VERSION ""

NS_ :

BS_:

BU_: VT OPC

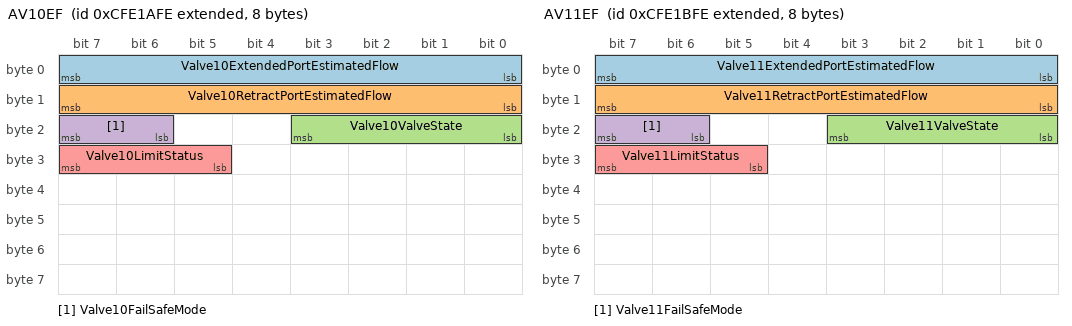
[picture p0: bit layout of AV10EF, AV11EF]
BO_ 2365463294 AV10EF: 8 Vector__XXX
 SG_ Valve10ExtendedPortEstimatedFlow : 0|8@1+ (1,-125) [-125|125] "%" Vector__XXX
 SG_ Valve10RetractPortEstimatedFlow : 8|8@1+ (1,-125) [-125|125] "%" Vector__XXX
 SG_ Valve10ValveState : 16|4@1+ (1,0) [0|15] "" Vector__XXX
 SG_ Valve10FailSafeMode : 22|2@1+ (1,0) [0|3] "" Vector__XXX
 SG_ Valve10LimitStatus : 29|3@1+ (1,0) [0|7] "" Vector__XXX

BO_ 2365463550 AV11EF: 8 Vector__XXX
 SG_ Valve11ExtendedPortEstimatedFlow : 0|8@1+ (1,-125) [-125|125] "%" Vector__XXX
 SG_ Valve11RetractPortEstimatedFlow : 8|8@1+ (1,-125) [-125|125] "%" Vector__XXX
 SG_ Valve11ValveState : 16|4@1+ (1,0) [0|15] "" Vector__XXX
 SG_ Valve11FailSafeMode : 22|2@1+ (1,0) [0|3] "" Vector__XXX
 SG_ Valve11LimitStatus : 29|3@1+ (1,0) [0|7] "" Vector__XXX

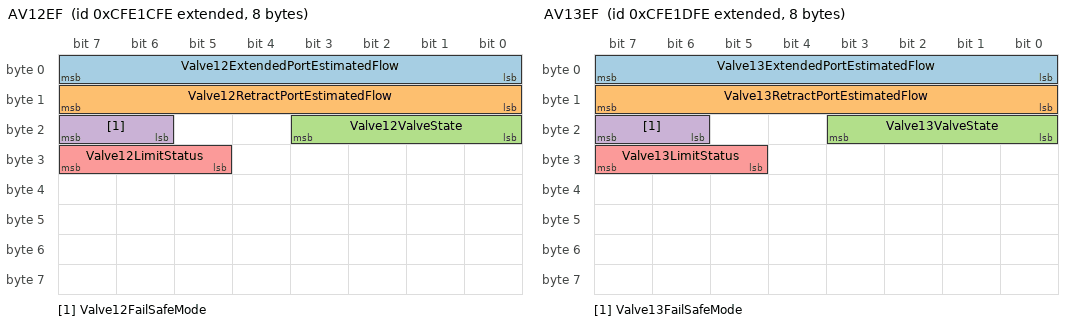
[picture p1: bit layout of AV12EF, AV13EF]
BO_ 2365463806 AV12EF: 8 Vector__XXX
 SG_ Valve12ExtendedPortEstimatedFlow : 0|8@1+ (1,-125) [-125|125] "%" Vector__XXX
 SG_ Valve12RetractPortEstimatedFlow : 8|8@1+ (1,-125) [-125|125] "%" Vector__XXX
 SG_ Valve12ValveState : 16|4@1+ (1,0) [0|15] "" Vector__XXX
 SG_ Valve12FailSafeMode : 22|2@1+ (1,0) [0|3] "" Vector__XXX
 SG_ Valve12LimitStatus : 29|3@1+ (1,0) [0|7] "" Vector__XXX

BO_ 2365464062 AV13EF: 8 Vector__XXX
 SG_ Valve13ExtendedPortEstimatedFlow : 0|8@1+ (1,-125) [-125|125] "%" Vector__XXX
 SG_ Valve13RetractPortEstimatedFlow : 8|8@1+ (1,-125) [-125|125] "%" Vector__XXX
 SG_ Valve13ValveState : 16|4@1+ (1,0) [0|15] "" Vector__XXX
 SG_ Valve13FailSafeMode : 22|2@1+ (1,0) [0|3] "" Vector__XXX
 SG_ Valve13LimitStatus : 29|3@1+ (1,0) [0|7] "" Vector__XXX

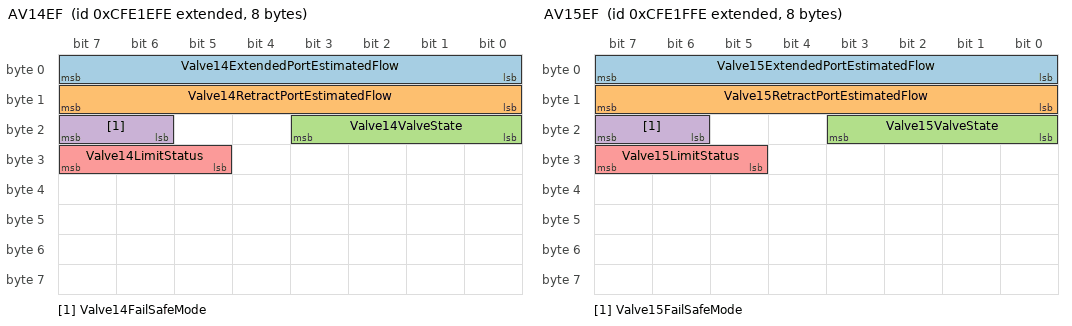
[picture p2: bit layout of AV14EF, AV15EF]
BO_ 2365464318 AV14EF: 8 Vector__XXX
 SG_ Valve14ExtendedPortEstimatedFlow : 0|8@1+ (1,-125) [-125|125] "%" Vector__XXX
 SG_ Valve14RetractPortEstimatedFlow : 8|8@1+ (1,-125) [-125|125] "%" Vector__XXX
 SG_ Valve14ValveState : 16|4@1+ (1,0) [0|15] "" Vector__XXX
 SG_ Valve14FailSafeMode : 22|2@1+ (1,0) [0|3] "" Vector__XXX
 SG_ Valve14LimitStatus : 29|3@1+ (1,0) [0|7] "" Vector__XXX

BO_ 2365464574 AV15EF: 8 Vector__XXX
 SG_ Valve15ExtendedPortEstimatedFlow : 0|8@1+ (1,-125) [-125|125] "%" Vector__XXX
 SG_ Valve15RetractPortEstimatedFlow : 8|8@1+ (1,-125) [-125|125] "%" Vector__XXX
 SG_ Valve15ValveState : 16|4@1+ (1,0) [0|15] "" Vector__XXX
 SG_ Valve15FailSafeMode : 22|2@1+ (1,0) [0|3] "" Vector__XXX
 SG_ Valve15LimitStatus : 29|3@1+ (1,0) [0|7] "" Vector__XXX

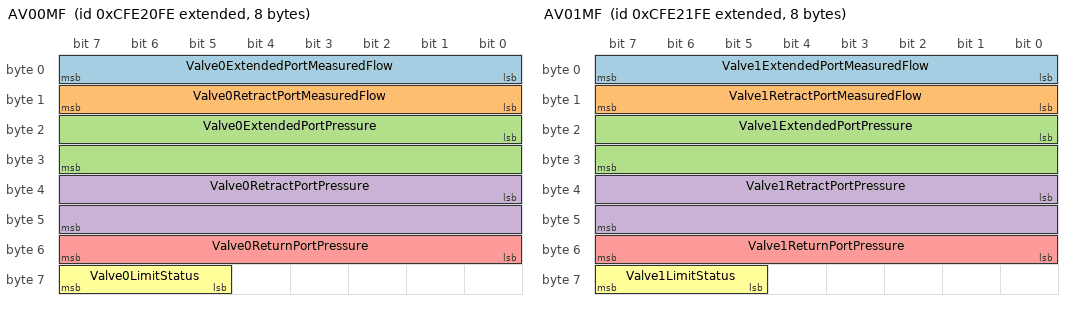
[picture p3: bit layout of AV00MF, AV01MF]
BO_ 2365464830 AV00MF: 8 Vector__XXX
 SG_ Valve0ExtendedPortMeasuredFlow : 0|8@1+ (1,-125) [-125|125] "%" Vector__XXX
 SG_ Valve0RetractPortMeasuredFlow : 8|8@1+ (1,-125) [-125|125] "%" Vector__XXX
 SG_ Valve0ExtendedPortPressure : 16|16@1+ (5,0) [0|321275] "kPa" Vector__XXX
 SG_ Valve0RetractPortPressure : 32|16@1+ (5,0) [0|321275] "kPa" Vector__XXX
 SG_ Valve0ReturnPortPressure : 48|8@1+ (16,0) [0|4000] "kPa" Vector__XXX
 SG_ Valve0LimitStatus : 61|3@1+ (1,0) [0|7] "" Vector__XXX

BO_ 2365465086 AV01MF: 8 Vector__XXX
 SG_ Valve1ExtendedPortMeasuredFlow : 0|8@1+ (1,-125) [-125|125] "%" Vector__XXX
 SG_ Valve1RetractPortMeasuredFlow : 8|8@1+ (1,-125) [-125|125] "%" Vector__XXX
 SG_ Valve1ExtendedPortPressure : 16|16@1+ (5,0) [0|321275] "kPa" Vector__XXX
 SG_ Valve1RetractPortPressure : 32|16@1+ (5,0) [0|321275] "kPa" Vector__XXX
 SG_ Valve1ReturnPortPressure : 48|8@1+ (16,0) [0|4000] "kPa" Vector__XXX
 SG_ Valve1LimitStatus : 61|3@1+ (1,0) [0|7] "" Vector__XXX

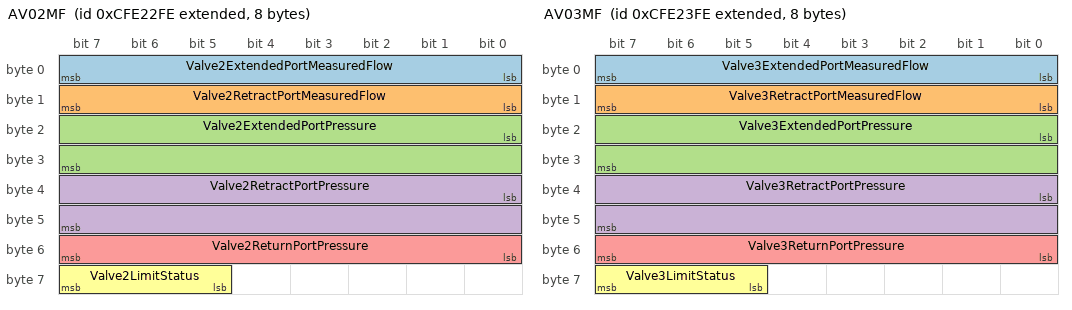
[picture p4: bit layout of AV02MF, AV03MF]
BO_ 2365465342 AV02MF: 8 Vector__XXX
 SG_ Valve2ExtendedPortMeasuredFlow : 0|8@1+ (1,-125) [-125|125] "%" Vector__XXX
 SG_ Valve2RetractPortMeasuredFlow : 8|8@1+ (1,-125) [-125|125] "%" Vector__XXX
 SG_ Valve2ExtendedPortPressure : 16|16@1+ (5,0) [0|321275] "kPa" Vector__XXX
 SG_ Valve2RetractPortPressure : 32|16@1+ (5,0) [0|321275] "kPa" Vector__XXX
 SG_ Valve2ReturnPortPressure : 48|8@1+ (16,0) [0|4000] "kPa" Vector__XXX
 SG_ Valve2LimitStatus : 61|3@1+ (1,0) [0|7] "" Vector__XXX

BO_ 2365465598 AV03MF: 8 Vector__XXX
 SG_ Valve3ExtendedPortMeasuredFlow : 0|8@1+ (1,-125) [-125|125] "%" Vector__XXX
 SG_ Valve3RetractPortMeasuredFlow : 8|8@1+ (1,-125) [-125|125] "%" Vector__XXX
 SG_ Valve3ExtendedPortPressure : 16|16@1+ (5,0) [0|321275] "kPa" Vector__XXX
 SG_ Valve3RetractPortPressure : 32|16@1+ (5,0) [0|321275] "kPa" Vector__XXX
 SG_ Valve3ReturnPortPressure : 48|8@1+ (16,0) [0|4000] "kPa" Vector__XXX
 SG_ Valve3LimitStatus : 61|3@1+ (1,0) [0|7] "" Vector__XXX

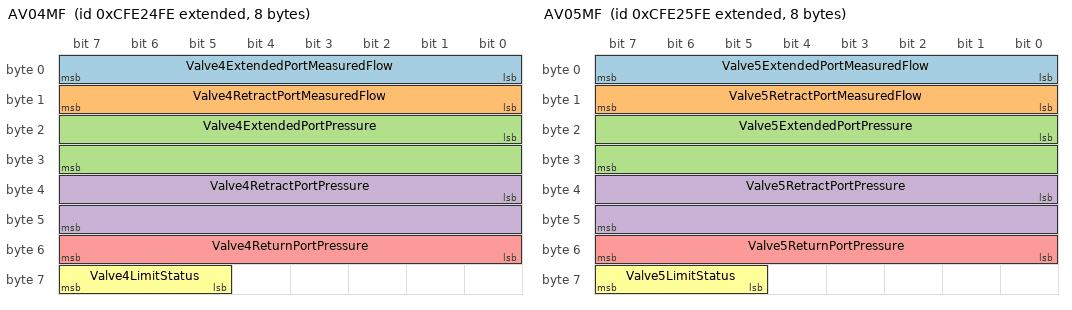
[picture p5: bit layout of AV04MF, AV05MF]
BO_ 2365465854 AV04MF: 8 Vector__XXX
 SG_ Valve4ExtendedPortMeasuredFlow : 0|8@1+ (1,-125) [-125|125] "%" Vector__XXX
 SG_ Valve4RetractPortMeasuredFlow : 8|8@1+ (1,-125) [-125|125] "%" Vector__XXX
 SG_ Valve4ExtendedPortPressure : 16|16@1+ (5,0) [0|321275] "kPa" Vector__XXX
 SG_ Valve4RetractPortPressure : 32|16@1+ (5,0) [0|321275] "kPa" Vector__XXX
 SG_ Valve4ReturnPortPressure : 48|8@1+ (16,0) [0|4000] "kPa" Vector__XXX
 SG_ Valve4LimitStatus : 61|3@1+ (1,0) [0|7] "" Vector__XXX

BO_ 2365466110 AV05MF: 8 Vector__XXX
 SG_ Valve5ExtendedPortMeasuredFlow : 0|8@1+ (1,-125) [-125|125] "%" Vector__XXX
 SG_ Valve5RetractPortMeasuredFlow : 8|8@1+ (1,-125) [-125|125] "%" Vector__XXX
 SG_ Valve5ExtendedPortPressure : 16|16@1+ (5,0) [0|321275] "kPa" Vector__XXX
 SG_ Valve5RetractPortPressure : 32|16@1+ (5,0) [0|321275] "kPa" Vector__XXX
 SG_ Valve5ReturnPortPressure : 48|8@1+ (16,0) [0|4000] "kPa" Vector__XXX
 SG_ Valve5LimitStatus : 61|3@1+ (1,0) [0|7] "" Vector__XXX

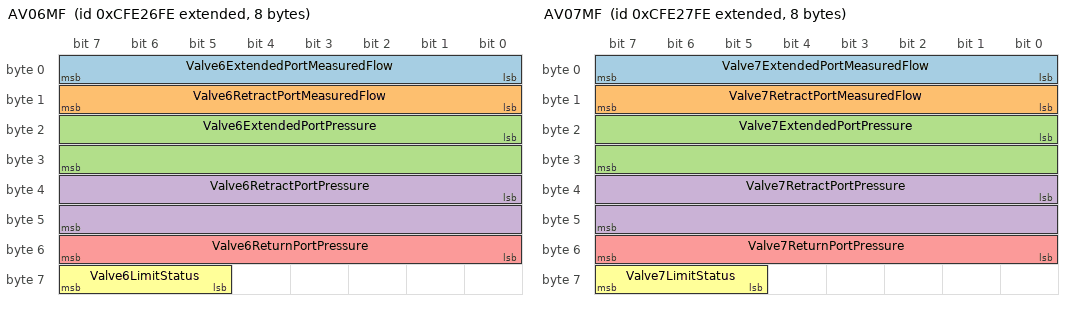
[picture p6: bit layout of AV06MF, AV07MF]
BO_ 2365466366 AV06MF: 8 Vector__XXX
 SG_ Valve6ExtendedPortMeasuredFlow : 0|8@1+ (1,-125) [-125|125] "%" Vector__XXX
 SG_ Valve6RetractPortMeasuredFlow : 8|8@1+ (1,-125) [-125|125] "%" Vector__XXX
 SG_ Valve6ExtendedPortPressure : 16|16@1+ (5,0) [0|321275] "kPa" Vector__XXX
 SG_ Valve6RetractPortPressure : 32|16@1+ (5,0) [0|321275] "kPa" Vector__XXX
 SG_ Valve6ReturnPortPressure : 48|8@1+ (16,0) [0|4000] "kPa" Vector__XXX
 SG_ Valve6LimitStatus : 61|3@1+ (1,0) [0|7] "" Vector__XXX

BO_ 2365466622 AV07MF: 8 Vector__XXX
 SG_ Valve7ExtendedPortMeasuredFlow : 0|8@1+ (1,-125) [-125|125] "%" Vector__XXX
 SG_ Valve7RetractPortMeasuredFlow : 8|8@1+ (1,-125) [-125|125] "%" Vector__XXX
 SG_ Valve7ExtendedPortPressure : 16|16@1+ (5,0) [0|321275] "kPa" Vector__XXX
 SG_ Valve7RetractPortPressure : 32|16@1+ (5,0) [0|321275] "kPa" Vector__XXX
 SG_ Valve7ReturnPortPressure : 48|8@1+ (16,0) [0|4000] "kPa" Vector__XXX
 SG_ Valve7LimitStatus : 61|3@1+ (1,0) [0|7] "" Vector__XXX

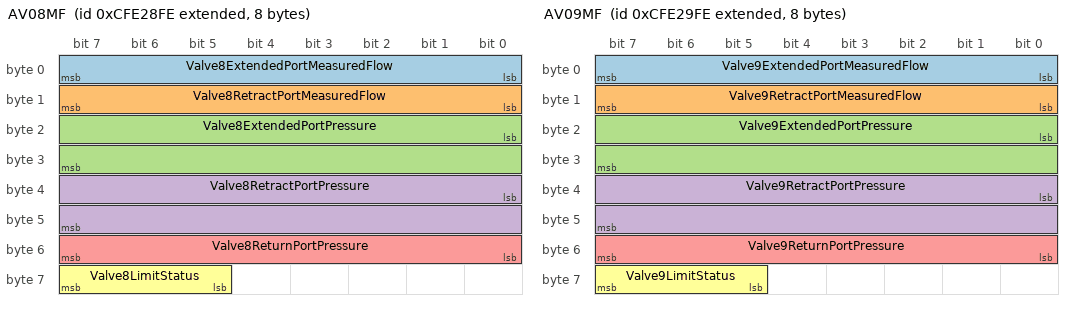
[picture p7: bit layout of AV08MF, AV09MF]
BO_ 2365466878 AV08MF: 8 Vector__XXX
 SG_ Valve8ExtendedPortMeasuredFlow : 0|8@1+ (1,-125) [-125|125] "%" Vector__XXX
 SG_ Valve8RetractPortMeasuredFlow : 8|8@1+ (1,-125) [-125|125] "%" Vector__XXX
 SG_ Valve8ExtendedPortPressure : 16|16@1+ (5,0) [0|321275] "kPa" Vector__XXX
 SG_ Valve8RetractPortPressure : 32|16@1+ (5,0) [0|321275] "kPa" Vector__XXX
 SG_ Valve8ReturnPortPressure : 48|8@1+ (16,0) [0|4000] "kPa" Vector__XXX
 SG_ Valve8LimitStatus : 61|3@1+ (1,0) [0|7] "" Vector__XXX

BO_ 2365467134 AV09MF: 8 Vector__XXX
 SG_ Valve9ExtendedPortMeasuredFlow : 0|8@1+ (1,-125) [-125|125] "%" Vector__XXX
 SG_ Valve9RetractPortMeasuredFlow : 8|8@1+ (1,-125) [-125|125] "%" Vector__XXX
 SG_ Valve9ExtendedPortPressure : 16|16@1+ (5,0) [0|321275] "kPa" Vector__XXX
 SG_ Valve9RetractPortPressure : 32|16@1+ (5,0) [0|321275] "kPa" Vector__XXX
 SG_ Valve9ReturnPortPressure : 48|8@1+ (16,0) [0|4000] "kPa" Vector__XXX
 SG_ Valve9LimitStatus : 61|3@1+ (1,0) [0|7] "" Vector__XXX

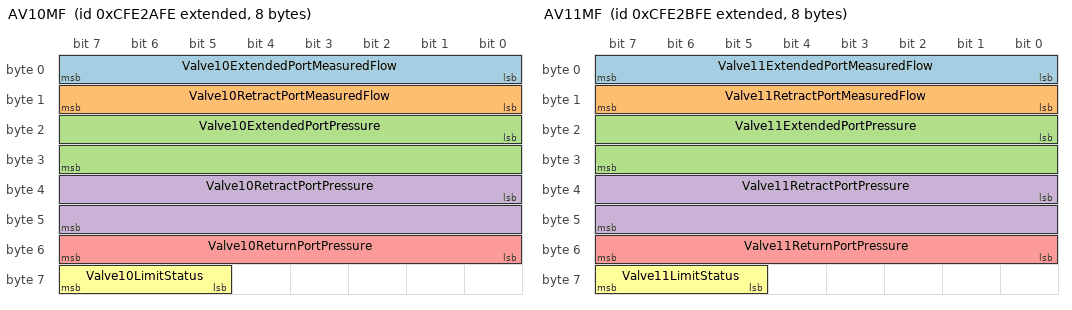
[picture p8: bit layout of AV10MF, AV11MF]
BO_ 2365467390 AV10MF: 8 Vector__XXX
 SG_ Valve10ExtendedPortMeasuredFlow : 0|8@1+ (1,-125) [-125|125] "%" Vector__XXX
 SG_ Valve10RetractPortMeasuredFlow : 8|8@1+ (1,-125) [-125|125] "%" Vector__XXX
 SG_ Valve10ExtendedPortPressure : 16|16@1+ (5,0) [0|321275] "kPa" Vector__XXX
 SG_ Valve10RetractPortPressure : 32|16@1+ (5,0) [0|321275] "kPa" Vector__XXX
 SG_ Valve10ReturnPortPressure : 48|8@1+ (16,0) [0|4000] "kPa" Vector__XXX
 SG_ Valve10LimitStatus : 61|3@1+ (1,0) [0|7] "" Vector__XXX

BO_ 2365467646 AV11MF: 8 Vector__XXX
 SG_ Valve11ExtendedPortMeasuredFlow : 0|8@1+ (1,-125) [-125|125] "%" Vector__XXX
 SG_ Valve11RetractPortMeasuredFlow : 8|8@1+ (1,-125) [-125|125] "%" Vector__XXX
 SG_ Valve11ExtendedPortPressure : 16|16@1+ (5,0) [0|321275] "kPa" Vector__XXX
 SG_ Valve11RetractPortPressure : 32|16@1+ (5,0) [0|321275] "kPa" Vector__XXX
 SG_ Valve11ReturnPortPressure : 48|8@1+ (16,0) [0|4000] "kPa" Vector__XXX
 SG_ Valve11LimitStatus : 61|3@1+ (1,0) [0|7] "" Vector__XXX

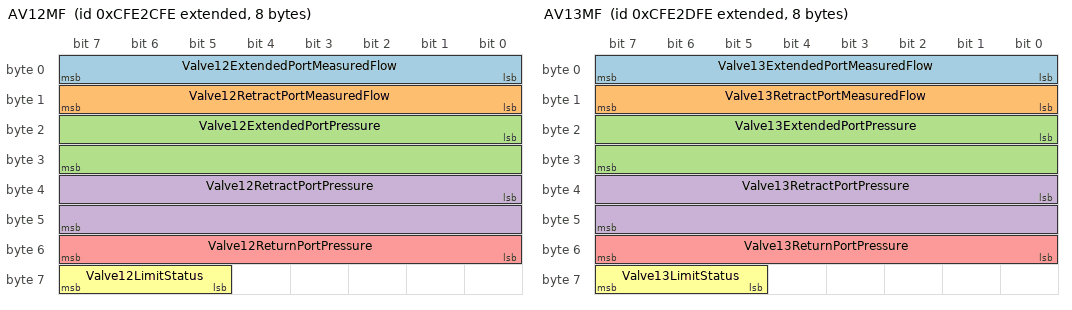
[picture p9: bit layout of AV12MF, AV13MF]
BO_ 2365467902 AV12MF: 8 Vector__XXX
 SG_ Valve12ExtendedPortMeasuredFlow : 0|8@1+ (1,-125) [-125|125] "%" Vector__XXX
 SG_ Valve12RetractPortMeasuredFlow : 8|8@1+ (1,-125) [-125|125] "%" Vector__XXX
 SG_ Valve12ExtendedPortPressure : 16|16@1+ (5,0) [0|321275] "kPa" Vector__XXX
 SG_ Valve12RetractPortPressure : 32|16@1+ (5,0) [0|321275] "kPa" Vector__XXX
 SG_ Valve12ReturnPortPressure : 48|8@1+ (16,0) [0|4000] "kPa" Vector__XXX
 SG_ Valve12LimitStatus : 61|3@1+ (1,0) [0|7] "" Vector__XXX

BO_ 2365468158 AV13MF: 8 Vector__XXX
 SG_ Valve13ExtendedPortMeasuredFlow : 0|8@1+ (1,-125) [-125|125] "%" Vector__XXX
 SG_ Valve13RetractPortMeasuredFlow : 8|8@1+ (1,-125) [-125|125] "%" Vector__XXX
 SG_ Valve13ExtendedPortPressure : 16|16@1+ (5,0) [0|321275] "kPa" Vector__XXX
 SG_ Valve13RetractPortPressure : 32|16@1+ (5,0) [0|321275] "kPa" Vector__XXX
 SG_ Valve13ReturnPortPressure : 48|8@1+ (16,0) [0|4000] "kPa" Vector__XXX
 SG_ Valve13LimitStatus : 61|3@1+ (1,0) [0|7] "" Vector__XXX

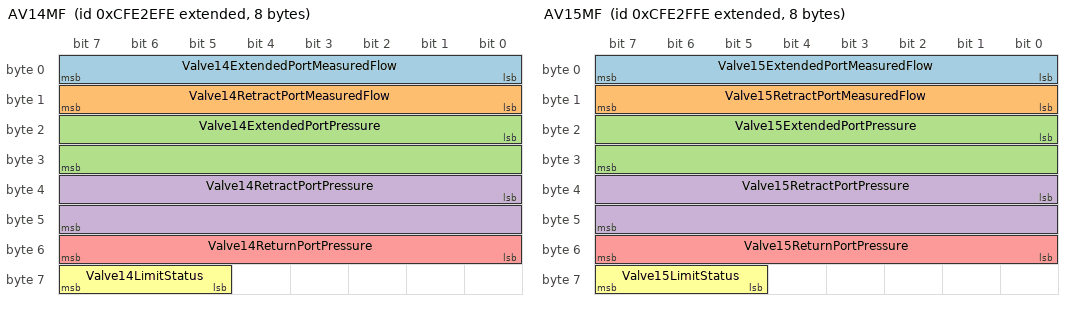
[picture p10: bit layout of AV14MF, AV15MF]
BO_ 2365468414 AV14MF: 8 Vector__XXX
 SG_ Valve14ExtendedPortMeasuredFlow : 0|8@1+ (1,-125) [-125|125] "%" Vector__XXX
 SG_ Valve14RetractPortMeasuredFlow : 8|8@1+ (1,-125) [-125|125] "%" Vector__XXX
 SG_ Valve14ExtendedPortPressure : 16|16@1+ (5,0) [0|321275] "kPa" Vector__XXX
 SG_ Valve14RetractPortPressure : 32|16@1+ (5,0) [0|321275] "kPa" Vector__XXX
 SG_ Valve14ReturnPortPressure : 48|8@1+ (16,0) [0|4000] "kPa" Vector__XXX
 SG_ Valve14LimitStatus : 61|3@1+ (1,0) [0|7] "" Vector__XXX

BO_ 2365468670 AV15MF: 8 Vector__XXX
 SG_ Valve15ExtendedPortMeasuredFlow : 0|8@1+ (1,-125) [-125|125] "%" Vector__XXX
 SG_ Valve15RetractPortMeasuredFlow : 8|8@1+ (1,-125) [-125|125] "%" Vector__XXX
 SG_ Valve15ExtendedPortPressure : 16|16@1+ (5,0) [0|321275] "kPa" Vector__XXX
 SG_ Valve15RetractPortPressure : 32|16@1+ (5,0) [0|321275] "kPa" Vector__XXX
 SG_ Valve15ReturnPortPressure : 48|8@1+ (16,0) [0|4000] "kPa" Vector__XXX
 SG_ Valve15LimitStatus : 61|3@1+ (1,0) [0|7] "" Vector__XXX

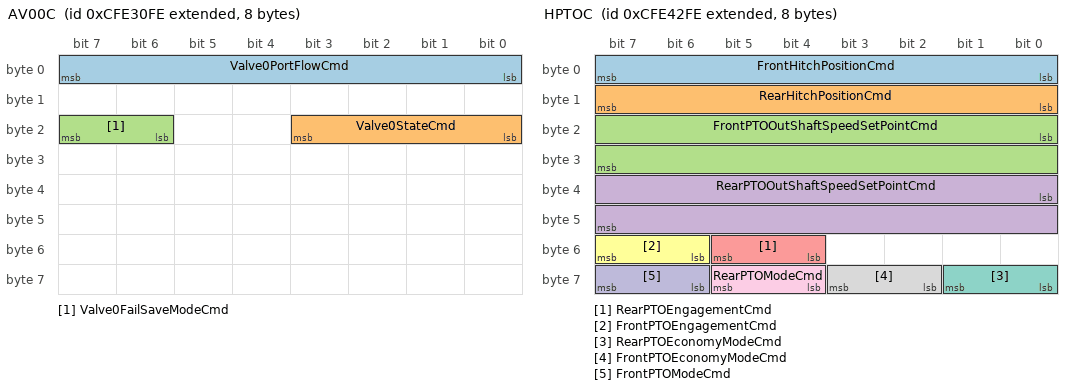
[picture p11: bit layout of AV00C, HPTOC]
BO_ 2365468926 AV00C: 8 Vector__XXX
 SG_ Valve0PortFlowCmd : 0|8@1+ (0.4,0) [0|100] "%" Vector__XXX
 SG_ Valve0StateCmd : 16|4@1+ (1,0) [0|15] "" Vector__XXX
 SG_ Valve0FailSaveModeCmd : 22|2@1+ (1,0) [0|3] "" Vector__XXX

BO_ 2365469182 AV01C: 8 Vector__XXX
 SG_ Valve1PortFlowCmd : 0|8@1+ (0.4,0) [0|100] "%" Vector__XXX
 SG_ Valve1StateCmd : 16|4@1+ (1,0) [0|15] "" Vector__XXX
 SG_ Valve1FailSaveModeCmd : 22|2@1+ (1,0) [0|3] "" Vector__XXX

BO_ 2365469438 AV02C: 8 Vector__XXX
 SG_ Valve2PortFlowCmd : 0|8@1+ (0.4,0) [0|100] "%" Vector__XXX
 SG_ Valve2StateCmd : 16|4@1+ (1,0) [0|15] "" Vector__XXX
 SG_ Valve2FailSaveModeCmd : 22|2@1+ (1,0) [0|3] "" Vector__XXX

BO_ 2365469694 AV03C: 8 Vector__XXX
 SG_ Valve3PortFlowCmd : 0|8@1+ (0.4,0) [0|100] "%" Vector__XXX
 SG_ Valve3StateCmd : 16|4@1+ (1,0) [0|15] "" Vector__XXX
 SG_ Valve3FailSaveModeCmd : 22|2@1+ (1,0) [0|3] "" Vector__XXX

BO_ 2365469950 AV04C: 8 Vector__XXX
 SG_ Valve4PortFlowCmd : 0|8@1+ (0.4,0) [0|100] "%" Vector__XXX
 SG_ Valve4StateCmd : 16|4@1+ (1,0) [0|15] "" Vector__XXX
 SG_ Valve4FailSaveModeCmd : 22|2@1+ (1,0) [0|3] "" Vector__XXX

BO_ 2365470206 AV05C: 8 Vector__XXX
 SG_ Valve5PortFlowCmd : 0|8@1+ (0.4,0) [0|100] "%" Vector__XXX
 SG_ Valve5StateCmd : 16|4@1+ (1,0) [0|15] "" Vector__XXX
 SG_ Valve5FailSaveModeCmd : 22|2@1+ (1,0) [0|3] "" Vector__XXX

BO_ 2365470462 AV06C: 8 Vector__XXX
 SG_ Valve6PortFlowCmd : 0|8@1+ (0.4,0) [0|100] "%" Vector__XXX
 SG_ Valve6StateCmd : 16|4@1+ (1,0) [0|15] "" Vector__XXX
 SG_ Valve6FailSaveModeCmd : 22|2@1+ (1,0) [0|3] "" Vector__XXX

BO_ 2365470718 AV07C: 8 Vector__XXX
 SG_ Valve7PortFlowCmd : 0|8@1+ (0.4,0) [0|100] "%" Vector__XXX
 SG_ Valve7StateCmd : 16|4@1+ (1,0) [0|15] "" Vector__XXX
 SG_ Valve7FailSaveModeCmd : 22|2@1+ (1,0) [0|3] "" Vector__XXX

BO_ 2365470974 AV08C: 8 Vector__XXX
 SG_ Valve8PortFlowCmd : 0|8@1+ (0.4,0) [0|100] "%" Vector__XXX
 SG_ Valve8StateCmd : 16|4@1+ (1,0) [0|15] "" Vector__XXX
 SG_ Valve8FailSaveModeCmd : 22|2@1+ (1,0) [0|3] "" Vector__XXX

BO_ 2365471230 AV09C: 8 Vector__XXX
 SG_ Valve9PortFlowCmd : 0|8@1+ (0.4,0) [0|100] "%" Vector__XXX
 SG_ Valve9StateCmd : 16|4@1+ (1,0) [0|15] "" Vector__XXX
 SG_ Valve9FailSaveModeCmd : 22|2@1+ (1,0) [0|3] "" Vector__XXX

BO_ 2365471486 AV10C: 8 Vector__XXX
 SG_ Valve10PortFlowCmd : 0|8@1+ (0.4,0) [0|100] "%" Vector__XXX
 SG_ Valve10StateCmd : 16|4@1+ (1,0) [0|15] "" Vector__XXX
 SG_ Valve10FailSaveModeCmd : 22|2@1+ (1,0) [0|3] "" Vector__XXX

BO_ 2365471742 AV11C: 8 Vector__XXX
 SG_ Valve11PortFlowCmd : 0|8@1+ (0.4,0) [0|100] "%" Vector__XXX
 SG_ Valve11StateCmd : 16|4@1+ (1,0) [0|15] "" Vector__XXX
 SG_ Valve11FailSaveModeCmd : 22|2@1+ (1,0) [0|3] "" Vector__XXX

BO_ 2365471998 AV12C: 8 Vector__XXX
 SG_ Valve12PortFlowCmd : 0|8@1+ (0.4,0) [0|100] "%" Vector__XXX
 SG_ Valve12StateCmd : 16|4@1+ (1,0) [0|15] "" Vector__XXX
 SG_ Valve12FailSaveModeCmd : 22|2@1+ (1,0) [0|3] "" Vector__XXX

BO_ 2365472254 AV13C: 8 Vector__XXX
 SG_ Valve13PortFlowCmd : 0|8@1+ (0.4,0) [0|100] "%" Vector__XXX
 SG_ Valve13StateCmd : 16|4@1+ (1,0) [0|15] "" Vector__XXX
 SG_ Valve13FailSaveModeCmd : 22|2@1+ (1,0) [0|3] "" Vector__XXX

BO_ 2365472510 AV14C: 8 Vector__XXX
 SG_ Valve14PortFlowCmd : 0|8@1+ (0.4,0) [0|100] "%" Vector__XXX
 SG_ Valve14StateCmd : 16|4@1+ (1,0) [0|15] "" Vector__XXX
 SG_ Valve14FailSaveModeCmd : 22|2@1+ (1,0) [0|3] "" Vector__XXX

BO_ 2365472766 AV15C: 8 Vector__XXX
 SG_ Valve15PortFlowCmd : 0|8@1+ (0.4,0) [0|100] "%" Vector__XXX
 SG_ Valve15StateCmd : 16|4@1+ (1,0) [0|15] "" Vector__XXX
 SG_ Valve15FailSaveModeCmd : 22|2@1+ (1,0) [0|3] "" Vector__XXX

BO_ 2566799614 LID: 8 Vector__XXX
 SG_ DaytimeRunningLightData : 0|2@1+ (1,0) [0|3] "" Vector__XXX
 SG_ AlternateHeadLightData : 2|2@1+ (1,0) [0|3] "" Vector__XXX
 SG_ LowBeamHeadLightData : 4|2@1+ (1,0) [0|3] "" Vector__XXX
 SG_ HighBeamHeadLightData : 6|2@1+ (1,0) [0|3] "" Vector__XXX
 SG_ TractorFrontFogLightData : 8|2@1+ (1,0) [0|3] "" Vector__XXX
 SG_ RotationBeaconLightData : 10|2@1+ (1,0) [0|3] "" Vector__XXX
 SG_ RightTurnSignalLightData : 12|2@1+ (1,0) [0|3] "" Vector__XXX
 SG_ LeftTurnSignalLightData : 14|2@1+ (1,0) [0|3] "" Vector__XXX
 SG_ BackUpLightAndAlarmHornData : 16|2@1+ (1,0) [0|3] "" Vector__XXX
 SG_ CentreStopLightData : 18|2@1+ (1,0) [0|3] "" Vector__XXX
 SG_ RightStopLightData : 20|2@1+ (1,0) [0|3] "" Vector__XXX
 SG_ LefttStopLightData : 22|2@1+ (1,0) [0|3] "" Vector__XXX
 SG_ ImplementClearanceLightData : 24|2@1+ (1,0) [0|3] "" Vector__XXX
 SG_ TractorClearanceLightData : 26|2@1+ (1,0) [0|3] "" Vector__XXX
 SG_ ImplementMarkerLightData : 28|2@1+ (1,0) [0|3] "" Vector__XXX
 SG_ TractorMarkerLightData : 30|2@1+ (1,0) [0|3] "" Vector__XXX
 SG_ RearFogLightData : 32|2@1+ (1,0) [0|3] "" Vector__XXX
 SG_ TractorUndersideWorkLightData : 34|2@1+ (1,0) [0|3] "" Vector__XXX
 SG_ TractorRearLowWorkLightData : 36|2@1+ (1,0) [0|3] "" Vector__XXX
 SG_ TractorRearHighWorkLightData : 38|2@1+ (1,0) [0|3] "" Vector__XXX
 SG_ TractorSideLowWorkLightData : 40|2@1+ (1,0) [0|3] "" Vector__XXX
 SG_ TractorSideHighWorkLightData : 42|2@1+ (1,0) [0|3] "" Vector__XXX
 SG_ TractorFrontLowWorkLightData : 44|2@1+ (1,0) [0|3] "" Vector__XXX
 SG_ TractorFrontHighWorkLightData : 46|2@1+ (1,0) [0|3] "" Vector__XXX
 SG_ ImplementOEMOption2LightData : 48|2@1+ (1,0) [0|3] "" Vector__XXX
 SG_ ImplementOEMOption1LightData : 50|2@1+ (1,0) [0|3] "" Vector__XXX
 SG_ ImplementRightForwardLightData : 52|2@1+ (1,0) [0|3] "" Vector__XXX
 SG_ ImplementLeftForwardLightData : 54|2@1+ (1,0) [0|3] "" Vector__XXX
 SG_ ImplRightFacingWorkLightData : 58|2@1+ (1,0) [0|3] "" Vector__XXX
 SG_ ImplLeftFacingWorkLightData : 60|2@1+ (1,0) [0|3] "" Vector__XXX
 SG_ ImplementRearWorkLightData : 62|2@1+ (1,0) [0|3] "" Vector__XXX

BO_ 2365473278 LCMD: 8 Vector__XXX
 SG_ DaytimeRunningLightCmd : 0|2@1+ (1,0) [0|3] "" Vector__XXX
 SG_ AlternateHeadLightCmd : 2|2@1+ (1,0) [0|3] "" Vector__XXX
 SG_ LowBeamHeadLightCmd : 4|2@1+ (1,0) [0|3] "" Vector__XXX
 SG_ HighBeamHeadLightCmd : 6|2@1+ (1,0) [0|3] "" Vector__XXX
 SG_ TractorFrontFogLightCmd : 8|2@1+ (1,0) [0|3] "" Vector__XXX
 SG_ RotatingBeaconLightCmd : 10|2@1+ (1,0) [0|3] "" Vector__XXX
 SG_ RightTurnSignalLightCmd : 12|2@1+ (1,0) [0|3] "" Vector__XXX
 SG_ LeftTurnSignalLightCmd : 14|2@1+ (1,0) [0|3] "" Vector__XXX
 SG_ BackUpLightAndAlarmHornCmd : 16|2@1+ (1,0) [0|3] "" Vector__XXX
 SG_ CentreStopLightCmd : 18|2@1+ (1,0) [0|3] "" Vector__XXX
 SG_ RightStopLightCmd : 20|2@1+ (1,0) [0|3] "" Vector__XXX
 SG_ LeftStopLightCmd : 22|2@1+ (1,0) [0|3] "" Vector__XXX
 SG_ ImplementClearanceLightCmd : 24|2@1+ (1,0) [0|3] "" Vector__XXX
 SG_ TractorClearanceLightCmd : 26|2@1+ (1,0) [0|3] "" Vector__XXX
 SG_ ImplementMarkerLightCmd : 28|2@1+ (1,0) [0|3] "" Vector__XXX
 SG_ TractorMarkerLightCmd : 30|2@1+ (1,0) [0|3] "" Vector__XXX
 SG_ RearFogLightCmd : 32|2@1+ (1,0) [0|3] "" Vector__XXX
 SG_ TractorUndersideWorkLightCmd : 34|2@1+ (1,0) [0|3] "" Vector__XXX
 SG_ TractorRearLowWorkLightCmd : 36|2@1+ (1,0) [0|3] "" Vector__XXX
 SG_ TractorRearHighWorkLightCmd : 38|2@1+ (1,0) [0|3] "" Vector__XXX
 SG_ TractorSideLowWorkLightCmd : 40|2@1+ (1,0) [0|3] "" Vector__XXX
 SG_ TractorSideHighWorkLightCmd : 42|2@1+ (1,0) [0|3] "" Vector__XXX
 SG_ TractorFrontLowWorkLightCmd : 44|2@1+ (1,0) [0|3] "" Vector__XXX
 SG_ TractorFrontHighWorkLightCmd : 46|2@1+ (1,0) [0|3] "" Vector__XXX
 SG_ ImplementOEMOption2LightCmd : 48|2@1+ (1,0) [0|3] "" Vector__XXX
 SG_ ImplementOEMOption1LightCmd : 50|2@1+ (1,0) [0|3] "" Vector__XXX
 SG_ ImplementRightForwardLightCmd : 52|2@1+ (1,0) [0|3] "" Vector__XXX
 SG_ ImplementLeftForwardLightCmd : 54|2@1+ (1,0) [0|3] "" Vector__XXX
 SG_ LightingDataRequestCmd : 56|2@1+ (1,0) [0|3] "" Vector__XXX
 SG_ ImplementRightFacingWorkLightCmd : 58|2@1+ (1,0) [0|3] "" Vector__XXX
 SG_ ImplementLeftFacingWorkLightCmd : 60|2@1+ (1,0) [0|3] "" Vector__XXX
 SG_ ImplementRearWorkLightCmd : 62|2@1+ (1,0) [0|3] "" Vector__XXX

BO_ 2365473534 HPTOC: 8 Vector__XXX
 SG_ FrontHitchPositionCmd : 0|8@1+ (0.4,0) [0|100] "%" Vector__XXX
 SG_ RearHitchPositionCmd : 8|8@1+ (0.4,0) [0|100] "%" Vector__XXX
 SG_ FrontPTOOutShaftSpeedSetPointCmd : 16|16@1+ (0.125,0) [0|8031.875] "1/min" Vector__XXX
 SG_ RearPTOOutShaftSpeedSetPointCmd : 32|16@1+ (0.125,0) [0|801.875] "1/min" Vector__XXX
 SG_ RearPTOEngagementCmd : 52|2@1+ (1,0) [0|3] "" Vector__XXX
 SG_ FrontPTOEngagementCmd : 54|2@1+ (1,0) [0|3] "" Vector__XXX
 SG_ RearPTOEconomyModeCmd : 56|2@1+ (1,0) [0|3] "" Vector__XXX
 SG_ FrontPTOEconomyModeCmd : 58|2@1+ (1,0) [0|3] "" Vector__XXX
 SG_ RearPTOModeCmd : 60|2@1+ (1,0) [0|3] "" Vector__XXX
 SG_ FrontPTOModeCmd : 62|2@1+ (1,0) [0|3] "" Vector__XXX

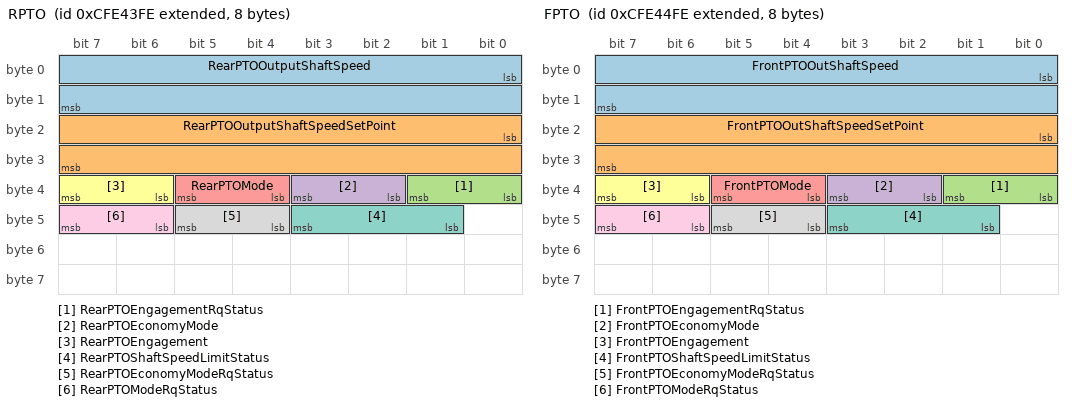
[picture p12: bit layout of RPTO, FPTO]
BO_ 2365473790 RPTO: 8 Vector__XXX
 SG_ RearPTOOutputShaftSpeed : 0|16@1+ (0.125,0) [0|8031.88] "1/min" Vector__XXX
 SG_ RearPTOOutputShaftSpeedSetPoint : 16|16@1+ (0.125,0) [0|8031.88] "1/min" Vector__XXX
 SG_ RearPTOEngagementRqStatus : 32|2@1+ (1,0) [0|3] "" Vector__XXX
 SG_ RearPTOEconomyMode : 34|2@1+ (1,0) [0|3] "" Vector__XXX
 SG_ RearPTOMode : 36|2@1+ (1,0) [0|3] "" Vector__XXX
 SG_ RearPTOEngagement : 38|2@1+ (1,0) [0|3] "" Vector__XXX
 SG_ RearPTOShaftSpeedLimitStatus : 41|3@1+ (1,0) [0|7] "" Vector__XXX
 SG_ RearPTOEconomyModeRqStatus : 44|2@1+ (1,0) [0|3] "" Vector__XXX
 SG_ RearPTOModeRqStatus : 46|2@1+ (1,0) [0|3] "" Vector__XXX

BO_ 2365474046 FPTO: 8 Vector__XXX
 SG_ FrontPTOOutShaftSpeed : 0|16@1+ (0.125,0) [0|8031.88] "1/min" Vector__XXX
 SG_ FrontPTOOutShaftSpeedSetPoint : 16|16@1+ (0.125,0) [0|8031.88] "1/min" Vector__XXX
 SG_ FrontPTOEngagementRqStatus : 32|2@1+ (1,0) [0|3] "" Vector__XXX
 SG_ FrontPTOEconomyMode : 34|2@1+ (1,0) [0|3] "" Vector__XXX
 SG_ FrontPTOMode : 36|2@1+ (1,0) [0|3] "" Vector__XXX
 SG_ FrontPTOEngagement : 38|2@1+ (1,0) [0|3] "" Vector__XXX
 SG_ FrontPTOShaftSpeedLimitStatus : 41|3@1+ (1,0) [0|7] "" Vector__XXX
 SG_ FrontPTOEconomyModeRqStatus : 44|2@1+ (1,0) [0|3] "" Vector__XXX
 SG_ FrontPTOModeRqStatus : 46|2@1+ (1,0) [0|3] "" Vector__XXX

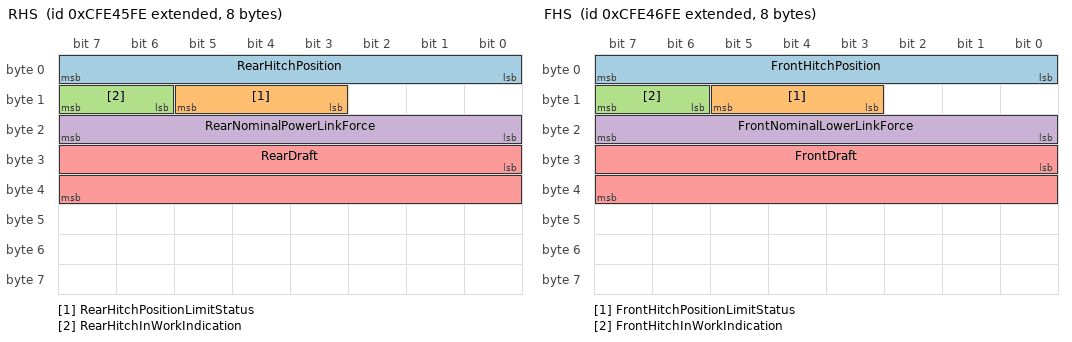
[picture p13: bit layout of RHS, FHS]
BO_ 2365474302 RHS: 8 Vector__XXX
 SG_ RearHitchPosition : 0|8@1+ (0.4,0) [0|100] "%" Vector__XXX
 SG_ RearHitchPositionLimitStatus : 11|3@1+ (1,0) [0|7] "" Vector__XXX
 SG_ RearHitchInWorkIndication : 14|2@1+ (1,0) [0|3] "" Vector__XXX
 SG_ RearNominalPowerLinkForce : 16|8@1+ (0.8,-100) [-100|100] "%" Vector__XXX
 SG_ RearDraft : 24|16@1+ (10,-320000) [-320000|322550] "N" Vector__XXX

BO_ 2365474558 FHS: 8 Vector__XXX
 SG_ FrontHitchPosition : 0|8@1+ (0.4,0) [0|100] "%" Vector__XXX
 SG_ FrontHitchPositionLimitStatus : 11|3@1+ (1,0) [0|7] "" Vector__XXX
 SG_ FrontHitchInWorkIndication : 14|2@1+ (1,0) [0|3] "" Vector__XXX
 SG_ FrontNominalLowerLinkForce : 16|8@1+ (0.8,-100) [-100|100] "%" Vector__XXX
 SG_ FrontDraft : 24|16@1+ (10,-320000) [-320000|322550] "N" Vector__XXX

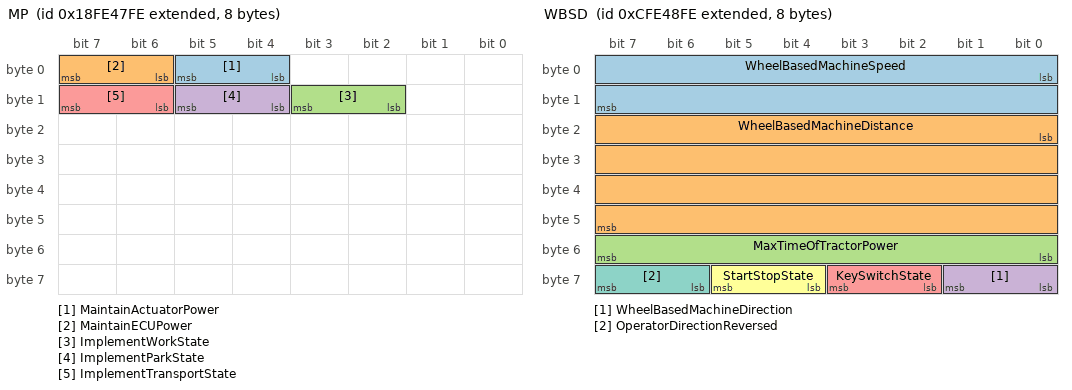
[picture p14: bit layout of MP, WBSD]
BO_ 2566801406 MP: 8 Vector__XXX
 SG_ MaintainActuatorPower : 4|2@1+ (1,0) [0|3] "" Vector__XXX
 SG_ MaintainECUPower : 6|2@1+ (1,0) [0|0] "" Vector__XXX
 SG_ ImplementWorkState : 10|2@1+ (1,0) [0|3] "" Vector__XXX
 SG_ ImplementParkState : 12|2@1+ (1,0) [0|3] "" Vector__XXX
 SG_ ImplementTransportState : 14|2@1+ (1,0) [0|3] "" Vector__XXX

BO_ 2365475070 WBSD: 8 Vector__XXX
 SG_ WheelBasedMachineSpeed : 0|16@1+ (0.001,0) [0|64.255] "m/s" Vector__XXX
 SG_ WheelBasedMachineDistance : 16|32@1+ (0.001,0) [0|4211081.215] "m" Vector__XXX
 SG_ MaxTimeOfTractorPower : 48|8@1+ (1,0) [0|250] "min" Vector__XXX
 SG_ WheelBasedMachineDirection : 56|2@1+ (1,0) [0|3] "" Vector__XXX
 SG_ KeySwitchState : 58|2@1+ (1,0) [0|3] "" Vector__XXX
 SG_ StartStopState : 60|2@1+ (1,0) [0|4] "" Vector__XXX
 SG_ OperatorDirectionReversed : 62|2@1+ (1,0) [0|3] "" Vector__XXX

BO_ 2365475326 GBSD: 8 Vector__XXX
 SG_ GroundBasedMachineSpeed : 0|16@1+ (0.001,0) [0|64.255] "m/s" Vector__XXX
 SG_ GroundBasedMachineDistance : 16|32@1+ (0.001,0) [0|4211080] "m" Vector__XXX
 SG_ GroundBasedMachineDirection : 56|2@1+ (1,0) [0|3] "" Vector__XXX

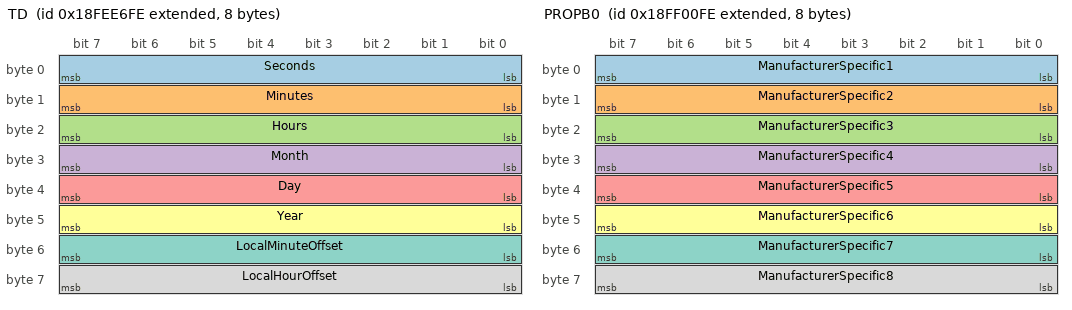
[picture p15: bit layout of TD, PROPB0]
BO_ 2566842110 TD: 8 Vector__XXX
 SG_ Seconds : 0|8@1+ (0.25,0) [0|62.5] "s" Vector__XXX
 SG_ Minutes : 8|8@1+ (1,0) [0|250] "mins" Vector__XXX
 SG_ Hours : 16|8@1+ (1,0) [0|250] "hr" Vector__XXX
 SG_ Month : 24|8@1+ (1,0) [0|250] "months" Vector__XXX
 SG_ Day : 32|8@1+ (0.25,0) [0|62.5] "days" Vector__XXX
 SG_ Year : 40|8@1+ (1,1985) [1985|2235] "years" Vector__XXX
 SG_ LocalMinuteOffset : 48|8@1+ (1,-125) [-125|125] "mins" Vector__XXX
 SG_ LocalHourOffset : 56|8@1+ (1,-125) [-125|125] "hr" Vector__XXX

BO_ 2566848766 PROPB0: 8 Vector__XXX
 SG_ ManufacturerSpecific1 : 0|8@1+ (1,0) [0|255] "" Vector__XXX
 SG_ ManufacturerSpecific2 : 8|8@1+ (1,0) [0|255] "" Vector__XXX
 SG_ ManufacturerSpecific3 : 16|8@1+ (1,0) [0|255] "" Vector__XXX
 SG_ ManufacturerSpecific4 : 24|8@1+ (1,0) [0|255] "" Vector__XXX
 SG_ ManufacturerSpecific5 : 32|8@1+ (1,0) [0|255] "" Vector__XXX
 SG_ ManufacturerSpecific6 : 40|8@1+ (1,0) [0|255] "" Vector__XXX
 SG_ ManufacturerSpecific7 : 48|8@1+ (1,0) [0|255] "" Vector__XXX
 SG_ ManufacturerSpecific8 : 56|8@1+ (1,0) [0|255] "" Vector__XXX

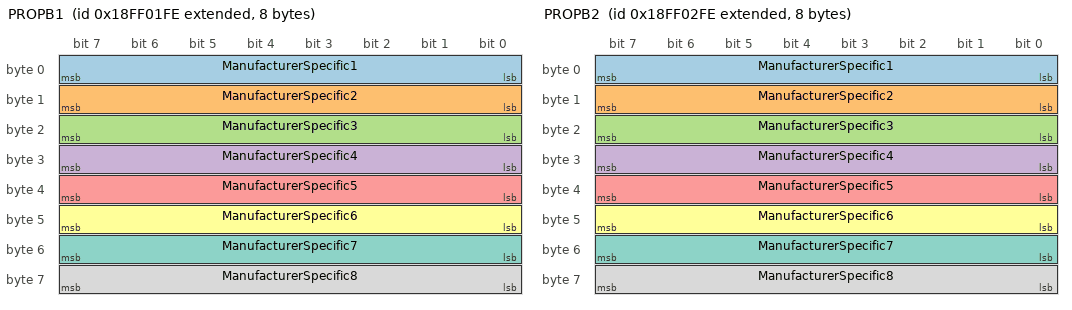
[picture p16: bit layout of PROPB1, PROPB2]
BO_ 2566849022 PROPB1: 8 Vector__XXX
 SG_ ManufacturerSpecific1 : 0|8@1+ (1,0) [0|255] "" Vector__XXX
 SG_ ManufacturerSpecific2 : 8|8@1+ (1,0) [0|255] "" Vector__XXX
 SG_ ManufacturerSpecific3 : 16|8@1+ (1,0) [0|255] "" Vector__XXX
 SG_ ManufacturerSpecific4 : 24|8@1+ (1,0) [0|255] "" Vector__XXX
 SG_ ManufacturerSpecific5 : 32|8@1+ (1,0) [0|255] "" Vector__XXX
 SG_ ManufacturerSpecific6 : 40|8@1+ (1,0) [0|255] "" Vector__XXX
 SG_ ManufacturerSpecific7 : 48|8@1+ (1,0) [0|255] "" Vector__XXX
 SG_ ManufacturerSpecific8 : 56|8@1+ (1,0) [0|255] "" Vector__XXX

BO_ 2566849278 PROPB2: 8 Vector__XXX
 SG_ ManufacturerSpecific1 : 0|8@1+ (1,0) [0|255] "" Vector__XXX
 SG_ ManufacturerSpecific2 : 8|8@1+ (1,0) [0|255] "" Vector__XXX
 SG_ ManufacturerSpecific3 : 16|8@1+ (1,0) [0|255] "" Vector__XXX
 SG_ ManufacturerSpecific4 : 24|8@1+ (1,0) [0|255] "" Vector__XXX
 SG_ ManufacturerSpecific5 : 32|8@1+ (1,0) [0|255] "" Vector__XXX
 SG_ ManufacturerSpecific6 : 40|8@1+ (1,0) [0|255] "" Vector__XXX
 SG_ ManufacturerSpecific7 : 48|8@1+ (1,0) [0|255] "" Vector__XXX
 SG_ ManufacturerSpecific8 : 56|8@1+ (1,0) [0|255] "" Vector__XXX

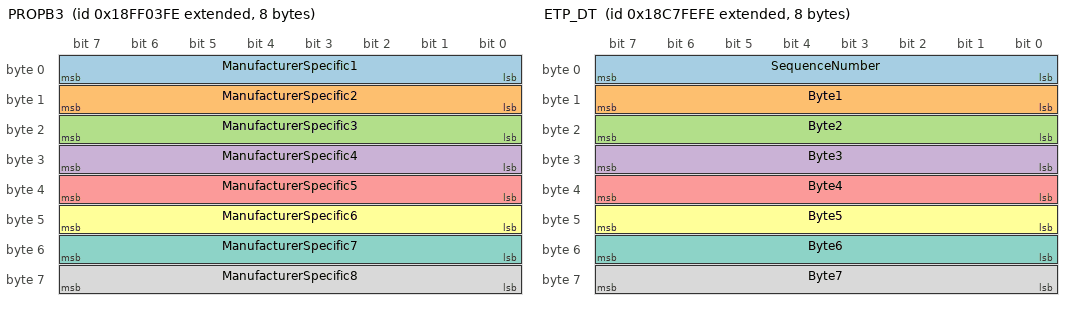
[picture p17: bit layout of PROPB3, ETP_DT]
BO_ 2566849534 PROPB3: 8 Vector__XXX
 SG_ ManufacturerSpecific1 : 0|8@1+ (1,0) [0|255] "" Vector__XXX
 SG_ ManufacturerSpecific2 : 8|8@1+ (1,0) [0|255] "" Vector__XXX
 SG_ ManufacturerSpecific3 : 16|8@1+ (1,0) [0|255] "" Vector__XXX
 SG_ ManufacturerSpecific4 : 24|8@1+ (1,0) [0|255] "" Vector__XXX
 SG_ ManufacturerSpecific5 : 32|8@1+ (1,0) [0|255] "" Vector__XXX
 SG_ ManufacturerSpecific6 : 40|8@1+ (1,0) [0|255] "" Vector__XXX
 SG_ ManufacturerSpecific7 : 48|8@1+ (1,0) [0|255] "" Vector__XXX
 SG_ ManufacturerSpecific8 : 56|8@1+ (1,0) [0|255] "" Vector__XXX

BO_ 2583299838 GNSSPseudoRangeNoiseStatistic: 15 Vector__XXX
 SG_ SequenceID : 0|8@1+ (1,0) [0|255] "" Vector__XXX
 SG_ RMSofPositionUncertainty : 8|16@1+ (0.01,0) [0|655.32] "m" Vector__XXX
 SG_ STDofMajorAxis : 24|16@1+ (0.01,0) [0|655.32] "m" Vector__XXX
 SG_ STDofMinorAxis : 40|16@1+ (0.01,0) [0|655.32] "m" Vector__XXX
 SG_ OrientationOfMinorAxis : 56|16@1+ (0.0001,0) [0|6.2832] "rad" Vector__XXX
 SG_ STDofLatError : 72|16@1+ (0.01,0) [0|655.32] "m" Vector__XXX
 SG_ STDofLonError : 88|16@1+ (0.01,0) [0|655.32] "m" Vector__XXX
 SG_ STDofAltError : 104|16@1+ (0.01,0) [0|655.32] "m" Vector__XXX

BO_ 2583168510 GNSSPositionData: 47 Vector__XXX
 SG_ SequenceID : 0|8@1+ (1,0) [0|255] "" Vector__XXX
 SG_ PositionDate : 8|16@1+ (1,0) [0|65532] "day" Vector__XXX
 SG_ PositionTime : 24|32@1+ (0.0001,0) [0|86401] "hour" Vector__XXX
 SG_ LatitudeLow : 56|32@1+ (1E-016,0) [0|4.294E-007] "deg" Vector__XXX
 SG_ LatitudeHigh : 88|32@1- (4.29497E-007,0) [-90|90] "deg" Vector__XXX
 SG_ LongitudeLow : 120|32@1+ (1E-016,0) [0|4.294E-007] "deg" Vector__XXX
 SG_ LongitudeHigh : 152|32@1- (4.29497E-007,0) [-180|180] "deg" Vector__XXX
 SG_ AltitudeLow : 184|32@1+ (1E-006,0) [0|4294] "m" Vector__XXX
 SG_ AltitudeHigh : 216|32@1- (4294.967295,0) [-1705215488|1705215488] "m" Vector__XXX
 SG_ TypeOfSystem : 248|4@1+ (1,0) [0|4] "" Vector__XXX
 SG_ GNSSMethod : 252|4@1+ (1,0) [0|15] "" Vector__XXX
 SG_ GNSSIntegrity : 256|2@1+ (1,0) [0|3] "" Vector__XXX
 SG_ NumberOfSVs : 264|8@1+ (1,0) [0|252] "" Vector__XXX
 SG_ HDOP : 272|16@1- (0.01,0) [-327.64|327.64] "" Vector__XXX
 SG_ PDOP : 288|16@1- (0.01,0) [-327.64|327.64] "" Vector__XXX
 SG_ GeoidalSeparation : 304|32@1- (0.01,0) [-21470000|21470000] "m" Vector__XXX
 SG_ NumberOfReferenceStations : 336|8@1+ (1,0) [0|252] "" Vector__XXX
 SG_ RefrenceStationType1 : 344|4@1+ (1,0) [0|15] "" Vector__XXX
 SG_ ReferenceStationID1 : 348|12@1+ (1,0) [0|4095] "" Vector__XXX
 SG_ AgeOfDGNSSCorrections1 : 360|16@1+ (0.01,0) [0|655.32] "sec" Vector__XXX

BO_ 2314732030 GNSSPositionRapidUpdate: 8 Vector__XXX
 SG_ Latitude : 0|32@1- (1E-007,0) [-90|90] "deg" Vector__XXX
 SG_ Longitude : 32|32@1- (1E-007,0) [-180|180] "deg" Vector__XXX

BO_ 2563309310 ETP_CM: 8 Vector__XXX
 SG_ ConnectionAbortReason m255 : 8|8@1+ (1,0) [0|255] "" Vector__XXX
 SG_ ControlByte M : 0|8@1+ (1,0) [0|255] "" Vector__XXX
 SG_ NumberOfBytesToTransfer m20 : 8|32@1+ (1,0) [1786|117440505] "" Vector__XXX
 SG_ NumberOfPacketsToSend m21 : 8|8@1+ (1,0) [1|255] "" Vector__XXX
 SG_ NumberOfPacketsOffset m22 : 8|8@1+ (1,0) [1|255] "" Vector__XXX
 SG_ NumberOfBytesTransfered m23 : 8|32@1+ (1,0) [1786|117440505] "" Vector__XXX
 SG_ NextPacketNumberToSend m21 : 16|24@1+ (1,0) [1|16777215] "" Vector__XXX
 SG_ DataPacketOffset m22 : 16|24@1+ (1,0) [0|16777215] "" Vector__XXX
 SG_ PGNumber : 40|24@1+ (1,0) [0|16777200] "" Vector__XXX

BO_ 2563243774 ETP_DT: 8 Vector__XXX
 SG_ SequenceNumber : 0|8@1+ (1,0) [1|255] "" Vector__XXX
 SG_ Byte1 : 8|8@1+ (1,0) [0|255] "" Vector__XXX
 SG_ Byte2 : 16|8@1+ (1,0) [0|255] "" Vector__XXX
 SG_ Byte3 : 24|8@1+ (1,0) [0|255] "" Vector__XXX
 SG_ Byte4 : 32|8@1+ (1,0) [0|255] "" Vector__XXX
 SG_ Byte5 : 40|8@1+ (1,0) [0|255] "" Vector__XXX
 SG_ Byte6 : 48|8@1+ (1,0) [0|255] "" Vector__XXX
 SG_ Byte7 : 56|8@1+ (1,0) [0|255] "" Vector__XXX

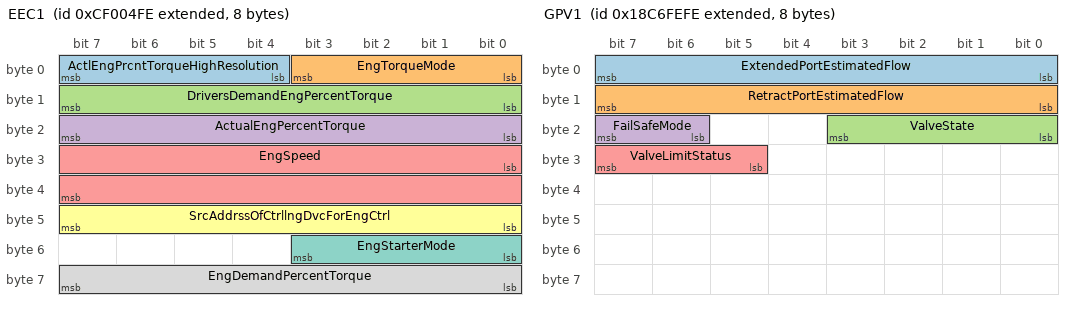
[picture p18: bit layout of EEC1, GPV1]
BO_ 2364540158 EEC1: 8 Vector__XXX
 SG_ ActlEngPrcntTorqueHighResolution : 4|4@1+ (0.125,0) [0|0.875] "%" Vector__XXX
 SG_ EngTorqueMode : 0|4@1+ (1,0) [0|15] "" Vector__XXX
 SG_ DriversDemandEngPercentTorque : 8|8@1+ (1,-125) [-125|125] "%" Vector__XXX
 SG_ ActualEngPercentTorque : 16|8@1+ (1,-125) [-125|125] "%" Vector__XXX
 SG_ EngSpeed : 24|16@1+ (0.125,0) [0|8031.875] "rpm" Vector__XXX
 SG_ SrcAddrssOfCtrllngDvcForEngCtrl : 40|8@1+ (1,0) [0|255] "" Vector__XXX
 SG_ EngStarterMode : 48|4@1+ (1,0) [0|15] "" Vector__XXX
 SG_ EngDemandPercentTorque : 56|8@1+ (1,-125) [-125|125] "%" Vector__XXX

BO_ 2628517630 FSServer: 35 Vector__XXX
 SG_ FSServerCommand M : 0|8@1+ (1,0) [0|255] "" Vector__XXX
 SG_ VS_VolumeStatus m2 : 8|8@1+ (1,0) [0|3] "" Vector__XXX
 SG_ VI_TAN m64 : 8|8@1+ (1,0) [0|255] "" Vector__XXX
 SG_ DF_TAN m49 : 8|8@1+ (1,0) [0|255] "" Vector__XXX
 SG_ GSP_VersionNumber m1 : 8|8@1+ (1,0) [0|255] "" Vector__XXX
 SG_ CCD_TAN m17 : 8|8@1+ (1,0) [0|255] "" Vector__XXX
 SG_ GCD_TAN m16 : 8|8@1+ (1,0) [0|255] "" Vector__XXX
 SG_ FDT_TAN m52 : 8|8@1+ (1,0) [0|255] "" Vector__XXX
 SG_ SA_TAN m51 : 8|8@1+ (1,0) [0|255] "" Vector__XXX
 SG_ GA_TAN m50 : 8|8@1+ (1,0) [0|255] "" Vector__XXX
 SG_ MF_TAN m48 : 8|8@1+ (1,0) [0|255] "" Vector__XXX
 SG_ CF_TAN m36 : 8|8@1+ (1,0) [0|255] "" Vector__XXX
 SG_ WF_TAN m35 : 8|8@1+ (1,0) [0|255] "" Vector__XXX
 SG_ RF_TAN m34 : 8|8@1+ (1,0) [0|255] "" Vector__XXX
 SG_ SF_TAN m33 : 8|8@1+ (1,0) [0|255] "" Vector__XXX
 SG_ OF_TAN m32 : 8|8@1+ (1,0) [0|255] "" Vector__XXX
 SG_ FSBusyReading m0 : 8|1@1+ (1,0) [0|1] "" Vector__XXX
 SG_ FSBusyWriting m0 : 9|1@1+ (1,0) [0|1] "" Vector__XXX
 SG_ VS_MaxTimeBeforeVolRemoval m2 : 16|8@1+ (1,0) [0|250] "min/bit" Vector__XXX
 SG_ VI_ErrorCode m64 : 16|8@1+ (1,0) [0|255] "" Vector__XXX
 SG_ DF_ErrorCode m49 : 16|8@1+ (1,0) [0|255] "" Vector__XXX
 SG_ GSP_MaxNrSimultaneousFilesOpen m1 : 16|8@1+ (1,0) [0|255] "" Vector__XXX
 SG_ CCD_ErrorCode m17 : 16|8@1+ (1,0) [0|255] "" Vector__XXX
 SG_ GCD_ErrorCode m16 : 16|8@1+ (1,0) [0|255] "" Vector__XXX
 SG_ SA_ErrorCode m51 : 16|8@1+ (1,0) [0|255] "" Vector__XXX
 SG_ GA_ErrorCode m50 : 16|8@1+ (1,0) [0|255] "" Vector__XXX
 SG_ MF_ErrorCode m48 : 16|8@1+ (1,0) [0|255] "" Vector__XXX
 SG_ CF_ErrorCode m36 : 16|8@1+ (1,0) [0|255] "" Vector__XXX
 SG_ WF_ErrorCode m35 : 16|8@1+ (1,0) [0|255] "" Vector__XXX
 SG_ OF_ErrorCode m32 : 16|8@1+ (1,0) [0|255] "" Vector__XXX
 SG_ FSNumberOfOpenFiles m0 : 16|8@1- (1,0) [0|255] "" Vector__XXX
 SG_ SF_ErrorCode m33 : 16|8@1+ (1,0) [0|255] "" Vector__XXX
 SG_ RF_ErrorCode m34 : 16|8@1+ (1,0) [0|255] "" Vector__XXX
 SG_ FDT_ErrorCode m52 : 16|8@1+ (1,0) [0|255] "" Vector__XXX
 SG_ VS_ErrorCode m2 : 24|8@1+ (1,0) [0|255] "" Vector__XXX
 SG_ WF_Count m35 : 24|16@1+ (1,0) [0|65535] "" Vector__XXX
 SG_ GSP_SupportMultipleVolumes m1 : 24|1@1+ (1,0) [0|255] "" Vector__XXX
 SG_ RF_Count m34 : 24|16@1+ (1,0) [0|65535] "Bytes" Vector__XXX
 SG_ GCD_TotalSpace m16 : 24|32@1+ (512,0) [0|4294966744] "Bytes" Vector__XXX
 SG_ OF_Handle m32 : 24|8@1+ (1,0) [0|255] "" Vector__XXX
 SG_ GA_ATTR_ReadOnly m50 : 24|1@1+ (1,0) [0|1] "" Vector__XXX
 SG_ FDT_DateDay m52 : 24|5@1+ (1,0) [0|31] "Day" Vector__XXX
 SG_ VI_ATTR_ReadOnly m64 : 24|1@1+ (1,0) [0|1] "" Vector__XXX
 SG_ GA_ATTR_Hidden m50 : 25|1@1+ (1,0) [0|1] "" Vector__XXX
 SG_ VI_ATTR_Hidden m64 : 25|1@1+ (1,0) [0|1] "" Vector__XXX
 SG_ GA_ATTR_VolSupportsHiddenAttr m50 : 26|1@1+ (1,0) [0|1] "" Vector__XXX
 SG_ VI_ATTR_VolSupportsHiddenAttr m64 : 26|1@1+ (1,0) [0|1] "" Vector__XXX
 SG_ GA_ATTR_IsVolume m50 : 27|1@1+ (1,0) [0|1] "" Vector__XXX
 SG_ VI_ATTR_IsVolume m64 : 27|1@1+ (1,0) [0|1] "" Vector__XXX
 SG_ VI_ATTR_Directory m64 : 28|1@1+ (1,0) [0|1] "" Vector__XXX
 SG_ GA_ATTR_Directory m50 : 28|1@1+ (1,0) [0|1] "" Vector__XXX
 SG_ GA_ATTR_SupportsLongFilenames m50 : 29|1@1+ (1,0) [0|1] "" Vector__XXX
 SG_ FDT_DateMonth m52 : 29|4@1+ (1,0) [0|12] "Month" Vector__XXX
 SG_ VI_ATTR_SupportsLongFilenames m64 : 29|1@1+ (1,0) [0|1] "" Vector__XXX
 SG_ GA_ATTR_VolumeRemovable m50 : 30|1@1+ (1,0) [0|1] "" Vector__XXX
 SG_ VI_ATTR_VolumeRemovable m64 : 30|1@1+ (1,0) [0|1] "" Vector__XXX
 SG_ GA_ATTR_VolumeIsCaseSensitive m50 : 31|1@1+ (1,0) [0|1] "" Vector__XXX
 SG_ VI_VolumeIsCaseSensitive m64 : 31|1@1+ (1,0) [0|1] "" Vector__XXX
 SG_ VS_VolumeName m2 : 32|16@1+ (1,0) [0|65535] "" Vector__XXX
 SG_ GA_Size m50 : 32|32@1+ (1,0) [0|4294967295] "" Vector__XXX
 SG_ OF_ATTR_ReadOnly m32 : 32|1@1+ (1,0) [0|1] "" Vector__XXX
 SG_ SF_Position m33 : 32|32@1+ (1,0) [0|4294967295] "" Vector__XXX
 SG_ OF_ATTR_Hidden m32 : 33|1@1+ (1,0) [0|1] "" Vector__XXX
 SG_ FDT_DateYear m52 : 33|7@1+ (1,1980) [1980|2107] "Year" Vector__XXX
 SG_ OF_ATTR_IsVolume m32 : 35|1@1+ (1,0) [0|1] "" Vector__XXX
 SG_ OF_ATTR_Directory m32 : 36|1@1+ (1,0) [0|1] "" Vector__XXX
 SG_ OF_ATTR_SupportsLongFilenames m32 : 37|1@1+ (1,0) [0|1] "" Vector__XXX
 SG_ OF_ATTR_VolumeRemovable m32 : 38|1@1+ (1,0) [0|1] "" Vector__XXX
 SG_ OF_ATTR_VolumeIsCaseSensitive m32 : 39|1@1+ (1,0) [0|1] "" Vector__XXX
 SG_ FDT_TimeSeconds m52 : 40|5@1+ (2,0) [0|58] "Seconds" Vector__XXX
 SG_ FDT_TimeMinutes m52 : 45|6@1+ (1,0) [0|59] "Minutes" Vector__XXX
 SG_ FDT_TimeHour m52 : 51|5@1+ (1,0) [0|23] "Hour" Vector__XXX
 SG_ GCD_FreeSpace m16 : 56|32@1+ (512,0) [0|4294966744] "Bytes" Vector__XXX
 SG_ GCD_PathName m16 : 88|16@1+ (1,0) [0|65535] "" Vector__XXX

BO_ 2628452094 FSClient: 9 Vector__XXX
 SG_ FSClientCommand M : 0|8@1+ (1,0) [0|255] "" Vector__XXX
 SG_ CM_VersionNumber m0 : 8|8@1+ (1,0) [0|255] "" Vector__XXX
 SG_ VS_ReportVolumeUsedByClient m2 : 8|1@1+ (1,0) [0|1] "" Vector__XXX
 SG_ VI_TAN m64 : 8|8@1+ (1,0) [0|255] "" Vector__XXX
 SG_ DF_TAN m49 : 8|8@1+ (1,0) [0|255] "" Vector__XXX
 SG_ MF_TAN m48 : 8|8@1+ (1,0) [0|255] "" Vector__XXX
 SG_ OF_TAN m32 : 8|8@1+ (1,0) [0|255] "" Vector__XXX
 SG_ SF_TAN m33 : 8|8@1+ (1,0) [0|255] "" Vector__XXX
 SG_ WF_TAN m35 : 8|8@1+ (1,0) [0|255] "" Vector__XXX
 SG_ CF_TAN m36 : 8|8@1+ (1,0) [0|255] "" Vector__XXX
 SG_ RF_TAN m34 : 8|8@1+ (1,0) [0|255] "" Vector__XXX
 SG_ GA_TAN m50 : 8|8@1+ (1,0) [0|255] "" Vector__XXX
 SG_ SA_TAN m51 : 8|8@1+ (1,0) [0|255] "" Vector__XXX
 SG_ FDT_TAN m52 : 8|8@1+ (1,0) [0|255] "" Vector__XXX
 SG_ GCD_TAN m16 : 8|8@1+ (1,0) [0|255] "" Vector__XXX
 SG_ CCD_TAN m17 : 8|8@1+ (1,0) [0|255] "" Vector__XXX
 SG_ VS_RequestVolumeToPrepareForRemo m2 : 9|1@1- (1,0) [0|1] "" Vector__XXX
 SG_ VS_VolumeName m2 : 16|16@1+ (1,0) [0|0] "" Vector__XXX
 SG_ FDT_PathName m52 : 16|16@1+ (1,0) [0|65535] "" Vector__XXX
 SG_ GA_PathName m50 : 16|16@1+ (1,0) [0|65535] "" Vector__XXX
 SG_ DF_DeleteMode m49 : 16|1@1+ (1,0) [0|1] "" Vector__XXX
 SG_ MF_MoveModeCopy m48 : 16|1@1+ (1,0) [0|1] "" Vector__XXX
 SG_ CCD_PathName m17 : 16|16@1+ (1,0) [0|65535] "" Vector__XXX
 SG_ OF_FlagReadWrite m32 : 16|2@1+ (1,0) [0|3] "" Vector__XXX
 SG_ SF_Handle m33 : 16|8@1+ (1,0) [0|255] "" Vector__XXX
 SG_ RF_Handle m34 : 16|8@1+ (1,0) [0|255] "" Vector__XXX
 SG_ WF_Handle m35 : 16|8@1+ (1,0) [0|255] "" Vector__XXX
 SG_ CF_Handle m36 : 16|8@1+ (1,0) [0|255] "" Vector__XXX
 SG_ SET_ATTR_ReadOnly m51 : 16|2@1+ (1,0) [0|3] "" Vector__XXX
 SG_ VI_Flag_UsingSpaceSpecified m64 : 49|1@1+ (1,0) [0|1] "" Vector__XXX
 SG_ DF_DeleteModeForce m49 : 17|1@1+ (1,0) [0|1] "" Vector__XXX
 SG_ MF_MoveModeForce m48 : 17|1@1+ (1,0) [0|1] "" Vector__XXX
 SG_ DF_DeleteModeRecursive m49 : 18|1@1+ (1,0) [0|1] "" Vector__XXX
 SG_ MF_MoveModeRecursive m48 : 18|1@1+ (1,0) [0|1] "" Vector__XXX
 SG_ OF_FlagCreateNew m32 : 18|1@1+ (1,0) [0|1] "" Vector__XXX
 SG_ SET_ATTR_Hidden m51 : 18|2@1+ (1,0) [0|3] "" Vector__XXX
 SG_ OF_FlagAppend m32 : 19|1@1+ (1,0) [0|1] "" Vector__XXX
 SG_ OF_FlagExclusiveAccess m32 : 20|1@1+ (1,0) [0|1] "" Vector__XXX
 SG_ VI_Space m64 : 16|32@1+ (1,0) [0|4294967295] "" Vector__XXX
 SG_ SA_PathName m51 : 24|16@1+ (1,0) [0|65535] "" Vector__XXX
 SG_ DF_PathName m49 : 24|16@1+ (1,0) [0|65535] "" Vector__XXX
 SG_ WF_Count m35 : 24|16@1+ (1,0) [0|65535] "" Vector__XXX
 SG_ MF_SourcePathNameLength m48 : 24|16@1+ (1,0) [0|65535] "" Vector__XXX
 SG_ OF_PathName m32 : 24|16@1+ (1,0) [0|65535] "" Vector__XXX
 SG_ SF_PositionMode m33 : 24|8@1+ (1,0) [0|255] "" Vector__XXX
 SG_ RF_Count m34 : 24|16@1+ (1,0) [0|65535] "" Vector__XXX
 SG_ SF_Offset m33 : 32|32@1+ (1,0) [0|4294967295] "" Vector__XXX
 SG_ RF_ReportHiddenFiles m34 : 40|8@1+ (1,0) [0|255] "" Vector__XXX
 SG_ MF_DestinationPathNameLength m48 : 40|16@1+ (1,0) [0|65535] "" Vector__XXX
 SG_ VI_Flag_OverwriteExisting m64 : 48|1@1+ (1,0) [0|1] "" Vector__XXX
 SG_ VI_VolumeName m64 : 56|16@1+ (1,0) [0|65535] "" Vector__XXX

BO_ 2563178238 GPV1: 8 Vector__XXX
 SG_ ExtendedPortEstimatedFlow : 0|8@1+ (1,-125) [-125|125] "%" Vector__XXX
 SG_ RetractPortEstimatedFlow : 8|8@1+ (1,-125) [-125|125] "%" Vector__XXX
 SG_ ValveState : 16|4@1+ (1,0) [0|15] "" Vector__XXX
 SG_ FailSafeMode : 22|2@1+ (1,0) [0|3] "" Vector__XXX
 SG_ ValveLimitStatus : 29|3@1+ (1,0) [0|7] "" Vector__XXX

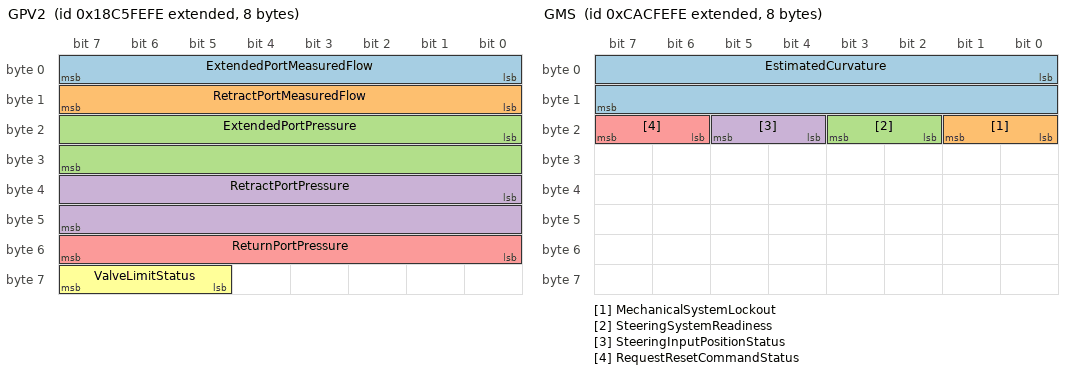
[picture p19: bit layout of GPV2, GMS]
BO_ 2563112702 GPV2: 8 Vector__XXX
 SG_ ExtendedPortMeasuredFlow : 0|8@1+ (1,-125) [-125|125] "%" Vector__XXX
 SG_ RetractPortMeasuredFlow : 8|8@1+ (1,-125) [-125|125] "%" Vector__XXX
 SG_ ExtendedPortPressure : 16|16@1+ (5,0) [0|321275] "kPa" Vector__XXX
 SG_ RetractPortPressure : 32|16@1+ (5,0) [0|321275] "kPa" Vector__XXX
 SG_ ReturnPortPressure : 48|8@1+ (16,0) [0|4000] "kPa" Vector__XXX
 SG_ ValveLimitStatus : 61|3@1+ (1,0) [0|7] "" Vector__XXX

BO_ 2563047166 GPV3: 8 Vector__XXX
 SG_ PortFlowCmd : 0|8@1+ (0.4,0) [0|100] "%" Vector__XXX
 SG_ StateCmd : 16|4@1+ (1,0) [0|15] "" Vector__XXX
 SG_ FailSaveModeCmd : 22|2@1+ (1,0) [0|3] "" Vector__XXX

BO_ 2360213246 GSC: 8 Vector__XXX
 SG_ CurvatureCommand : 0|16@1+ (0.25,-8032) [-8032|8031.75] "1/km" Vector__XXX
 SG_ CurvatureCommandStatus : 16|2@1+ (1,0) [0|3] "" Vector__XXX

BO_ 2360147710 GMS: 8 Vector__XXX
 SG_ EstimatedCurvature : 0|16@1+ (0.25,-8032) [-8032|8031.75] "1/km" Vector__XXX
 SG_ MechanicalSystemLockout : 16|2@1+ (1,0) [0|3] "" Vector__XXX
 SG_ SteeringSystemReadiness : 18|2@1+ (1,0) [0|3] "" Vector__XXX
 SG_ SteeringInputPositionStatus : 20|2@1+ (1,0) [0|3] "" Vector__XXX
 SG_ RequestResetCommandStatus : 22|2@1+ (1,0) [0|3] "" Vector__XXX

EV_ evCmdDeactivate: 0 [0|1] "" 0 1 DUMMY_NODE_VECTOR0 Vector__XXX;

EV_ evCmdActivate: 0 [0|1] "" 0 2 DUMMY_NODE_VECTOR0 Vector__XXX;

EV_ evOPCGetExtendedVersion: 0 [0|1] "" 0 3 DUMMY_NODE_VECTOR0 Vector__XXX;

EV_ evOPCVersion: 0 [0|0] "" 0 4 DUMMY_NODE_VECTOR8000 Vector__XXX;

EV_ evOPCVTVersion: 0 [2|5] "" 5 5 DUMMY_NODE_VECTOR0 Vector__XXX;

EV_ evOPCTransmit: 0 [0|1] "" 0 6 DUMMY_NODE_VECTOR0 Vector__XXX;

EV_ evOPCStore: 0 [0|1] "" 0 7 DUMMY_NODE_VECTOR0 Vector__XXX;

EV_ evOPCOnOffSwitch: 0 [0|1] "" 0 8 DUMMY_NODE_VECTOR0 Vector__XXX;

EV_ evOPCLoad: 0 [0|1] "" 0 9 DUMMY_NODE_VECTOR0 Vector__XXX;

EV_ evOPCGetVersion: 0 [0|1] "" 0 10 DUMMY_NODE_VECTOR0 Vector__XXX;

EV_ evOPCFilename: 0 [0|0] "" 0 11 DUMMY_NODE_VECTOR8000 Vector__XXX;

EV_ evOPCDelete: 0 [0|1] "" 0 12 DUMMY_NODE_VECTOR0 Vector__XXX;

EV_ evOPCCurrentTabPage: 0 [0|4] "" 0 13 DUMMY_NODE_VECTOR0 Vector__XXX;

EV_ evOPCAddress: 0 [0|255] "" 10 14 DUMMY_NODE_VECTOR0 Vector__XXX;

EV_ evCmdStoresAsIopx: 0 [0|1] "" 0 15 DUMMY_NODE_VECTOR0 Vector__XXX;

EV_ evCmdStoresAsIop: 0 [0|1] "" 0 16 DUMMY_NODE_VECTOR0 Vector__XXX;

EV_ evCmdShowHideObjectId: 0 [0|65535] "" 0 17 DUMMY_NODE_VECTOR0 Vector__XXX;

EV_ evCmdShow: 0 [0|1] "" 0 18 DUMMY_NODE_VECTOR0 Vector__XXX;

EV_ evCmdSetObjectLabelStringVarId: 0 [0|65535] "" 0 19 DUMMY_NODE_VECTOR0 Vector__XXX;

EV_ evCmdSetObjectLabelLabelObjId: 0 [0|65535] "" 65535 20 DUMMY_NODE_VECTOR0 Vector__XXX;

EV_ evCmdSetObjectLabelId: 0 [0|65535] "" 0 21 DUMMY_NODE_VECTOR0 Vector__XXX;

EV_ evCmdSetObjectLabelFontType: 0 [0|255] "" 0 22 DUMMY_NODE_VECTOR0 Vector__XXX;

EV_ evCmdSetObjectLabel: 0 [0|1] "" 0 23 DUMMY_NODE_VECTOR0 Vector__XXX;

EV_ evCmdSetAudioVolumeValue: 0 [0|255] "" 50 24 DUMMY_NODE_VECTOR0 Vector__XXX;

EV_ evCmdSetAudioVolume: 0 [0|1] "" 0 25 DUMMY_NODE_VECTOR0 Vector__XXX;

EV_ evCmdSelectSelectionType: 0 [0|2] "" 1 26 DUMMY_NODE_VECTOR0 Vector__XXX;

EV_ evCmdSelectObjectId: 0 [0|65535] "" 0 27 DUMMY_NODE_VECTOR0 Vector__XXX;

EV_ evCmdSelectColourMapId: 0 [0|65535] "" 0 28 DUMMY_NODE_VECTOR0 Vector__XXX;

EV_ evCmdSelectColourMap: 0 [0|1] "" 0 29 DUMMY_NODE_VECTOR0 Vector__XXX;

EV_ evCmdSelect: 0 [0|1] "" 0 30 DUMMY_NODE_VECTOR0 Vector__XXX;

EV_ evCmdOPCUsePropFont: 0 [0|1] "" 0 31 DUMMY_NODE_VECTOR0 Vector__XXX;

EV_ evCmdLockUnlockMaskType: 0 [0|1] "" 1 32 DUMMY_NODE_VECTOR0 Vector__XXX;

EV_ evCmdLockUnlockMaskTimeout: 0 [0|65535] "" 1000 33 DUMMY_NODE_VECTOR0 Vector__XXX;

EV_ evCmdLockUnlockMaskId: 0 [0|65535] "" 0 34 DUMMY_NODE_VECTOR0 Vector__XXX;

EV_ evCmdLockUnlockMask: 0 [0|1] "" 0 35 DUMMY_NODE_VECTOR0 Vector__XXX;

EV_ evCmdIdentifyVT: 0 [0|1] "" 0 36 DUMMY_NODE_VECTOR0 Vector__XXX;

EV_ evCmdHideShow: 0 [0|1] "" 0 37 DUMMY_NODE_VECTOR0 Vector__XXX;

EV_ evCmdGraphicsContext: 0 [0|1] "" 0 38 DUMMY_NODE_VECTOR0 Vector__XXX;

EV_ evCmdGetWindowMaskData: 0 [0|1] "" 0 39 DUMMY_NODE_VECTOR0 Vector__XXX;

EV_ evCmdGetTextFontData: 0 [0|1] "" 0 40 DUMMY_NODE_VECTOR0 Vector__XXX;

EV_ evCmdGetSupportedWideCharsLastCh: 0 [0|65535] "" 16383 41 DUMMY_NODE_VECTOR0 Vector__XXX;

EV_ evCmdGetSupportedWideCharsFirstC: 0 [0|65535] "" 0 42 DUMMY_NODE_VECTOR0 Vector__XXX;

EV_ evCmdGetSupportedWideCharsCodepl: 0 [0|21] "" 0 43 DUMMY_NODE_VECTOR0 Vector__XXX;

EV_ evCmdGetSupportedWideChars: 0 [0|1] "" 0 44 DUMMY_NODE_VECTOR0 Vector__XXX;

EV_ evCmdGetSupportedObjects: 0 [0|1] "" 0 45 DUMMY_NODE_VECTOR0 Vector__XXX;

EV_ evCmdGetMemoryNumOfBytes: 0 [0|268435455] "" 0 46 DUMMY_NODE_VECTOR0 Vector__XXX;

EV_ evCmdGetMemory: 0 [0|1] "" 0 47 DUMMY_NODE_VECTOR0 Vector__XXX;

EV_ evCmdGetAttributeId: 0 [0|65535] "" 0 48 DUMMY_NODE_VECTOR0 Vector__XXX;

EV_ evCmdGetAttributeAttrId: 0 [0|65535] "" 0 49 DUMMY_NODE_VECTOR0 Vector__XXX;

EV_ evCmdGetAttribute: 0 [0|1] "" 0 50 DUMMY_NODE_VECTOR0 Vector__XXX;

EV_ evCmdGcZoomViewportValue: 1 [-32|32] "" 1 51 DUMMY_NODE_VECTOR0 Vector__XXX;

EV_ evCmdGcZoomViewport: 0 [0|1] "" 0 52 DUMMY_NODE_VECTOR0 Vector__XXX;

EV_ evCmdGcTestObject: 0 [0|1] "" 0 53 DUMMY_NODE_VECTOR0 Vector__XXX;

EV_ evCmdGcSetLineAttributesIDValue: 0 [0|65535] "" 0 54 DUMMY_NODE_VECTOR0 Vector__XXX;

EV_ evCmdGcSetLineAttributesID: 0 [0|1] "" 0 55 DUMMY_NODE_VECTOR0 Vector__XXX;

EV_ evCmdGcSetGraphicsCursorY: 0 [0|65535] "" 0 56 DUMMY_NODE_VECTOR0 Vector__XXX;

EV_ evCmdGcSetGraphicsCursorX: 0 [0|65535] "" 0 57 DUMMY_NODE_VECTOR0 Vector__XXX;

EV_ evCmdGcSetGraphicsCursor: 0 [0|1] "" 0 58 DUMMY_NODE_VECTOR0 Vector__XXX;

EV_ evCmdGcSetForegroundColourValue: 0 [0|255] "" 0 59 DUMMY_NODE_VECTOR0 Vector__XXX;

EV_ evCmdGcSetForegroundColour: 0 [0|1] "" 0 60 DUMMY_NODE_VECTOR0 Vector__XXX;

EV_ evCmdGcSetFontAttributesIDValue: 0 [0|65535] "" 0 61 DUMMY_NODE_VECTOR0 Vector__XXX;

EV_ evCmdGcSetFontAttributesID: 0 [0|1] "" 0 62 DUMMY_NODE_VECTOR0 Vector__XXX;

EV_ evCmdGcSetFillAttributesIDValue: 0 [0|65535] "" 0 63 DUMMY_NODE_VECTOR0 Vector__XXX;

EV_ evCmdGcSetFillAttributesID: 0 [0|1] "" 0 64 DUMMY_NODE_VECTOR0 Vector__XXX;

EV_ evCmdGcSetBackgroundColourValue: 0 [0|255] "" 1 65 DUMMY_NODE_VECTOR0 Vector__XXX;

EV_ evCmdGcSetBackgroundColour: 0 [0|1] "" 0 66 DUMMY_NODE_VECTOR0 Vector__XXX;

EV_ evCmdGcPanViewportY: 0 [-32767|32767] "" 0 67 DUMMY_NODE_VECTOR0 Vector__XXX;

EV_ evCmdGcPanViewportX: 0 [-32767|32767] "" 0 68 DUMMY_NODE_VECTOR0 Vector__XXX;

EV_ evCmdGcPanViewport: 0 [0|1] "" 0 69 DUMMY_NODE_VECTOR0 Vector__XXX;

EV_ evCmdGcPanAndZoomViewport: 0 [0|1] "" 0 70 DUMMY_NODE_VECTOR0 Vector__XXX;

EV_ evCmdGcObjectID: 0 [0|65535] "" 0 71 DUMMY_NODE_VECTOR0 Vector__XXX;

EV_ evCmdGcMoveGraphicsCursorY: 0 [0|65535] "" 0 72 DUMMY_NODE_VECTOR0 Vector__XXX;

EV_ evCmdGcMoveGraphicsCursorX: 0 [0|65535] "" 0 73 DUMMY_NODE_VECTOR0 Vector__XXX;

EV_ evCmdGcMoveGraphicsCursor: 0 [0|1] "" 0 74 DUMMY_NODE_VECTOR0 Vector__XXX;

EV_ evCmdGcEraseRectangleWidth: 0 [0|65535] "" 100 75 DUMMY_NODE_VECTOR0 Vector__XXX;

EV_ evCmdGcEraseRectangleHeight: 0 [0|65535] "" 100 76 DUMMY_NODE_VECTOR0 Vector__XXX;

EV_ evCmdGcEraseRectangle: 0 [0|1] "" 0 77 DUMMY_NODE_VECTOR0 Vector__XXX;

EV_ evCmdGcDrawWideCharText: 0 [0|1] "" 0 78 DUMMY_NODE_VECTOR0 Vector__XXX;

EV_ evCmdGcDrawVTObjectValue: 0 [0|65535] "" 0 79 DUMMY_NODE_VECTOR0 Vector__XXX;

EV_ evCmdGcDrawVTObject: 0 [0|1] "" 0 80 DUMMY_NODE_VECTOR0 Vector__XXX;

EV_ evCmdGcDrawTextValue: 0 [0|1] "" 0 81 DUMMY_NODE_VECTOR8000 Vector__XXX;

EV_ evCmdGcDrawTextTransparent: 0 [0|1] "" 0 82 DUMMY_NODE_VECTOR0 Vector__XXX;

EV_ evCmdGcDrawText: 0 [0|1] "" 0 83 DUMMY_NODE_VECTOR0 Vector__XXX;

EV_ evCmdGcDrawRecangleWidth: 0 [0|65535] "" 20 84 DUMMY_NODE_VECTOR0 Vector__XXX;

EV_ evCmdGcDrawRecangleHeight: 0 [0|65535] "" 20 85 DUMMY_NODE_VECTOR0 Vector__XXX;

EV_ evCmdGcDrawRecangle: 0 [0|1] "" 0 86 DUMMY_NODE_VECTOR0 Vector__XXX;

EV_ evCmdGcDrawPolygonY4: 0 [0|65535] "" 15 87 DUMMY_NODE_VECTOR0 Vector__XXX;

EV_ evCmdGcDrawPolygonY3: 0 [0|65535] "" 20 88 DUMMY_NODE_VECTOR0 Vector__XXX;

EV_ evCmdGcDrawPolygonY2: 0 [0|65535] "" 5 89 DUMMY_NODE_VECTOR0 Vector__XXX;

EV_ evCmdGcDrawPolygonY1: 0 [0|65535] "" 2 90 DUMMY_NODE_VECTOR0 Vector__XXX;

EV_ evCmdGcDrawPolygonX4: 0 [0|65535] "" 1 91 DUMMY_NODE_VECTOR0 Vector__XXX;

EV_ evCmdGcDrawPolygonX3: 0 [0|65535] "" 20 92 DUMMY_NODE_VECTOR0 Vector__XXX;

EV_ evCmdGcDrawPolygonX2: 0 [0|65535] "" 15 93 DUMMY_NODE_VECTOR0 Vector__XXX;

EV_ evCmdGcDrawPolygonX1: 0 [0|65535] "" 2 94 DUMMY_NODE_VECTOR0 Vector__XXX;

EV_ evCmdGcDrawPolygon: 0 [0|1] "" 0 95 DUMMY_NODE_VECTOR0 Vector__XXX;

EV_ evCmdGcDrawPointY: 0 [0|65535] "" 0 96 DUMMY_NODE_VECTOR0 Vector__XXX;

EV_ evCmdGcDrawPointX: 0 [0|65535] "" 0 97 DUMMY_NODE_VECTOR0 Vector__XXX;

EV_ evCmdGcDrawPoint: 0 [0|1] "" 0 98 DUMMY_NODE_VECTOR0 Vector__XXX;

EV_ evCmdGcDrawLineY: 0 [0|65535] "" 20 99 DUMMY_NODE_VECTOR0 Vector__XXX;

EV_ evCmdGcDrawLineX: 0 [0|65535] "" 20 100 DUMMY_NODE_VECTOR0 Vector__XXX;

EV_ evCmdGcDrawLine: 0 [0|1] "" 0 101 DUMMY_NODE_VECTOR0 Vector__XXX;

EV_ evCmdGcDrawClosedEllipseWidth: 0 [0|65535] "" 20 102 DUMMY_NODE_VECTOR0 Vector__XXX;

EV_ evCmdGcDrawClosedEllipseHeight: 0 [0|65535] "" 20 103 DUMMY_NODE_VECTOR0 Vector__XXX;

EV_ evCmdGcDrawClosedEllipse: 0 [0|1] "" 0 104 DUMMY_NODE_VECTOR0 Vector__XXX;

EV_ evCmdGcCopyViewportToPictureValu: 0 [0|65535] "" 0 105 DUMMY_NODE_VECTOR0 Vector__XXX;

EV_ evCmdGcCopyViewportToPicture: 0 [0|1] "" 0 106 DUMMY_NODE_VECTOR0 Vector__XXX;

EV_ evCmdGcCopyCanvasToPictureValue: 0 [0|65535] "" 0 107 DUMMY_NODE_VECTOR0 Vector__XXX;

EV_ evCmdGcCopyCanvasToPicture: 0 [0|1] "" 0 108 DUMMY_NODE_VECTOR0 Vector__XXX;

EV_ evCmdGcChangeViewportSizeWidth: 0 [0|65535] "" 100 109 DUMMY_NODE_VECTOR0 Vector__XXX;

EV_ evCmdGcChangeViewportSizeHeight: 0 [0|65535] "" 100 110 DUMMY_NODE_VECTOR0 Vector__XXX;

EV_ evCmdGcChangeViewportSize: 0 [0|1] "" 0 111 DUMMY_NODE_VECTOR0 Vector__XXX;

EV_ evCmdExecuteMacroObjId: 0 [0|65535] "" 0 112 DUMMY_NODE_VECTOR0 Vector__XXX;

EV_ evCmdExecuteMacro: 0 [0|1] "" 0 113 DUMMY_NODE_VECTOR0 Vector__XXX;

EV_ evCmdEnableErrorHandling: 0 [0|1] "" 1 114 DUMMY_NODE_VECTOR0 Vector__XXX;

EV_ evCmdEnableDisableObjectId: 0 [0|65535] "" 0 115 DUMMY_NODE_VECTOR0 Vector__XXX;

EV_ evCmdEnableDisable: 0 [0|1] "" 0 116 DUMMY_NODE_VECTOR0 Vector__XXX;

EV_ evCmdEnable: 0 [0|1] "" 0 117 DUMMY_NODE_VECTOR0 Vector__XXX;

EV_ evCmdESC: 0 [0|1] "" 0 118 DUMMY_NODE_VECTOR0 Vector__XXX;

EV_ evCmdDeleteObjectPool: 0 [0|1] "" 0 119 DUMMY_NODE_VECTOR0 Vector__XXX;

EV_ evCmdControlAudioDeviceOnTimeDur: 0 [0|65535] "" 300 120 DUMMY_NODE_VECTOR0 Vector__XXX;

EV_ evCmdControlAudioDeviceOffTimeDu: 0 [0|65535] "" 150 121 DUMMY_NODE_VECTOR0 Vector__XXX;

EV_ evCmdControlAudioDeviceNumOfActi: 0 [0|597] "" 3 122 DUMMY_NODE_VECTOR0 Vector__XXX;

EV_ evCmdControlAudioDeviceFrequency: 0 [0|65535] "" 256 123 DUMMY_NODE_VECTOR0 Vector__XXX;

EV_ evCmdControlAudioDevice: 0 [0|1] "" 0 124 DUMMY_NODE_VECTOR0 Vector__XXX;

EV_ evCmdChangeStringValue: 0 [0|0] "" 0 125 DUMMY_NODE_VECTOR8000 Vector__XXX;

EV_ evCmdChangeStringObjectId: 0 [0|65535] "" 0 126 DUMMY_NODE_VECTOR0 Vector__XXX;

EV_ evCmdChangeString: 0 [0|1] "" 0 127 DUMMY_NODE_VECTOR0 Vector__XXX;

EV_ evCmdChangeSoftMaskType: 0 [1|2] "" 1 128 DUMMY_NODE_VECTOR0 Vector__XXX;

EV_ evCmdChangeSoftKeyMaskId: 0 [0|65535] "" 0 129 DUMMY_NODE_VECTOR0 Vector__XXX;

EV_ evCmdChangeSoftKeyMask: 0 [0|1] "" 0 130 DUMMY_NODE_VECTOR0 Vector__XXX;

EV_ evCmdChangeSoftDataMaskId: 0 [0|65535] "" 0 131 DUMMY_NODE_VECTOR0 Vector__XXX;

EV_ evCmdChangeSizeWidth: 0 [0|65535] "" 0 132 DUMMY_NODE_VECTOR0 Vector__XXX;

EV_ evCmdChangeSizeID: 0 [0|65535] "" 0 133 DUMMY_NODE_VECTOR0 Vector__XXX;

EV_ evCmdChangeSizeHeight: 0 [0|65535] "" 0 134 DUMMY_NODE_VECTOR0 Vector__XXX;

EV_ evCmdChangeSize: 0 [0|1] "" 0 135 DUMMY_NODE_VECTOR0 Vector__XXX;

EV_ evCmdChangePriorityValue: 0 [0|255] "" 0 136 DUMMY_NODE_VECTOR0 Vector__XXX;

EV_ evCmdChangePriorityID: 0 [0|65535] "" 0 137 DUMMY_NODE_VECTOR0 Vector__XXX;

EV_ evCmdChangePriority: 0 [0|1] "" 0 138 DUMMY_NODE_VECTOR0 Vector__XXX;

EV_ evCmdChangePoylgonScaleWidth: 0 [0|65535] "" 0 139 DUMMY_NODE_VECTOR0 Vector__XXX;

EV_ evCmdChangePoylgonScaleId: 0 [0|65535] "" 0 140 DUMMY_NODE_VECTOR0 Vector__XXX;

EV_ evCmdChangePoylgonScaleHeight: 0 [0|65535] "" 0 141 DUMMY_NODE_VECTOR0 Vector__XXX;

EV_ evCmdChangePoylgonScale: 0 [0|1] "" 0 142 DUMMY_NODE_VECTOR0 Vector__XXX;

EV_ evCmdChangePolygonPointY: 0 [0|1] "" 0 143 DUMMY_NODE_VECTOR0 Vector__XXX;

EV_ evCmdChangePolygonPointX: 0 [0|1] "" 0 144 DUMMY_NODE_VECTOR0 Vector__XXX;

EV_ evCmdChangePolygonPointIndex: 0 [0|255] "" 0 145 DUMMY_NODE_VECTOR0 Vector__XXX;

EV_ evCmdChangePolygonPointId: 0 [0|1] "" 0 146 DUMMY_NODE_VECTOR0 Vector__XXX;

EV_ evCmdChangePolygonPoint: 0 [0|1] "" 0 147 DUMMY_NODE_VECTOR0 Vector__XXX;

EV_ evCmdChangeNumericValue: 0 [0|10000000] "" 0 148 DUMMY_NODE_VECTOR0 Vector__XXX;

EV_ evCmdChangeNumericObjecId: 0 [0|65535] "" 0 149 DUMMY_NODE_VECTOR0 Vector__XXX;

EV_ evCmdChangeNumeric: 0 [0|1] "" 0 150 DUMMY_NODE_VECTOR0 Vector__XXX;

EV_ evCmdChangeMaskWorkingSetId: 0 [0|65535] "" 0 151 DUMMY_NODE_VECTOR0 Vector__XXX;

EV_ evCmdChangeMaskMaskId: 0 [0|65535] "" 0 152 DUMMY_NODE_VECTOR0 Vector__XXX;

EV_ evCmdChangeListObjectId: 0 [0|65535] "" 0 153 DUMMY_NODE_VECTOR0 Vector__XXX;

EV_ evCmdChangeListNewId: 0 [0|65535] "" 0 154 DUMMY_NODE_VECTOR0 Vector__XXX;

EV_ evCmdChangeListItemIndex: 0 [0|255] "" 0 155 DUMMY_NODE_VECTOR0 Vector__XXX;

EV_ evCmdChangeListItem: 0 [0|1] "" 0 156 DUMMY_NODE_VECTOR0 Vector__XXX;

EV_ evCmdChangeLineWidth: 0 [0|255] "" 1 157 DUMMY_NODE_VECTOR0 Vector__XXX;

EV_ evCmdChangeLineID: 0 [0|65535] "" 0 158 DUMMY_NODE_VECTOR0 Vector__XXX;

EV_ evCmdChangeLineColor: 0 [0|255] "" 0 159 DUMMY_NODE_VECTOR0 Vector__XXX;

EV_ evCmdChangeLineArt: 0 [0|65535] "" 65535 160 DUMMY_NODE_VECTOR0 Vector__XXX;

EV_ evCmdChangeLine: 0 [0|1] "" 0 161 DUMMY_NODE_VECTOR0 Vector__XXX;

EV_ evCmdChangeFontType: 0 [0|255] "" 0 162 DUMMY_NODE_VECTOR0 Vector__XXX;

EV_ evCmdChangeFontStyle: 0 [0|255] "" 0 163 DUMMY_NODE_VECTOR0 Vector__XXX;

EV_ evCmdChangeFontSize: 0 [0|255] "" 0 164 DUMMY_NODE_VECTOR0 Vector__XXX;

EV_ evCmdChangeFontID: 0 [0|65535] "" 0 165 DUMMY_NODE_VECTOR0 Vector__XXX;

EV_ evCmdChangeFontColor: 0 [0|255] "" 0 166 DUMMY_NODE_VECTOR0 Vector__XXX;

EV_ evCmdChangeFont: 0 [0|1] "" 0 167 DUMMY_NODE_VECTOR0 Vector__XXX;

EV_ evCmdChangeFillType: 0 [0|255] "" 0 168 DUMMY_NODE_VECTOR0 Vector__XXX;

EV_ evCmdChangeFillPatternID: 0 [0|65535] "" 65535 169 DUMMY_NODE_VECTOR0 Vector__XXX;

EV_ evCmdChangeFillID: 0 [0|65535] "" 0 170 DUMMY_NODE_VECTOR0 Vector__XXX;

EV_ evCmdChangeFillColor: 0 [0|255] "" 0 171 DUMMY_NODE_VECTOR0 Vector__XXX;

EV_ evCmdChangeFill: 0 [0|1] "" 0 172 DUMMY_NODE_VECTOR0 Vector__XXX;

EV_ evCmdChangeEndPointWidth: 0 [0|65535] "" 0 173 DUMMY_NODE_VECTOR0 Vector__XXX;

EV_ evCmdChangeEndPointID: 0 [0|65535] "" 0 174 DUMMY_NODE_VECTOR0 Vector__XXX;

EV_ evCmdChangeEndPointHeight: 0 [0|65535] "" 0 175 DUMMY_NODE_VECTOR0 Vector__XXX;

EV_ evCmdChangeEndPointDirection: 0 [0|1] "" 0 176 DUMMY_NODE_VECTOR0 Vector__XXX;

EV_ evCmdChangeEndPoint: 0 [0|1] "" 0 177 DUMMY_NODE_VECTOR0 Vector__XXX;

EV_ evCmdChangeChildY: 0 [-127|127] "" 0 178 DUMMY_NODE_VECTOR0 Vector__XXX;

EV_ evCmdChangeChildX: 0 [-127|127] "" 0 179 DUMMY_NODE_VECTOR0 Vector__XXX;

EV_ evCmdChangeChildPosition: 0 [0|1] "" 0 180 DUMMY_NODE_VECTOR0 Vector__XXX;

EV_ evCmdChangeChildParentId: 0 [0|65535] "" 0 181 DUMMY_NODE_VECTOR0 Vector__XXX;

EV_ evCmdChangeChildObjectId: 0 [0|65535] "" 0 182 DUMMY_NODE_VECTOR0 Vector__XXX;

EV_ evCmdChangeChildLocation: 0 [0|1] "" 0 183 DUMMY_NODE_VECTOR0 Vector__XXX;

EV_ evCmdChangeBkColorValue: 0 [0|255] "" 0 184 DUMMY_NODE_VECTOR0 Vector__XXX;

EV_ evCmdChangeBkColorID: 0 [0|65535] "" 0 185 DUMMY_NODE_VECTOR0 Vector__XXX;

EV_ evCmdChangeBkColor: 0 [0|1] "" 0 186 DUMMY_NODE_VECTOR0 Vector__XXX;

EV_ evCmdChangeAttributeValuePrev: 0 [0|1] "" 0 187 DUMMY_NODE_VECTOR0 Vector__XXX;

EV_ evCmdChangeAttributeValueNext: 0 [0|1] "" 0 188 DUMMY_NODE_VECTOR0 Vector__XXX;

EV_ evCmdChangeAttributeValueMin: 0 [0|0] "" 0 189 DUMMY_NODE_VECTOR0 Vector__XXX;

EV_ evCmdChangeAttributeValueMax: 0 [0|415029] "" 255 190 DUMMY_NODE_VECTOR0 Vector__XXX;

EV_ evCmdChangeAttributeValueEnblCyc: 0 [0|1] "" 0 191 DUMMY_NODE_VECTOR0 Vector__XXX;

EV_ evCmdChangeAttributeValueCycle: 0 [1|50] "" 1 192 DUMMY_NODE_VECTOR0 Vector__XXX;

EV_ evCmdChangeAttributeValue: 0 [0|10000000] "" 0 193 DUMMY_NODE_VECTOR0 Vector__XXX;

EV_ evCmdChangeAttributeUseFloat: 0 [0|1] "" 0 194 DUMMY_NODE_VECTOR0 Vector__XXX;

EV_ evCmdChangeAttributeID: 0 [0|65535] "" 0 195 DUMMY_NODE_VECTOR0 Vector__XXX;

EV_ evCmdChangeAttributeAID: 0 [0|255] "" 0 196 DUMMY_NODE_VECTOR0 Vector__XXX;

EV_ evCmdChangeAttribute: 0 [0|1] "" 0 197 DUMMY_NODE_VECTOR0 Vector__XXX;

EV_ evCmdChangeActiveMask: 0 [0|1] "" 0 198 DUMMY_NODE_VECTOR0 Vector__XXX;

EV_ EvISOBUS_PWR: 1 [0|13] "V" 12 199 DUMMY_NODE_VECTOR0 Vector__XXX;

EV_ EvISOBUS_ECU_PWR: 1 [0|13] "V" 12 200 DUMMY_NODE_VECTOR0 Vector__XXX;
CM_ BO_ 2365463294 "Esimated flow of auxiliary valve number 0 ";
CM_ SG_ 2365463294 Valve10LimitStatus "Parameter used to report the tractor ECUs present limit status associated with a parameter whose commands are persistent";
CM_ BO_ 2365463550 "Esimated flow of auxiliary valve number 0 ";
CM_ SG_ 2365463550 Valve11LimitStatus "Parameter used to report the tractor ECUs present limit status associated with a parameter whose commands are persistent";
CM_ BO_ 2365463806 "Esimated flow of auxiliary valve number 0 ";
CM_ SG_ 2365463806 Valve12LimitStatus "Parameter used to report the tractor ECUs present limit status associated with a parameter whose commands are persistent";
CM_ BO_ 2365464062 "Esimated flow of auxiliary valve number 0 ";
CM_ SG_ 2365464062 Valve13LimitStatus "Parameter used to report the tractor ECUs present limit status associated with a parameter whose commands are persistent";
CM_ BO_ 2365464318 "Esimated flow of auxiliary valve number 0 ";
CM_ SG_ 2365464318 Valve14LimitStatus "Parameter used to report the tractor ECUs present limit status associated with a parameter whose commands are persistent";
CM_ BO_ 2365464574 "Esimated flow of auxiliary valve number 0 ";
CM_ SG_ 2365464574 Valve15LimitStatus "Parameter used to report the tractor ECUs present limit status associated with a parameter whose commands are persistent";
CM_ BO_ 2365464830 "Auxiliary valve measured flow";
CM_ SG_ 2365464830 Valve0LimitStatus "Parameter used to report the tractor ECUs present limit status associated with a parameter whose commands are persistent";
CM_ BO_ 2365465086 "Auxiliary valve measured flow";
CM_ SG_ 2365465086 Valve1LimitStatus "Parameter used to report the tractor ECUs present limit status associated with a parameter whose commands are persistent";
CM_ BO_ 2365465342 "Auxiliary valve measured flow";
CM_ SG_ 2365465342 Valve2LimitStatus "Parameter used to report the tractor ECUs present limit status associated with a parameter whose commands are persistent";
CM_ BO_ 2365465598 "Auxiliary valve measured flow";
CM_ SG_ 2365465598 Valve3LimitStatus "Parameter used to report the tractor ECUs present limit status associated with a parameter whose commands are persistent";
CM_ BO_ 2365465854 "Auxiliary valve measured flow";
CM_ SG_ 2365465854 Valve4LimitStatus "Parameter used to report the tractor ECUs present limit status associated with a parameter whose commands are persistent";
CM_ BO_ 2365466110 "Auxiliary valve measured flow";
CM_ SG_ 2365466110 Valve5LimitStatus "Parameter used to report the tractor ECUs present limit status associated with a parameter whose commands are persistent";
CM_ BO_ 2365466366 "Auxiliary valve measured flow";
CM_ SG_ 2365466366 Valve6LimitStatus "Parameter used to report the tractor ECUs present limit status associated with a parameter whose commands are persistent";
CM_ BO_ 2365466622 "Auxiliary valve measured flow";
CM_ SG_ 2365466622 Valve7LimitStatus "Parameter used to report the tractor ECUs present limit status associated with a parameter whose commands are persistent";
CM_ BO_ 2365466878 "Auxiliary valve measured flow";
CM_ SG_ 2365466878 Valve8LimitStatus "Parameter used to report the tractor ECUs present limit status associated with a parameter whose commands are persistent";
CM_ BO_ 2365467134 "Auxiliary valve measured flow";
CM_ SG_ 2365467134 Valve9LimitStatus "Parameter used to report the tractor ECUs present limit status associated with a parameter whose commands are persistent";
CM_ BO_ 2365467390 "Auxiliary valve measured flow";
CM_ SG_ 2365467390 Valve10LimitStatus "Parameter used to report the tractor ECUs present limit status associated with a parameter whose commands are persistent";
CM_ BO_ 2365467646 "Auxiliary valve measured flow";
CM_ SG_ 2365467646 Valve11LimitStatus "Parameter used to report the tractor ECUs present limit status associated with a parameter whose commands are persistent";
CM_ BO_ 2365467902 "Auxiliary valve measured flow";
CM_ SG_ 2365467902 Valve12LimitStatus "Parameter used to report the tractor ECUs present limit status associated with a parameter whose commands are persistent";
CM_ BO_ 2365468158 "Auxiliary valve measured flow";
CM_ SG_ 2365468158 Valve13LimitStatus "Parameter used to report the tractor ECUs present limit status associated with a parameter whose commands are persistent";
CM_ BO_ 2365468414 "Auxiliary valve measured flow";
CM_ SG_ 2365468414 Valve14LimitStatus "Parameter used to report the tractor ECUs present limit status associated with a parameter whose commands are persistent";
CM_ BO_ 2365468670 "Auxiliary valve measured flow";
CM_ SG_ 2365468670 Valve15LimitStatus "Parameter used to report the tractor ECUs present limit status associated with a parameter whose commands are persistent";
CM_ BO_ 2365468926 "Auxiliary Valve Command";
CM_ BO_ 2365469182 "Auxiliary Valve Command";
CM_ BO_ 2365469438 "Auxiliary Valve Command";
CM_ BO_ 2365469694 "Auxiliary Valve Command";
CM_ BO_ 2365469950 "Auxiliary Valve Command";
CM_ BO_ 2365470206 "Auxiliary Valve Command";
CM_ BO_ 2365470462 "Auxiliary Valve Command";
CM_ BO_ 2365470718 "Auxiliary Valve Command";
CM_ BO_ 2365470974 "Auxiliary Valve Command";
CM_ BO_ 2365471230 "Auxiliary Valve Command";
CM_ BO_ 2365471486 "Auxiliary Valve Command";
CM_ BO_ 2365471742 "Auxiliary Valve Command";
CM_ BO_ 2365471998 "Auxiliary Valve Command";
CM_ BO_ 2365472254 "Auxiliary Valve Command";
CM_ BO_ 2365472510 "Auxiliary Valve Command";
CM_ BO_ 2365472766 "Auxiliary Valve Command";
CM_ BO_ 2566799614 "Lighting Data";
CM_ BO_ 2365473278 "Lighting Command";
CM_ BO_ 2365473534 "Hitch and PTO Commands";
CM_ BO_ 2365473790 "Primary or Rear Power Take off Output Shaft
";
CM_ SG_ 2365473790 RearPTOEngagementRqStatus "Parameter used to report the tractor ECUs status associated with a parameter whose requests are transient.";
CM_ SG_ 2365473790 RearPTOShaftSpeedLimitStatus "Parameter used to report the tractor ECUs present limit status associated with a parameter whose commands are persistent";
CM_ SG_ 2365473790 RearPTOEconomyModeRqStatus "Parameter used to report the tractor ECUs status associated with a parameter whose requests are transient.";
CM_ SG_ 2365473790 RearPTOModeRqStatus "Parameter used to report the tractor ECUs status associated with a parameter whose requests are transient.";
CM_ BO_ 2365474046 "Secondary or Front Power Take off Output-Shaft";
CM_ SG_ 2365474046 FrontPTOEngagementRqStatus "Parameter used to report the tractor ECUs status associated with a parameter whose requests are transient.";
CM_ SG_ 2365474046 FrontPTOShaftSpeedLimitStatus "Parameter used to report the tractor ECUs present limit status associated with a parameter whose commands are persistent";
CM_ SG_ 2365474046 FrontPTOEconomyModeRqStatus "Parameter used to report the tractor ECUs status associated with a parameter whose requests are transient.";
CM_ SG_ 2365474046 FrontPTOModeRqStatus "Parameter used to report the tractor ECUs status associated with a parameter whose requests are transient.";
CM_ BO_ 2365474302 "Primary or Rear Hitch Status";
CM_ SG_ 2365474302 RearHitchPositionLimitStatus "Parameter used to report the tractor ECUs present limit status associated with a parameter whose commands are persistent";
CM_ BO_ 2365474558 "Secondary or Front Hitch Status";
CM_ SG_ 2365474558 FrontHitchPositionLimitStatus "Parameter used to report the tractor ECUs present limit status associated with a parameter whose commands are persistent";
CM_ BO_ 2566801406 "Maintain Power";
CM_ BO_ 2365475070 "Wheel-based Speed and Distance";
CM_ SG_ 2365475070 OperatorDirectionReversed "This parameter indicates whether the reported direction is reversed from the perspective of the operator.";
CM_ BO_ 2365475326 "Ground-based Speed and Distance";
CM_ BO_ 2566842110 "Time/Date";
CM_ SG_ 2566842110 Minutes "The minutes component of the current time of day.  This should be reported as the minutes component of the current time ...";
CM_ SG_ 2566842110 Hours "The hour component of the current time of day.  This should be reported as the hour component of the current time at ...";
CM_ SG_ 2566842110 Day "The day component of the current calendar date.  This should be reported as the day component of the current date at ...";
CM_ SG_ 2566842110 LocalMinuteOffset "The minute component of the offset between the UTC time and date and a local time zone time and date.  This is the ...";
CM_ SG_ 2566842110 LocalHourOffset "The hour component of the offset between the UTC (Universal Time Coordinate) time and date and a local time zone time ...";
CM_ BO_ 2566848766 "Proprietary B0";
CM_ BO_ 2566849022 "Proprietary B1";
CM_ BO_ 2566849278 "Proprietary B2";
CM_ BO_ 2566849534 "Proprietary B3";
CM_ BO_ 2583299838 "GNSS pseudorange measurement noise statistics can be translated in the position domain in order to give statistical measures 
of the quality of the position solution. Intended for use with a Receiver Autonomous Integrity Monitoring (RAIM) application.
";
CM_ SG_ 2583299838 SequenceID "An upward counting number used to tie related information together between different PGNs.
";
CM_ SG_ 2583299838 RMSofPositionUncertainty "Error distances expressed in meters.";
CM_ SG_ 2583299838 STDofMajorAxis "Error distances expressed in meters.";
CM_ SG_ 2583299838 STDofMinorAxis "Error distances expressed in meters.";
CM_ SG_ 2583299838 OrientationOfMinorAxis "Degrees clockwise relative to True North.";
CM_ SG_ 2583299838 STDofLatError "Error distances expressed in meters.";
CM_ SG_ 2583299838 STDofLonError "Error distances expressed in meters";
CM_ SG_ 2583299838 STDofAltError "Error distances expressed in meters";
CM_ BO_ 2583168510 "This PGN conveys a comprehensive set of Global Navigation Satellite System (GNSS) parameters, including position 
information
";
CM_ SG_ 2583168510 SequenceID "An upward counting number used to tie related information together between different PGNs.
";
CM_ SG_ 2583168510 PositionDate "Days since January 1, 1970,  Date is relative to UTC Time";
CM_ SG_ 2583168510 PositionTime "24 hour clock, 0 =  midnight,  time is in UTC";
CM_ SG_ 2583168510 LatitudeLow "Latitude referenced to WGS-84";
CM_ SG_ 2583168510 LatitudeHigh "Latitude referenced to WGS-84";
CM_ SG_ 2583168510 LongitudeLow "Longitude referenced to WGS-84";
CM_ SG_ 2583168510 LongitudeHigh "Longitude referenced to WGS-84";
CM_ SG_ 2583168510 AltitudeLow "Altitude referenced to WGS-84";
CM_ SG_ 2583168510 AltitudeHigh "Altitude referenced to WGS-84";
CM_ SG_ 2583168510 NumberOfSVs "Numeric count, event counter, sequence counter";
CM_ SG_ 2583168510 HDOP "Dilution of Precision (DOP) indicates the contribution of satellite configuration geometry to positioning error
";
CM_ SG_ 2583168510 PDOP "Dilution of Precision (DOP) indicates the contribution of satellite configuration geometry to positioning error
";
CM_ SG_ 2583168510 GeoidalSeparation "The difference between the earth ellipsoid and mean-sea-level (geoid) defined by the reference datum used in the position solution ' -' = mean-sea-level below ellipsoid
";
CM_ SG_ 2583168510 NumberOfReferenceStations "Numeric count, event counter, sequence counter";
CM_ SG_ 2583168510 ReferenceStationID1 "Reference Station ID";
CM_ SG_ 2583168510 AgeOfDGNSSCorrections1 "Age of Differential corrections";
CM_ BO_ 2314732030 "This PGN provides latitude and longitude referenced to WGS84";
CM_ BO_ 2563309310 "Extended TP (Command)";
CM_ BO_ 2563243774 "Extended TP (Data)";
CM_ BO_ 2364540158 "Electronic Engine Controller #1";
CM_ SG_ 2364540158 ActlEngPrcntTorqueHighResolution "This parameter displays an additional torque in percent of the reference engine torque.";
CM_ SG_ 2364540158 EngTorqueMode "State signal which indicates which engine torque mode is currently generating, limiting, or controlling the torque.";
CM_ SG_ 2364540158 DriversDemandEngPercentTorque "The requested torque output of the engine by the driver.";
CM_ SG_ 2364540158 ActualEngPercentTorque "The calculated output torque of the engine.";
CM_ SG_ 2364540158 SrcAddrssOfCtrllngDvcForEngCtrl "The source address of the SAE J1939 device currently controlling the engine.";
CM_ SG_ 2364540158 EngStarterMode "There are several phases in a starting action and different reasons why a start cannot take place.";
CM_ BO_ 2628517630 "File Server to Client";
CM_ SG_ 2628517630 FSServerCommand "File Server Command";
CM_ SG_ 2628517630 VI_TAN "Transaction Number for Volume Initialization";
CM_ SG_ 2628517630 DF_TAN "Transaction Number for Delete File";
CM_ SG_ 2628517630 GSP_VersionNumber "The version of ISO11783-13 that this File Server meets.";
CM_ SG_ 2628517630 CCD_TAN "Transaction Number for Change Current Directory";
CM_ SG_ 2628517630 GCD_TAN "Transaction Number for Get Current Directory";
CM_ SG_ 2628517630 FDT_TAN "Transaction Number for Get File Data & Time";
CM_ SG_ 2628517630 SA_TAN "Transaction Number for Set File Attributes";
CM_ SG_ 2628517630 GA_TAN "Transaction Number for Get File Attributes";
CM_ SG_ 2628517630 MF_TAN "Transaction Number for Move File";
CM_ SG_ 2628517630 CF_TAN "Transaction Number for Close File";
CM_ SG_ 2628517630 WF_TAN "Transaction Number for Write File";
CM_ SG_ 2628517630 RF_TAN "Transaction Number for Rename File";
CM_ SG_ 2628517630 SF_TAN "Transaction Number for Seek File";
CM_ SG_ 2628517630 OF_TAN "Transaction Number for Open File";
CM_ SG_ 2628517630 FSBusyReading "Busy reading";
CM_ SG_ 2628517630 FSBusyWriting "Busy writing";
CM_ SG_ 2628517630 VI_ErrorCode "Error Code for Volume Initialization";
CM_ SG_ 2628517630 DF_ErrorCode "Error Code for Delete File";
CM_ SG_ 2628517630 GSP_MaxNrSimultaneousFilesOpen "The number of files that can maximally be opened simultaneous at the File Server.";
CM_ SG_ 2628517630 CCD_ErrorCode "Error Code for Change Current Directory";
CM_ SG_ 2628517630 GCD_ErrorCode "ErrorCode for Get Current Directory";
CM_ SG_ 2628517630 SA_ErrorCode "Error Code for Set File Attribute";
CM_ SG_ 2628517630 GA_ErrorCode "Error Code for Get File Attribute";
CM_ SG_ 2628517630 MF_ErrorCode "Error Code for Move File";
CM_ SG_ 2628517630 CF_ErrorCode "Error Code for Close File";
CM_ SG_ 2628517630 WF_ErrorCode "Error Code for Write File";
CM_ SG_ 2628517630 OF_ErrorCode "Error Code for Open File";
CM_ SG_ 2628517630 FSNumberOfOpenFiles "Number of open files";
CM_ SG_ 2628517630 SF_ErrorCode "ErrorCode for Seek File";
CM_ SG_ 2628517630 RF_ErrorCode "Error Code for Read File";
CM_ SG_ 2628517630 FDT_ErrorCode "Error Code for Get File Data & Time";
CM_ SG_ 2628517630 WF_Count "Number of written bytes";
CM_ SG_ 2628517630 GSP_SupportMultipleVolumes "File Server Capabilities for Get File Server Properties";
CM_ SG_ 2628517630 RF_Count "Number of read bytes or number of read directory entries";
CM_ SG_ 2628517630 GCD_TotalSpace "Total Volume Space for Get Current Directory";
CM_ SG_ 2628517630 OF_Handle "Handle for Open File";
CM_ SG_ 2628517630 GA_ATTR_ReadOnly "File Attribute Read-OnlyFile Attribute Read-Only";
CM_ SG_ 2628517630 FDT_DateDay "Day of File Date";
CM_ SG_ 2628517630 GA_ATTR_Hidden "File Attribute HiddenFile Attribute Hidden";
CM_ SG_ 2628517630 GA_ATTR_IsVolume "File Attribute SystemFile Attribute System";
CM_ SG_ 2628517630 VI_ATTR_Directory "File Attribute DirectoryFile Attribute DirectoryFile Attribute DirectoryFile Attribute Directory";
CM_ SG_ 2628517630 GA_ATTR_SupportsLongFilenames "File Attribute ArchiveFile Attribute Archive";
CM_ SG_ 2628517630 FDT_DateMonth "Month of File Date";
CM_ SG_ 2628517630 GA_ATTR_VolumeRemovable "Attribute Removable MediaAttribute Removable Media";
CM_ SG_ 2628517630 GA_Size "The number of bytes in a file.";
CM_ SG_ 2628517630 SF_Position "Position of Seek File response";
CM_ SG_ 2628517630 FDT_DateYear "Year of File Date";
CM_ SG_ 2628517630 FDT_TimeSeconds "Day of File Time";
CM_ SG_ 2628517630 FDT_TimeMinutes "Minutes of File Time";
CM_ SG_ 2628517630 FDT_TimeHour "Hour of File Time";
CM_ SG_ 2628517630 GCD_FreeSpace "Free Volume Space for Get Current Directory";
CM_ SG_ 2628517630 GCD_PathName "Length of path name string for Get Current Directory";
CM_ BO_ 2628452094 "File Client to Server";
CM_ SG_ 2628452094 FSClientCommand "File Server - Client Command";
CM_ SG_ 2628452094 VI_TAN "Transaction Number for Initailize Volume Request";
CM_ SG_ 2628452094 DF_TAN "Transaction Number for Delete File";
CM_ SG_ 2628452094 MF_TAN "Transaction Number for Move File";
CM_ SG_ 2628452094 OF_TAN "Transaction Number for Open File";
CM_ SG_ 2628452094 SF_TAN "Transaction Number for Seek File";
CM_ SG_ 2628452094 WF_TAN "Transaction Number for Write File";
CM_ SG_ 2628452094 CF_TAN "Transaction Number for Close File";
CM_ SG_ 2628452094 RF_TAN "Transaction Number for Read File";
CM_ SG_ 2628452094 GA_TAN "Transaction Number for Get File Attribute";
CM_ SG_ 2628452094 SA_TAN "Transaction Number for Set File Attribute";
CM_ SG_ 2628452094 FDT_TAN "Transaction Number for Get File Data & Time";
CM_ SG_ 2628452094 GCD_TAN "Transaction Number for Get Default Directory";
CM_ SG_ 2628452094 CCD_TAN "Transaction Number for Change Default Directory";
CM_ SG_ 2628452094 FDT_PathName "Length of path name string for Get File Date and Time";
CM_ SG_ 2628452094 GA_PathName "Length of path name string for Get File Attributes";
CM_ SG_ 2628452094 DF_DeleteMode "Copy mode for Move File";
CM_ SG_ 2628452094 MF_MoveModeCopy "Copy mode for Move File";
CM_ SG_ 2628452094 CCD_PathName "Length of path name string for Change Current Directory";
CM_ SG_ 2628452094 OF_FlagReadWrite "Read/Write/Both/Directory Flag for Open File";
CM_ SG_ 2628452094 SF_Handle "Handle for Seek File";
CM_ SG_ 2628452094 RF_Handle "Handle for Read File";
CM_ SG_ 2628452094 WF_Handle "Handle for Write File";
CM_ SG_ 2628452094 CF_Handle "Handle for Close File";
CM_ SG_ 2628452094 SET_ATTR_ReadOnly "SetFile Attribute Read-Only";
CM_ SG_ 2628452094 VI_Flag_UsingSpaceSpecified "Create volume using space specified";
CM_ SG_ 2628452094 DF_DeleteModeForce "Force mode for Move File";
CM_ SG_ 2628452094 MF_MoveModeForce "Force mode for Move File";
CM_ SG_ 2628452094 DF_DeleteModeRecursive "Recursive mode for Move File";
CM_ SG_ 2628452094 MF_MoveModeRecursive "Recursive mode for Move File";
CM_ SG_ 2628452094 OF_FlagCreateNew "Create a new file if not yet existing";
CM_ SG_ 2628452094 SET_ATTR_Hidden "SetFile Attribute Hidden";
CM_ SG_ 2628452094 OF_FlagAppend "Open file for appending data to the end of the file";
CM_ SG_ 2628452094 OF_FlagExclusiveAccess "Open file with exclusive access (fails if already open)";
CM_ SG_ 2628452094 VI_Space "The space in units of 512";
CM_ SG_ 2628452094 SA_PathName "Length of path name string for Set File Attributes";
CM_ SG_ 2628452094 DF_PathName "Length of path name string for Delete File";
CM_ SG_ 2628452094 WF_Count "Byte count of data to be written to file";
CM_ SG_ 2628452094 MF_SourcePathNameLength "Length of source path name string for Move File";
CM_ SG_ 2628452094 OF_PathName "Length of path name string for Open File";
CM_ SG_ 2628452094 SF_PositionMode "Position Mode for Seek File";
CM_ SG_ 2628452094 RF_Count "Number of bytes or number of directory entries to be read";
CM_ SG_ 2628452094 SF_Offset "Offset for Seek File";
CM_ SG_ 2628452094 RF_ReportHiddenFiles "Report Hidden Files";
CM_ SG_ 2628452094 MF_DestinationPathNameLength "Length of destination path name string for Move File";
CM_ SG_ 2628452094 VI_Flag_OverwriteExisting "Create a new volume if not yet existing (fails if existing volume)";
CM_ SG_ 2628452094 VI_VolumeName "Length of path name string for Initailize Volume Request";
CM_ BO_ 2563178238 "General purpose valve estimated flow";
CM_ SG_ 2563178238 ValveLimitStatus "Parameter used to report the tractor ECUs present limit status associated with a parameter whose commands are persistent";
CM_ BO_ 2563112702 "General Purpose valve measured flow";
CM_ SG_ 2563112702 ValveLimitStatus "Parameter used to report the tractor ECUs present limit status associated with a parameter whose commands are persistent";
CM_ BO_ 2563047166 "General Purpose valve command";
CM_ BO_ 2360213246 "Guidance System Command";
CM_ SG_ 2360213246 CurvatureCommand "Desired course curvature over ground that a machine's steering system is required to achieve.";
CM_ SG_ 2360213246 CurvatureCommandStatus "This parameter indicates whether the guidance system is attempting to control steering with this command.";
CM_ BO_ 2360147710 "Guidance Machine Status";
CM_ SG_ 2360147710 EstimatedCurvature "The machine steering system's estimate of the curvature of the current turn.";
CM_ SG_ 2360147710 MechanicalSystemLockout "The state of a lockout switch that allows operators to disable automatic steering system functions.";
CM_ SG_ 2360147710 SteeringSystemReadiness "The machine steering system indicates that it is free from faults that would preclude guidance system operation.";
CM_ SG_ 2360147710 SteeringInputPositionStatus "The machine steering system indicates if manual steering is in correct position for guidance to function.";
CM_ SG_ 2360147710 RequestResetCommandStatus "The machine steering system request to the automatic guidance system to change Curvature Command Status state.";
CM_ EV_ evCmdEnableErrorHandling "Enables/Disables Object Pool Error Handling of the VT";
BA_DEF_ SG_  "GenSigStartValue" INT -2147483648 2147483647;
BA_DEF_ SG_  "SigType" ENUM  "Default","Range","RangeSigned","ASCII","Discrete","Control","ReferencePGN","DTC","StringDelimiter","StringLength","StringLengthControl";
BA_DEF_ SG_  "GenSigSendType" ENUM  "Cyclic","OnWrite","OnWriteWithRepetition","OnChange","OnChangeWithRepetition","IfActive","IfActiveWithRepetition","NoSigSendType";
BA_DEF_ SG_  "SPN" INT 0 524287;
BA_DEF_ BO_  "GenMsgCycleTimeFast" INT 0 3600000;
BA_DEF_ BO_  "GenMsgRequestable" INT 0 1;
BA_DEF_ BO_  "GenMsgCycleTime" INT 0 3600000;
BA_DEF_ BO_  "GenMsgSendType" ENUM  "cyclic","NotUsed","IfActive","NotUsed","NotUsed","NotUsed","NotUsed","NotUsed","noMsgSendType","vector_leerstring";
BA_DEF_ BO_  "VFrameFormat" ENUM  "StandardCAN","ExtendedCAN","reserved","J1939PG","vector_leerstring";
BA_DEF_ BO_  "SingleFrame" INT 0 1;
BA_DEF_ SG_  "DDI" INT 0 65535;
BA_DEF_ SG_  "SystemSignalLongSymbol" STRING ;
BA_DEF_ EV_  "SystemEnvVarLongSymbol" STRING ;
BA_DEF_DEF_  "GenSigStartValue" 0;
BA_DEF_DEF_  "SigType" "Default";
BA_DEF_DEF_  "GenSigSendType" "NoSigSendType";
BA_DEF_DEF_  "SPN" 0;
BA_DEF_DEF_  "GenMsgCycleTimeFast" 0;
BA_DEF_DEF_  "GenMsgRequestable" 1;
BA_DEF_DEF_  "GenMsgCycleTime" 0;
BA_DEF_DEF_  "GenMsgSendType" "noMsgSendType";
BA_DEF_DEF_  "VFrameFormat" "J1939PG";
BA_DEF_DEF_  "SingleFrame" 1;
BA_DEF_DEF_  "DDI" 0;
BA_DEF_DEF_  "SystemSignalLongSymbol" "";
BA_DEF_DEF_  "SystemEnvVarLongSymbol" "";
BA_ "GenMsgCycleTime" BO_ 2365463294 100;
BA_ "GenMsgSendType" BO_ 2365463294 8.59427586193365E-317;
BA_ "GenMsgCycleTime" BO_ 2365463550 100;
BA_ "GenMsgSendType" BO_ 2365463550 8.5932837781168E-317;
BA_ "GenMsgCycleTime" BO_ 2365463806 100;
BA_ "GenMsgSendType" BO_ 2365463806 8.59229169429995E-317;
BA_ "GenMsgCycleTime" BO_ 2365464062 100;
BA_ "GenMsgSendType" BO_ 2365464062 8.5912996104831E-317;
BA_ "GenMsgCycleTime" BO_ 2365464318 100;
BA_ "GenMsgSendType" BO_ 2365464318 8.59030752666625E-317;
BA_ "GenMsgCycleTime" BO_ 2365464574 100;
BA_ "GenMsgSendType" BO_ 2365464574 8.5893154428494E-317;
BA_ "GenMsgCycleTime" BO_ 2365464830 100;
BA_ "GenMsgSendType" BO_ 2365464830 8.58832335903256E-317;
BA_ "GenMsgCycleTime" BO_ 2365465086 100;
BA_ "GenMsgSendType" BO_ 2365465086 8.58741032571904E-317;
BA_ "GenMsgCycleTime" BO_ 2365465342 100;
BA_ "GenMsgSendType" BO_ 2365465342 8.58649729240553E-317;
BA_ "GenMsgCycleTime" BO_ 2365465598 100;
BA_ "GenMsgSendType" BO_ 2365465598 8.58558425909201E-317;
BA_ "GenMsgCycleTime" BO_ 2365465854 100;
BA_ "GenMsgSendType" BO_ 2365465854 8.5846712257785E-317;
BA_ "GenMsgCycleTime" BO_ 2365466110 100;
BA_ "GenMsgSendType" BO_ 2365466110 8.58375819246498E-317;
BA_ "GenMsgCycleTime" BO_ 2365466366 100;
BA_ "GenMsgSendType" BO_ 2365466366 8.58284515915147E-317;
BA_ "GenMsgCycleTime" BO_ 2365466622 100;
BA_ "GenMsgSendType" BO_ 2365466622 8.58192817331279E-317;
BA_ "GenMsgCycleTime" BO_ 2365466878 100;
BA_ "GenMsgSendType" BO_ 2365466878 8.58101513999927E-317;
BA_ "GenMsgCycleTime" BO_ 2365467134 100;
BA_ "GenMsgSendType" BO_ 2365467134 8.58010210668576E-317;
BA_ "GenMsgCycleTime" BO_ 2365467390 100;
BA_ "GenMsgSendType" BO_ 2365467390 8.57918907337224E-317;
BA_ "GenMsgCycleTime" BO_ 2365467646 100;
BA_ "GenMsgSendType" BO_ 2365467646 8.57827604005873E-317;
BA_ "GenMsgCycleTime" BO_ 2365467902 100;
BA_ "GenMsgSendType" BO_ 2365467902 8.57736300674521E-317;
BA_ "GenMsgCycleTime" BO_ 2365468158 100;
BA_ "GenMsgSendType" BO_ 2365468158 8.5764499734317E-317;
BA_ "GenMsgCycleTime" BO_ 2365468414 100;
BA_ "GenMsgSendType" BO_ 2365468414 8.57553298759302E-317;
BA_ "GenMsgCycleTime" BO_ 2365468670 100;
BA_ "GenMsgSendType" BO_ 2365468670 8.5746199542795E-317;
BA_ "GenMsgCycleTime" BO_ 2365468926 1000;
BA_ "GenMsgSendType" BO_ 2365468926 8.57370692096599E-317;
BA_ "GenMsgCycleTime" BO_ 2365469182 1000;
BA_ "GenMsgSendType" BO_ 2365469182 8.57294013108364E-317;
BA_ "GenMsgCycleTime" BO_ 2365469438 1000;
BA_ "GenMsgSendType" BO_ 2365469438 8.5721733412013E-317;
BA_ "GenMsgCycleTime" BO_ 2365469694 1000;
BA_ "GenMsgSendType" BO_ 2365469694 8.57140655131895E-317;
BA_ "GenMsgCycleTime" BO_ 2365469950 1000;
BA_ "GenMsgSendType" BO_ 2365469950 8.57063976143661E-317;
BA_ "GenMsgCycleTime" BO_ 2365470206 1000;
BA_ "GenMsgSendType" BO_ 2365470206 8.56986901902909E-317;
BA_ "GenMsgCycleTime" BO_ 2365470462 1000;
BA_ "GenMsgSendType" BO_ 2365470462 8.56910222914675E-317;
BA_ "GenMsgCycleTime" BO_ 2365470718 1000;
BA_ "GenMsgSendType" BO_ 2365470718 8.5683354392644E-317;
BA_ "GenMsgCycleTime" BO_ 2365470974 1000;
BA_ "GenMsgSendType" BO_ 2365470974 8.56756469685689E-317;
BA_ "GenMsgCycleTime" BO_ 2365471230 1000;
BA_ "GenMsgSendType" BO_ 2365471230 8.56679790697454E-317;
BA_ "GenMsgCycleTime" BO_ 2365471486 1000;
BA_ "GenMsgSendType" BO_ 2365471486 8.5660311170922E-317;
BA_ "GenMsgCycleTime" BO_ 2365471742 1000;
BA_ "GenMsgSendType" BO_ 2365471742 8.56526432720985E-317;
BA_ "GenMsgCycleTime" BO_ 2365471998 1000;
BA_ "GenMsgSendType" BO_ 2365471998 8.56449753732751E-317;
BA_ "GenMsgCycleTime" BO_ 2365472254 1000;
BA_ "GenMsgSendType" BO_ 2365472254 8.56373074744516E-317;
BA_ "GenMsgCycleTime" BO_ 2365472510 1000;
BA_ "GenMsgSendType" BO_ 2365472510 8.56296395756282E-317;
BA_ "GenMsgCycleTime" BO_ 2365472766 1000;
BA_ "GenMsgSendType" BO_ 2365472766 8.56219716768047E-317;
BA_ "GenMsgCycleTime" BO_ 2566799614 100;
BA_ "GenMsgCycleTime" BO_ 2365473278 100;
BA_ "GenMsgCycleTime" BO_ 2365473534 1000;
BA_ "GenMsgSendType" BO_ 2365473534 8.54526850239137E-317;
BA_ "GenMsgCycleTime" BO_ 2365473790 100;
BA_ "GenMsgSendType" BO_ 2365473790 2;
BA_ "GenMsgCycleTime" BO_ 2365474046 100;
BA_ "GenMsgSendType" BO_ 2365474046 2;
BA_ "GenMsgCycleTime" BO_ 2365474302 100;
BA_ "GenMsgSendType" BO_ 2365474302 8.54054523481712E-317;
BA_ "GenMsgCycleTime" BO_ 2365474558 100;
BA_ "GenMsgSendType" BO_ 2365474558 8.53967963180561E-317;
BA_ "GenMsgCycleTime" BO_ 2566801406 100;
BA_ "GenMsgCycleTime" BO_ 2365475070 100;
BA_ "GenMsgSendType" BO_ 2365475070 8.53733973690691E-317;
BA_ "GenMsgCycleTime" BO_ 2365475326 100;
BA_ "GenMsgSendType" BO_ 2365475326 8.53594844804822E-317;
BA_ "GenMsgCycleTime" BO_ 2566848766 100;
BA_ "GenMsgSendType" BO_ 2566848766 8.53185758450065E-317;
BA_ "GenMsgCycleTime" BO_ 2566849022 100;
BA_ "GenMsgSendType" BO_ 2566849022 8.53028843200946E-317;
BA_ "GenMsgCycleTime" BO_ 2566849278 100;
BA_ "GenMsgSendType" BO_ 2566849278 8.52871927951827E-317;
BA_ "GenMsgCycleTime" BO_ 2566849534 100;
BA_ "GenMsgSendType" BO_ 2566849534 8.52715012702708E-317;
BA_ "SingleFrame" BO_ 2583299838 0;
BA_ "GenMsgCycleTime" BO_ 2583299838 1000;
BA_ "GenMsgSendType" BO_ 2583299838 8.52558097453588E-317;
BA_ "SingleFrame" BO_ 2583168510 0;
BA_ "GenMsgCycleTime" BO_ 2583168510 100;
BA_ "GenMsgSendType" BO_ 2583168510 8.52390115134002E-317;
BA_ "GenMsgCycleTime" BO_ 2314732030 100;
BA_ "GenMsgSendType" BO_ 2314732030 8.51951780093012E-317;
BA_ "GenMsgCycleTime" BO_ 2563178238 100;
BA_ "GenMsgSendType" BO_ 2563178238 8.48652212083826E-317;
BA_ "GenMsgCycleTime" BO_ 2563112702 100;
BA_ "GenMsgSendType" BO_ 2563112702 8.48555770469758E-317;
BA_ "GenMsgCycleTime" BO_ 2563047166 1000;
BA_ "GenMsgSendType" BO_ 2563047166 8.48466048148473E-317;
BA_ "GenMsgCycleTime" BO_ 2360213246 100;
BA_ "GenMsgSendType" BO_ 2360213246 8.48390950170305E-317;
BA_ "GenMsgCycleTime" BO_ 2360147710 100;
BA_ "GenMsgSendType" BO_ 2360147710 8.48332452797837E-317;
BA_ "SigType" SG_ 2365463294 Valve10ExtendedPortEstimatedFlow 1;
BA_ "SPN" SG_ 2365463294 Valve10ExtendedPortEstimatedFlow 2277;
BA_ "SigType" SG_ 2365463294 Valve10RetractPortEstimatedFlow 1;
BA_ "SPN" SG_ 2365463294 Valve10RetractPortEstimatedFlow 2278;
BA_ "SPN" SG_ 2365463294 Valve10ValveState 2279;
BA_ "SigType" SG_ 2365463294 Valve10FailSafeMode 4;
BA_ "SPN" SG_ 2365463294 Valve10FailSafeMode 2286;
BA_ "SPN" SG_ 2365463294 Valve10LimitStatus 5181;
BA_ "SigType" SG_ 2365463550 Valve11ExtendedPortEstimatedFlow 1;
BA_ "SPN" SG_ 2365463550 Valve11ExtendedPortEstimatedFlow 2289;
BA_ "SigType" SG_ 2365463550 Valve11RetractPortEstimatedFlow 1;
BA_ "SPN" SG_ 2365463550 Valve11RetractPortEstimatedFlow 2290;
BA_ "SPN" SG_ 2365463550 Valve11ValveState 2291;
BA_ "SigType" SG_ 2365463550 Valve11FailSafeMode 4;
BA_ "SPN" SG_ 2365463550 Valve11FailSafeMode 2298;
BA_ "SPN" SG_ 2365463550 Valve11LimitStatus 5183;
BA_ "SigType" SG_ 2365463806 Valve12ExtendedPortEstimatedFlow 1;
BA_ "SPN" SG_ 2365463806 Valve12ExtendedPortEstimatedFlow 2301;
BA_ "SigType" SG_ 2365463806 Valve12RetractPortEstimatedFlow 1;
BA_ "SPN" SG_ 2365463806 Valve12RetractPortEstimatedFlow 2302;
BA_ "SPN" SG_ 2365463806 Valve12ValveState 2303;
BA_ "SigType" SG_ 2365463806 Valve12FailSafeMode 4;
BA_ "SPN" SG_ 2365463806 Valve12FailSafeMode 2310;
BA_ "SPN" SG_ 2365463806 Valve12LimitStatus 5185;
BA_ "SigType" SG_ 2365464062 Valve13ExtendedPortEstimatedFlow 1;
BA_ "SPN" SG_ 2365464062 Valve13ExtendedPortEstimatedFlow 2313;
BA_ "SigType" SG_ 2365464062 Valve13RetractPortEstimatedFlow 1;
BA_ "SPN" SG_ 2365464062 Valve13RetractPortEstimatedFlow 2314;
BA_ "SPN" SG_ 2365464062 Valve13ValveState 2315;
BA_ "SigType" SG_ 2365464062 Valve13FailSafeMode 4;
BA_ "SPN" SG_ 2365464062 Valve13FailSafeMode 2322;
BA_ "SPN" SG_ 2365464062 Valve13LimitStatus 5187;
BA_ "SigType" SG_ 2365464318 Valve14ExtendedPortEstimatedFlow 1;
BA_ "SPN" SG_ 2365464318 Valve14ExtendedPortEstimatedFlow 2325;
BA_ "SigType" SG_ 2365464318 Valve14RetractPortEstimatedFlow 1;
BA_ "SPN" SG_ 2365464318 Valve14RetractPortEstimatedFlow 2326;
BA_ "SPN" SG_ 2365464318 Valve14ValveState 2327;
BA_ "SigType" SG_ 2365464318 Valve14FailSafeMode 4;
BA_ "SPN" SG_ 2365464318 Valve14FailSafeMode 2334;
BA_ "SPN" SG_ 2365464318 Valve14LimitStatus 5189;
BA_ "SigType" SG_ 2365464574 Valve15ExtendedPortEstimatedFlow 1;
BA_ "SPN" SG_ 2365464574 Valve15ExtendedPortEstimatedFlow 2337;
BA_ "SigType" SG_ 2365464574 Valve15RetractPortEstimatedFlow 1;
BA_ "SPN" SG_ 2365464574 Valve15RetractPortEstimatedFlow 2338;
BA_ "SPN" SG_ 2365464574 Valve15ValveState 2339;
BA_ "SigType" SG_ 2365464574 Valve15FailSafeMode 4;
BA_ "SPN" SG_ 2365464574 Valve15FailSafeMode 2346;
BA_ "SPN" SG_ 2365464574 Valve15LimitStatus 5191;
BA_ "SPN" SG_ 2365464830 Valve0ExtendedPortMeasuredFlow 1899;
BA_ "SigType" SG_ 2365464830 Valve0ExtendedPortMeasuredFlow 1;
BA_ "SPN" SG_ 2365464830 Valve0RetractPortMeasuredFlow 1900;
BA_ "SigType" SG_ 2365464830 Valve0RetractPortMeasuredFlow 1;
BA_ "SigType" SG_ 2365464830 Valve0ExtendedPortPressure 1;
BA_ "SPN" SG_ 2365464830 Valve0ExtendedPortPressure 1904;
BA_ "SigType" SG_ 2365464830 Valve0RetractPortPressure 1;
BA_ "SPN" SG_ 2365464830 Valve0RetractPortPressure 1905;
BA_ "SigType" SG_ 2365464830 Valve0ReturnPortPressure 1;
BA_ "SPN" SG_ 2365464830 Valve0ReturnPortPressure 1906;
BA_ "SPN" SG_ 2365464830 Valve0LimitStatus 5160;
BA_ "SigType" SG_ 2365465086 Valve1ExtendedPortMeasuredFlow 1;
BA_ "SPN" SG_ 2365465086 Valve1ExtendedPortMeasuredFlow 1911;
BA_ "SigType" SG_ 2365465086 Valve1RetractPortMeasuredFlow 1;
BA_ "SPN" SG_ 2365465086 Valve1RetractPortMeasuredFlow 1912;
BA_ "SigType" SG_ 2365465086 Valve1ExtendedPortPressure 1;
BA_ "SPN" SG_ 2365465086 Valve1ExtendedPortPressure 1916;
BA_ "SigType" SG_ 2365465086 Valve1RetractPortPressure 1;
BA_ "SPN" SG_ 2365465086 Valve1RetractPortPressure 1917;
BA_ "SigType" SG_ 2365465086 Valve1ReturnPortPressure 1;
BA_ "SPN" SG_ 2365465086 Valve1ReturnPortPressure 1918;
BA_ "SPN" SG_ 2365465086 Valve1LimitStatus 5162;
BA_ "SigType" SG_ 2365465342 Valve2ExtendedPortMeasuredFlow 1;
BA_ "SPN" SG_ 2365465342 Valve2ExtendedPortMeasuredFlow 1923;
BA_ "SigType" SG_ 2365465342 Valve2RetractPortMeasuredFlow 1;
BA_ "SPN" SG_ 2365465342 Valve2RetractPortMeasuredFlow 1924;
BA_ "SigType" SG_ 2365465342 Valve2ExtendedPortPressure 1;
BA_ "SPN" SG_ 2365465342 Valve2ExtendedPortPressure 1928;
BA_ "SigType" SG_ 2365465342 Valve2RetractPortPressure 1;
BA_ "SPN" SG_ 2365465342 Valve2RetractPortPressure 1929;
BA_ "SigType" SG_ 2365465342 Valve2ReturnPortPressure 1;
BA_ "SPN" SG_ 2365465342 Valve2ReturnPortPressure 1930;
BA_ "SPN" SG_ 2365465342 Valve2LimitStatus 5164;
BA_ "SigType" SG_ 2365465598 Valve3ExtendedPortMeasuredFlow 1;
BA_ "SPN" SG_ 2365465598 Valve3ExtendedPortMeasuredFlow 1935;
BA_ "SigType" SG_ 2365465598 Valve3RetractPortMeasuredFlow 1;
BA_ "SPN" SG_ 2365465598 Valve3RetractPortMeasuredFlow 1936;
BA_ "SigType" SG_ 2365465598 Valve3ExtendedPortPressure 1;
BA_ "SPN" SG_ 2365465598 Valve3ExtendedPortPressure 1940;
BA_ "SigType" SG_ 2365465598 Valve3RetractPortPressure 1;
BA_ "SPN" SG_ 2365465598 Valve3RetractPortPressure 1941;
BA_ "SigType" SG_ 2365465598 Valve3ReturnPortPressure 1;
BA_ "SPN" SG_ 2365465598 Valve3ReturnPortPressure 1942;
BA_ "SPN" SG_ 2365465598 Valve3LimitStatus 5166;
BA_ "SigType" SG_ 2365465854 Valve4ExtendedPortMeasuredFlow 1;
BA_ "SPN" SG_ 2365465854 Valve4ExtendedPortMeasuredFlow 1947;
BA_ "SigType" SG_ 2365465854 Valve4RetractPortMeasuredFlow 1;
BA_ "SPN" SG_ 2365465854 Valve4RetractPortMeasuredFlow 1948;
BA_ "SigType" SG_ 2365465854 Valve4ExtendedPortPressure 1;
BA_ "SPN" SG_ 2365465854 Valve4ExtendedPortPressure 1952;
BA_ "SigType" SG_ 2365465854 Valve4RetractPortPressure 1;
BA_ "SPN" SG_ 2365465854 Valve4RetractPortPressure 1953;
BA_ "SigType" SG_ 2365465854 Valve4ReturnPortPressure 1;
BA_ "SPN" SG_ 2365465854 Valve4ReturnPortPressure 1954;
BA_ "SPN" SG_ 2365465854 Valve4LimitStatus 5168;
BA_ "SigType" SG_ 2365466110 Valve5ExtendedPortMeasuredFlow 1;
BA_ "SPN" SG_ 2365466110 Valve5ExtendedPortMeasuredFlow 1959;
BA_ "SigType" SG_ 2365466110 Valve5RetractPortMeasuredFlow 1;
BA_ "SPN" SG_ 2365466110 Valve5RetractPortMeasuredFlow 1960;
BA_ "SigType" SG_ 2365466110 Valve5ExtendedPortPressure 1;
BA_ "SPN" SG_ 2365466110 Valve5ExtendedPortPressure 1964;
BA_ "SigType" SG_ 2365466110 Valve5RetractPortPressure 1;
BA_ "SPN" SG_ 2365466110 Valve5RetractPortPressure 1965;
BA_ "SigType" SG_ 2365466110 Valve5ReturnPortPressure 1;
BA_ "SPN" SG_ 2365466110 Valve5ReturnPortPressure 1966;
BA_ "SPN" SG_ 2365466110 Valve5LimitStatus 5170;
BA_ "SigType" SG_ 2365466366 Valve6ExtendedPortMeasuredFlow 1;
BA_ "SPN" SG_ 2365466366 Valve6ExtendedPortMeasuredFlow 1971;
BA_ "SigType" SG_ 2365466366 Valve6RetractPortMeasuredFlow 1;
BA_ "SPN" SG_ 2365466366 Valve6RetractPortMeasuredFlow 1972;
BA_ "SigType" SG_ 2365466366 Valve6ExtendedPortPressure 1;
BA_ "SPN" SG_ 2365466366 Valve6ExtendedPortPressure 1976;
BA_ "SigType" SG_ 2365466366 Valve6RetractPortPressure 1;
BA_ "SPN" SG_ 2365466366 Valve6RetractPortPressure 1977;
BA_ "SigType" SG_ 2365466366 Valve6ReturnPortPressure 1;
BA_ "SPN" SG_ 2365466366 Valve6ReturnPortPressure 1978;
BA_ "SPN" SG_ 2365466366 Valve6LimitStatus 5172;
BA_ "SigType" SG_ 2365466622 Valve7ExtendedPortMeasuredFlow 1;
BA_ "SPN" SG_ 2365466622 Valve7ExtendedPortMeasuredFlow 1983;
BA_ "SigType" SG_ 2365466622 Valve7RetractPortMeasuredFlow 1;
BA_ "SPN" SG_ 2365466622 Valve7RetractPortMeasuredFlow 1984;
BA_ "SigType" SG_ 2365466622 Valve7ExtendedPortPressure 1;
BA_ "SPN" SG_ 2365466622 Valve7ExtendedPortPressure 1988;
BA_ "SigType" SG_ 2365466622 Valve7RetractPortPressure 1;
BA_ "SPN" SG_ 2365466622 Valve7RetractPortPressure 1989;
BA_ "SigType" SG_ 2365466622 Valve7ReturnPortPressure 1;
BA_ "SPN" SG_ 2365466622 Valve7ReturnPortPressure 1990;
BA_ "SPN" SG_ 2365466622 Valve7LimitStatus 5174;
BA_ "SigType" SG_ 2365466878 Valve8ExtendedPortMeasuredFlow 1;
BA_ "SPN" SG_ 2365466878 Valve8ExtendedPortMeasuredFlow 1995;
BA_ "SigType" SG_ 2365466878 Valve8RetractPortMeasuredFlow 1;
BA_ "SPN" SG_ 2365466878 Valve8RetractPortMeasuredFlow 1996;
BA_ "SigType" SG_ 2365466878 Valve8ExtendedPortPressure 1;
BA_ "SPN" SG_ 2365466878 Valve8ExtendedPortPressure 2256;
BA_ "SigType" SG_ 2365466878 Valve8RetractPortPressure 1;
BA_ "SPN" SG_ 2365466878 Valve8RetractPortPressure 2257;
BA_ "SigType" SG_ 2365466878 Valve8ReturnPortPressure 1;
BA_ "SPN" SG_ 2365466878 Valve8ReturnPortPressure 2258;
BA_ "SPN" SG_ 2365466878 Valve8LimitStatus 5176;
BA_ "SigType" SG_ 2365467134 Valve9ExtendedPortMeasuredFlow 1;
BA_ "SPN" SG_ 2365467134 Valve9ExtendedPortMeasuredFlow 2263;
BA_ "SigType" SG_ 2365467134 Valve9RetractPortMeasuredFlow 1;
BA_ "SPN" SG_ 2365467134 Valve9RetractPortMeasuredFlow 2264;
BA_ "SigType" SG_ 2365467134 Valve9ExtendedPortPressure 1;
BA_ "SPN" SG_ 2365467134 Valve9ExtendedPortPressure 2268;
BA_ "SigType" SG_ 2365467134 Valve9RetractPortPressure 1;
BA_ "SPN" SG_ 2365467134 Valve9RetractPortPressure 2269;
BA_ "SigType" SG_ 2365467134 Valve9ReturnPortPressure 1;
BA_ "SPN" SG_ 2365467134 Valve9ReturnPortPressure 2270;
BA_ "SPN" SG_ 2365467134 Valve9LimitStatus 5178;
BA_ "SigType" SG_ 2365467390 Valve10ExtendedPortMeasuredFlow 1;
BA_ "SPN" SG_ 2365467390 Valve10ExtendedPortMeasuredFlow 2275;
BA_ "SigType" SG_ 2365467390 Valve10RetractPortMeasuredFlow 1;
BA_ "SPN" SG_ 2365467390 Valve10RetractPortMeasuredFlow 2276;
BA_ "SigType" SG_ 2365467390 Valve10ExtendedPortPressure 1;
BA_ "SPN" SG_ 2365467390 Valve10ExtendedPortPressure 2280;
BA_ "SigType" SG_ 2365467390 Valve10RetractPortPressure 1;
BA_ "SPN" SG_ 2365467390 Valve10RetractPortPressure 2281;
BA_ "SigType" SG_ 2365467390 Valve10ReturnPortPressure 1;
BA_ "SPN" SG_ 2365467390 Valve10ReturnPortPressure 2282;
BA_ "SPN" SG_ 2365467390 Valve10LimitStatus 5180;
BA_ "SigType" SG_ 2365467646 Valve11ExtendedPortMeasuredFlow 1;
BA_ "SPN" SG_ 2365467646 Valve11ExtendedPortMeasuredFlow 2287;
BA_ "SigType" SG_ 2365467646 Valve11RetractPortMeasuredFlow 1;
BA_ "SPN" SG_ 2365467646 Valve11RetractPortMeasuredFlow 2288;
BA_ "SigType" SG_ 2365467646 Valve11ExtendedPortPressure 1;
BA_ "SPN" SG_ 2365467646 Valve11ExtendedPortPressure 2292;
BA_ "SigType" SG_ 2365467646 Valve11RetractPortPressure 1;
BA_ "SPN" SG_ 2365467646 Valve11RetractPortPressure 2293;
BA_ "SigType" SG_ 2365467646 Valve11ReturnPortPressure 1;
BA_ "SPN" SG_ 2365467646 Valve11ReturnPortPressure 2294;
BA_ "SPN" SG_ 2365467646 Valve11LimitStatus 5182;
BA_ "SigType" SG_ 2365467902 Valve12ExtendedPortMeasuredFlow 1;
BA_ "SPN" SG_ 2365467902 Valve12ExtendedPortMeasuredFlow 2299;
BA_ "SigType" SG_ 2365467902 Valve12RetractPortMeasuredFlow 1;
BA_ "SPN" SG_ 2365467902 Valve12RetractPortMeasuredFlow 2300;
BA_ "SigType" SG_ 2365467902 Valve12ExtendedPortPressure 1;
BA_ "SPN" SG_ 2365467902 Valve12ExtendedPortPressure 2304;
BA_ "SigType" SG_ 2365467902 Valve12RetractPortPressure 1;
BA_ "SPN" SG_ 2365467902 Valve12RetractPortPressure 2305;
BA_ "SigType" SG_ 2365467902 Valve12ReturnPortPressure 1;
BA_ "SPN" SG_ 2365467902 Valve12ReturnPortPressure 2306;
BA_ "SPN" SG_ 2365467902 Valve12LimitStatus 5184;
BA_ "SigType" SG_ 2365468158 Valve13ExtendedPortMeasuredFlow 1;
BA_ "SPN" SG_ 2365468158 Valve13ExtendedPortMeasuredFlow 2311;
BA_ "SigType" SG_ 2365468158 Valve13RetractPortMeasuredFlow 1;
BA_ "SPN" SG_ 2365468158 Valve13RetractPortMeasuredFlow 2312;
BA_ "SigType" SG_ 2365468158 Valve13ExtendedPortPressure 1;
BA_ "SPN" SG_ 2365468158 Valve13ExtendedPortPressure 2316;
BA_ "SigType" SG_ 2365468158 Valve13RetractPortPressure 1;
BA_ "SPN" SG_ 2365468158 Valve13RetractPortPressure 2317;
BA_ "SigType" SG_ 2365468158 Valve13ReturnPortPressure 1;
BA_ "SPN" SG_ 2365468158 Valve13ReturnPortPressure 2318;
BA_ "SPN" SG_ 2365468158 Valve13LimitStatus 5186;
BA_ "SigType" SG_ 2365468414 Valve14ExtendedPortMeasuredFlow 1;
BA_ "SPN" SG_ 2365468414 Valve14ExtendedPortMeasuredFlow 2323;
BA_ "SigType" SG_ 2365468414 Valve14RetractPortMeasuredFlow 1;
BA_ "SPN" SG_ 2365468414 Valve14RetractPortMeasuredFlow 2324;
BA_ "SigType" SG_ 2365468414 Valve14ExtendedPortPressure 1;
BA_ "SPN" SG_ 2365468414 Valve14ExtendedPortPressure 2328;
BA_ "SigType" SG_ 2365468414 Valve14RetractPortPressure 1;
BA_ "SPN" SG_ 2365468414 Valve14RetractPortPressure 2329;
BA_ "SigType" SG_ 2365468414 Valve14ReturnPortPressure 1;
BA_ "SPN" SG_ 2365468414 Valve14ReturnPortPressure 2330;
BA_ "SPN" SG_ 2365468414 Valve14LimitStatus 5188;
BA_ "SigType" SG_ 2365468670 Valve15ExtendedPortMeasuredFlow 1;
BA_ "SPN" SG_ 2365468670 Valve15ExtendedPortMeasuredFlow 2335;
BA_ "SigType" SG_ 2365468670 Valve15RetractPortMeasuredFlow 1;
BA_ "SPN" SG_ 2365468670 Valve15RetractPortMeasuredFlow 2336;
BA_ "SigType" SG_ 2365468670 Valve15ExtendedPortPressure 1;
BA_ "SPN" SG_ 2365468670 Valve15ExtendedPortPressure 2340;
BA_ "SigType" SG_ 2365468670 Valve15RetractPortPressure 1;
BA_ "SPN" SG_ 2365468670 Valve15RetractPortPressure 2341;
BA_ "SigType" SG_ 2365468670 Valve15ReturnPortPressure 1;
BA_ "SPN" SG_ 2365468670 Valve15ReturnPortPressure 2342;
BA_ "SPN" SG_ 2365468670 Valve15LimitStatus 5190;
BA_ "SigType" SG_ 2365468926 Valve0PortFlowCmd 1;
BA_ "SPN" SG_ 2365468926 Valve0PortFlowCmd 1907;
BA_ "SPN" SG_ 2365468926 Valve0StateCmd 1908;
BA_ "SigType" SG_ 2365468926 Valve0FailSaveModeCmd 4;
BA_ "SPN" SG_ 2365468926 Valve0FailSaveModeCmd 1909;
BA_ "SigType" SG_ 2365469182 Valve1PortFlowCmd 1;
BA_ "SPN" SG_ 2365469182 Valve1PortFlowCmd 1919;
BA_ "SPN" SG_ 2365469182 Valve1StateCmd 1920;
BA_ "SigType" SG_ 2365469182 Valve1FailSaveModeCmd 4;
BA_ "SigType" SG_ 2365469438 Valve2PortFlowCmd 1;
BA_ "SPN" SG_ 2365469438 Valve2PortFlowCmd 1931;
BA_ "SPN" SG_ 2365469438 Valve2StateCmd 1932;
BA_ "SigType" SG_ 2365469438 Valve2FailSaveModeCmd 4;
BA_ "SPN" SG_ 2365469438 Valve2FailSaveModeCmd 1933;
BA_ "SigType" SG_ 2365469694 Valve3PortFlowCmd 1;
BA_ "SPN" SG_ 2365469694 Valve3PortFlowCmd 1943;
BA_ "SPN" SG_ 2365469694 Valve3StateCmd 1944;
BA_ "SigType" SG_ 2365469694 Valve3FailSaveModeCmd 4;
BA_ "SPN" SG_ 2365469694 Valve3FailSaveModeCmd 1945;
BA_ "SigType" SG_ 2365469950 Valve4PortFlowCmd 1;
BA_ "SPN" SG_ 2365469950 Valve4PortFlowCmd 1955;
BA_ "SPN" SG_ 2365469950 Valve4StateCmd 1956;
BA_ "SigType" SG_ 2365469950 Valve4FailSaveModeCmd 4;
BA_ "SPN" SG_ 2365469950 Valve4FailSaveModeCmd 1957;
BA_ "SigType" SG_ 2365470206 Valve5PortFlowCmd 1;
BA_ "SPN" SG_ 2365470206 Valve5PortFlowCmd 1967;
BA_ "SPN" SG_ 2365470206 Valve5StateCmd 1968;
BA_ "SigType" SG_ 2365470206 Valve5FailSaveModeCmd 4;
BA_ "SPN" SG_ 2365470206 Valve5FailSaveModeCmd 1969;
BA_ "SigType" SG_ 2365470462 Valve6PortFlowCmd 1;
BA_ "SPN" SG_ 2365470462 Valve6PortFlowCmd 1979;
BA_ "SPN" SG_ 2365470462 Valve6StateCmd 1980;
BA_ "SigType" SG_ 2365470462 Valve6FailSaveModeCmd 4;
BA_ "SPN" SG_ 2365470462 Valve6FailSaveModeCmd 1981;
BA_ "SigType" SG_ 2365470718 Valve7PortFlowCmd 1;
BA_ "SPN" SG_ 2365470718 Valve7PortFlowCmd 1991;
BA_ "SPN" SG_ 2365470718 Valve7StateCmd 1992;
BA_ "SigType" SG_ 2365470718 Valve7FailSaveModeCmd 4;
BA_ "SPN" SG_ 2365470718 Valve7FailSaveModeCmd 1993;
BA_ "SigType" SG_ 2365470974 Valve8PortFlowCmd 1;
BA_ "SPN" SG_ 2365470974 Valve8PortFlowCmd 2259;
BA_ "SPN" SG_ 2365470974 Valve8StateCmd 2260;
BA_ "SigType" SG_ 2365470974 Valve8FailSaveModeCmd 4;
BA_ "SPN" SG_ 2365470974 Valve8FailSaveModeCmd 2261;
BA_ "SigType" SG_ 2365471230 Valve9PortFlowCmd 1;
BA_ "SPN" SG_ 2365471230 Valve9PortFlowCmd 2271;
BA_ "SPN" SG_ 2365471230 Valve9StateCmd 2272;
BA_ "SigType" SG_ 2365471230 Valve9FailSaveModeCmd 4;
BA_ "SPN" SG_ 2365471230 Valve9FailSaveModeCmd 2273;
BA_ "SigType" SG_ 2365471486 Valve10PortFlowCmd 1;
BA_ "SPN" SG_ 2365471486 Valve10PortFlowCmd 2283;
BA_ "SPN" SG_ 2365471486 Valve10StateCmd 2284;
BA_ "SigType" SG_ 2365471486 Valve10FailSaveModeCmd 4;
BA_ "SPN" SG_ 2365471486 Valve10FailSaveModeCmd 2285;
BA_ "SigType" SG_ 2365471742 Valve11PortFlowCmd 1;
BA_ "SPN" SG_ 2365471742 Valve11PortFlowCmd 2295;
BA_ "SPN" SG_ 2365471742 Valve11StateCmd 2296;
BA_ "SigType" SG_ 2365471742 Valve11FailSaveModeCmd 4;
BA_ "SPN" SG_ 2365471742 Valve11FailSaveModeCmd 2297;
BA_ "SigType" SG_ 2365471998 Valve12PortFlowCmd 1;
BA_ "SPN" SG_ 2365471998 Valve12PortFlowCmd 2307;
BA_ "SPN" SG_ 2365471998 Valve12StateCmd 2308;
BA_ "SigType" SG_ 2365471998 Valve12FailSaveModeCmd 4;
BA_ "SPN" SG_ 2365471998 Valve12FailSaveModeCmd 2309;
BA_ "SigType" SG_ 2365472254 Valve13PortFlowCmd 1;
BA_ "SPN" SG_ 2365472254 Valve13PortFlowCmd 2319;
BA_ "SPN" SG_ 2365472254 Valve13StateCmd 2320;
BA_ "SigType" SG_ 2365472254 Valve13FailSaveModeCmd 4;
BA_ "SPN" SG_ 2365472254 Valve13FailSaveModeCmd 2321;
BA_ "SigType" SG_ 2365472510 Valve14PortFlowCmd 1;
BA_ "SPN" SG_ 2365472510 Valve14PortFlowCmd 2331;
BA_ "SPN" SG_ 2365472510 Valve14StateCmd 2332;
BA_ "SigType" SG_ 2365472510 Valve14FailSaveModeCmd 4;
BA_ "SPN" SG_ 2365472510 Valve14FailSaveModeCmd 2333;
BA_ "SigType" SG_ 2365472766 Valve15PortFlowCmd 1;
BA_ "SPN" SG_ 2365472766 Valve15PortFlowCmd 2343;
BA_ "SPN" SG_ 2365472766 Valve15StateCmd 2344;
BA_ "SigType" SG_ 2365472766 Valve15FailSaveModeCmd 4;
BA_ "SPN" SG_ 2365472766 Valve15FailSaveModeCmd 2345;
BA_ "SigType" SG_ 2566799614 DaytimeRunningLightData 4;
BA_ "SPN" SG_ 2566799614 DaytimeRunningLightData 2404;
BA_ "SigType" SG_ 2566799614 AlternateHeadLightData 4;
BA_ "SPN" SG_ 2566799614 AlternateHeadLightData 2352;
BA_ "SigType" SG_ 2566799614 LowBeamHeadLightData 4;
BA_ "SPN" SG_ 2566799614 LowBeamHeadLightData 2350;
BA_ "SigType" SG_ 2566799614 HighBeamHeadLightData 4;
BA_ "SPN" SG_ 2566799614 HighBeamHeadLightData 2348;
BA_ "SigType" SG_ 2566799614 TractorFrontFogLightData 4;
BA_ "SPN" SG_ 2566799614 TractorFrontFogLightData 2388;
BA_ "SigType" SG_ 2566799614 RotationBeaconLightData 4;
BA_ "SPN" SG_ 2566799614 RotationBeaconLightData 2386;
BA_ "SigType" SG_ 2566799614 RightTurnSignalLightData 4;
BA_ "SPN" SG_ 2566799614 RightTurnSignalLightData 2370;
BA_ "SigType" SG_ 2566799614 LeftTurnSignalLightData 4;
BA_ "SPN" SG_ 2566799614 LeftTurnSignalLightData 2368;
BA_ "SigType" SG_ 2566799614 BackUpLightAndAlarmHornData 4;
BA_ "SPN" SG_ 2566799614 BackUpLightAndAlarmHornData 2392;
BA_ "SigType" SG_ 2566799614 CentreStopLightData 4;
BA_ "SPN" SG_ 2566799614 CentreStopLightData 2376;
BA_ "SigType" SG_ 2566799614 RightStopLightData 4;
BA_ "SPN" SG_ 2566799614 RightStopLightData 2374;
BA_ "SigType" SG_ 2566799614 LefttStopLightData 4;
BA_ "SPN" SG_ 2566799614 LefttStopLightData 2372;
BA_ "SigType" SG_ 2566799614 ImplementClearanceLightData 4;
BA_ "SPN" SG_ 2566799614 ImplementClearanceLightData 2384;
BA_ "SigType" SG_ 2566799614 TractorClearanceLightData 4;
BA_ "SPN" SG_ 2566799614 TractorClearanceLightData 2382;
BA_ "SigType" SG_ 2566799614 ImplementMarkerLightData 4;
BA_ "SPN" SG_ 2566799614 ImplementMarkerLightData 2380;
BA_ "SigType" SG_ 2566799614 TractorMarkerLightData 4;
BA_ "SPN" SG_ 2566799614 TractorMarkerLightData 2378;
BA_ "SigType" SG_ 2566799614 RearFogLightData 4;
BA_ "SPN" SG_ 2566799614 RearFogLightData 2390;
BA_ "SigType" SG_ 2566799614 TractorUndersideWorkLightData 4;
BA_ "SPN" SG_ 2566799614 TractorUndersideWorkLightData 2358;
BA_ "SigType" SG_ 2566799614 TractorRearLowWorkLightData 4;
BA_ "SPN" SG_ 2566799614 TractorRearLowWorkLightData 2360;
BA_ "SigType" SG_ 2566799614 TractorRearHighWorkLightData 4;
BA_ "SPN" SG_ 2566799614 TractorRearHighWorkLightData 2362;
BA_ "SigType" SG_ 2566799614 TractorSideLowWorkLightData 4;
BA_ "SPN" SG_ 2566799614 TractorSideLowWorkLightData 2364;
BA_ "SigType" SG_ 2566799614 TractorSideHighWorkLightData 4;
BA_ "SPN" SG_ 2566799614 TractorSideHighWorkLightData 2366;
BA_ "SigType" SG_ 2566799614 TractorFrontLowWorkLightData 4;
BA_ "SPN" SG_ 2566799614 TractorFrontLowWorkLightData 2354;
BA_ "SigType" SG_ 2566799614 TractorFrontHighWorkLightData 4;
BA_ "SPN" SG_ 2566799614 TractorFrontHighWorkLightData 2356;
BA_ "SigType" SG_ 2566799614 ImplementOEMOption2LightData 4;
BA_ "SPN" SG_ 2566799614 ImplementOEMOption2LightData 2398;
BA_ "SigType" SG_ 2566799614 ImplementOEMOption1LightData 4;
BA_ "SPN" SG_ 2566799614 ImplementOEMOption1LightData 2396;
BA_ "SigType" SG_ 2566799614 ImplementRightForwardLightData 4;
BA_ "SPN" SG_ 2566799614 ImplementRightForwardLightData 2407;
BA_ "SigType" SG_ 2566799614 ImplementLeftForwardLightData 4;
BA_ "SPN" SG_ 2566799614 ImplementLeftForwardLightData 2598;
BA_ "SigType" SG_ 2566799614 ImplRightFacingWorkLightData 4;
BA_ "SPN" SG_ 2566799614 ImplRightFacingWorkLightData 2402;
BA_ "SigType" SG_ 2566799614 ImplLeftFacingWorkLightData 4;
BA_ "SPN" SG_ 2566799614 ImplLeftFacingWorkLightData 2400;
BA_ "SigType" SG_ 2566799614 ImplementRearWorkLightData 4;
BA_ "SPN" SG_ 2566799614 ImplementRearWorkLightData 2394;
BA_ "SigType" SG_ 2365473278 DaytimeRunningLightCmd 4;
BA_ "SPN" SG_ 2365473278 DaytimeRunningLightCmd 2403;
BA_ "SigType" SG_ 2365473278 AlternateHeadLightCmd 4;
BA_ "SPN" SG_ 2365473278 AlternateHeadLightCmd 2351;
BA_ "SigType" SG_ 2365473278 LowBeamHeadLightCmd 4;
BA_ "SPN" SG_ 2365473278 LowBeamHeadLightCmd 2349;
BA_ "SigType" SG_ 2365473278 HighBeamHeadLightCmd 4;
BA_ "SPN" SG_ 2365473278 HighBeamHeadLightCmd 2347;
BA_ "SigType" SG_ 2365473278 TractorFrontFogLightCmd 4;
BA_ "SPN" SG_ 2365473278 TractorFrontFogLightCmd 2387;
BA_ "SigType" SG_ 2365473278 RotatingBeaconLightCmd 4;
BA_ "SPN" SG_ 2365473278 RotatingBeaconLightCmd 2385;
BA_ "SigType" SG_ 2365473278 RightTurnSignalLightCmd 4;
BA_ "SPN" SG_ 2365473278 RightTurnSignalLightCmd 2369;
BA_ "SigType" SG_ 2365473278 LeftTurnSignalLightCmd 4;
BA_ "SPN" SG_ 2365473278 LeftTurnSignalLightCmd 2367;
BA_ "SigType" SG_ 2365473278 BackUpLightAndAlarmHornCmd 4;
BA_ "SPN" SG_ 2365473278 BackUpLightAndAlarmHornCmd 2391;
BA_ "SigType" SG_ 2365473278 CentreStopLightCmd 4;
BA_ "SPN" SG_ 2365473278 CentreStopLightCmd 2375;
BA_ "SigType" SG_ 2365473278 RightStopLightCmd 4;
BA_ "SPN" SG_ 2365473278 RightStopLightCmd 2373;
BA_ "SigType" SG_ 2365473278 LeftStopLightCmd 4;
BA_ "SPN" SG_ 2365473278 LeftStopLightCmd 2371;
BA_ "SigType" SG_ 2365473278 ImplementClearanceLightCmd 4;
BA_ "SPN" SG_ 2365473278 ImplementClearanceLightCmd 2383;
BA_ "SigType" SG_ 2365473278 TractorClearanceLightCmd 4;
BA_ "SPN" SG_ 2365473278 TractorClearanceLightCmd 2381;
BA_ "SigType" SG_ 2365473278 ImplementMarkerLightCmd 4;
BA_ "SPN" SG_ 2365473278 ImplementMarkerLightCmd 2379;
BA_ "SigType" SG_ 2365473278 TractorMarkerLightCmd 4;
BA_ "SPN" SG_ 2365473278 TractorMarkerLightCmd 2377;
BA_ "SigType" SG_ 2365473278 RearFogLightCmd 4;
BA_ "SPN" SG_ 2365473278 RearFogLightCmd 2389;
BA_ "SigType" SG_ 2365473278 TractorUndersideWorkLightCmd 4;
BA_ "SPN" SG_ 2365473278 TractorUndersideWorkLightCmd 2357;
BA_ "SigType" SG_ 2365473278 TractorRearLowWorkLightCmd 4;
BA_ "SPN" SG_ 2365473278 TractorRearLowWorkLightCmd 2359;
BA_ "SigType" SG_ 2365473278 TractorRearHighWorkLightCmd 4;
BA_ "SPN" SG_ 2365473278 TractorRearHighWorkLightCmd 2361;
BA_ "SigType" SG_ 2365473278 TractorSideLowWorkLightCmd 4;
BA_ "SPN" SG_ 2365473278 TractorSideLowWorkLightCmd 2363;
BA_ "SigType" SG_ 2365473278 TractorSideHighWorkLightCmd 4;
BA_ "SPN" SG_ 2365473278 TractorSideHighWorkLightCmd 2365;
BA_ "SigType" SG_ 2365473278 TractorFrontLowWorkLightCmd 4;
BA_ "SPN" SG_ 2365473278 TractorFrontLowWorkLightCmd 2353;
BA_ "SigType" SG_ 2365473278 TractorFrontHighWorkLightCmd 4;
BA_ "SPN" SG_ 2365473278 TractorFrontHighWorkLightCmd 2355;
BA_ "SigType" SG_ 2365473278 ImplementOEMOption2LightCmd 4;
BA_ "SPN" SG_ 2365473278 ImplementOEMOption2LightCmd 2397;
BA_ "SigType" SG_ 2365473278 ImplementOEMOption1LightCmd 4;
BA_ "SPN" SG_ 2365473278 ImplementOEMOption1LightCmd 2395;
BA_ "SigType" SG_ 2365473278 ImplementRightForwardLightCmd 4;
BA_ "SPN" SG_ 2365473278 ImplementRightForwardLightCmd 2406;
BA_ "SigType" SG_ 2365473278 ImplementLeftForwardLightCmd 4;
BA_ "SPN" SG_ 2365473278 ImplementLeftForwardLightCmd 2597;
BA_ "SigType" SG_ 2365473278 LightingDataRequestCmd 4;
BA_ "SPN" SG_ 2365473278 LightingDataRequestCmd 2393;
BA_ "SigType" SG_ 2365473278 ImplementRightFacingWorkLightCmd 4;
BA_ "SPN" SG_ 2365473278 ImplementRightFacingWorkLightCmd 2401;
BA_ "SigType" SG_ 2365473278 ImplementLeftFacingWorkLightCmd 4;
BA_ "SPN" SG_ 2365473278 ImplementLeftFacingWorkLightCmd 2399;
BA_ "SigType" SG_ 2365473278 ImplementRearWorkLightCmd 4;
BA_ "SPN" SG_ 2365473278 ImplementRearWorkLightCmd 2405;
BA_ "SPN" SG_ 2365473534 FrontHitchPositionCmd 1874;
BA_ "SigType" SG_ 2365473534 FrontHitchPositionCmd 1;
BA_ "SPN" SG_ 2365473534 RearHitchPositionCmd 1875;
BA_ "SigType" SG_ 2365473534 RearHitchPositionCmd 1;
BA_ "SPN" SG_ 2365473534 FrontPTOOutShaftSpeedSetPointCmd 1886;
BA_ "SigType" SG_ 2365473534 FrontPTOOutShaftSpeedSetPointCmd 1;
BA_ "SPN" SG_ 2365473534 RearPTOOutShaftSpeedSetPointCmd 1887;
BA_ "SigType" SG_ 2365473534 RearPTOOutShaftSpeedSetPointCmd 1;
BA_ "SPN" SG_ 2365473534 RearPTOEngagementCmd 1894;
BA_ "SigType" SG_ 2365473534 RearPTOEngagementCmd 4;
BA_ "SPN" SG_ 2365473534 FrontPTOEngagementCmd 1893;
BA_ "SigType" SG_ 2365473534 FrontPTOEngagementCmd 4;
BA_ "SPN" SG_ 2365473534 RearPTOEconomyModeCmd 1898;
BA_ "SigType" SG_ 2365473534 RearPTOEconomyModeCmd 4;
BA_ "SPN" SG_ 2365473534 FrontPTOEconomyModeCmd 1897;
BA_ "SigType" SG_ 2365473534 FrontPTOEconomyModeCmd 4;
BA_ "SPN" SG_ 2365473534 RearPTOModeCmd 1896;
BA_ "SigType" SG_ 2365473534 RearPTOModeCmd 4;
BA_ "SPN" SG_ 2365473534 FrontPTOModeCmd 1895;
BA_ "SigType" SG_ 2365473534 FrontPTOModeCmd 4;
BA_ "SPN" SG_ 2365473790 RearPTOOutputShaftSpeed 1883;
BA_ "SigType" SG_ 2365473790 RearPTOOutputShaftSpeed 1;
BA_ "SPN" SG_ 2365473790 RearPTOOutputShaftSpeedSetPoint 1885;
BA_ "SigType" SG_ 2365473790 RearPTOOutputShaftSpeedSetPoint 1;
BA_ "SPN" SG_ 2365473790 RearPTOEngagementRqStatus 5156;
BA_ "SigType" SG_ 2365473790 RearPTOEngagementRqStatus 4;
BA_ "SPN" SG_ 2365473790 RearPTOEconomyMode 1892;
BA_ "SigType" SG_ 2365473790 RearPTOEconomyMode 4;
BA_ "SPN" SG_ 2365473790 RearPTOMode 1890;
BA_ "SigType" SG_ 2365473790 RearPTOMode 4;
BA_ "SPN" SG_ 2365473790 RearPTOEngagement 2408;
BA_ "SigType" SG_ 2365473790 RearPTOEngagement 4;
BA_ "SPN" SG_ 2365473790 RearPTOShaftSpeedLimitStatus 5159;
BA_ "SPN" SG_ 2365473790 RearPTOEconomyModeRqStatus 5158;
BA_ "SigType" SG_ 2365473790 RearPTOEconomyModeRqStatus 4;
BA_ "SPN" SG_ 2365473790 RearPTOModeRqStatus 5157;
BA_ "SigType" SG_ 2365473790 RearPTOModeRqStatus 4;
BA_ "SPN" SG_ 2365474046 FrontPTOOutShaftSpeed 1882;
BA_ "SigType" SG_ 2365474046 FrontPTOOutShaftSpeed 1;
BA_ "SPN" SG_ 2365474046 FrontPTOOutShaftSpeedSetPoint 1884;
BA_ "SigType" SG_ 2365474046 FrontPTOOutShaftSpeedSetPoint 1;
BA_ "SPN" SG_ 2365474046 FrontPTOEngagementRqStatus 5152;
BA_ "SigType" SG_ 2365474046 FrontPTOEngagementRqStatus 4;
BA_ "SPN" SG_ 2365474046 FrontPTOEconomyMode 1891;
BA_ "SigType" SG_ 2365474046 FrontPTOEconomyMode 4;
BA_ "SPN" SG_ 2365474046 FrontPTOMode 1889;
BA_ "SigType" SG_ 2365474046 FrontPTOMode 4;
BA_ "SPN" SG_ 2365474046 FrontPTOEngagement 1888;
BA_ "SigType" SG_ 2365474046 FrontPTOEngagement 4;
BA_ "SPN" SG_ 2365474046 FrontPTOShaftSpeedLimitStatus 5155;
BA_ "SPN" SG_ 2365474046 FrontPTOEconomyModeRqStatus 5154;
BA_ "SigType" SG_ 2365474046 FrontPTOEconomyModeRqStatus 4;
BA_ "SPN" SG_ 2365474046 FrontPTOModeRqStatus 5153;
BA_ "SigType" SG_ 2365474046 FrontPTOModeRqStatus 4;
BA_ "SPN" SG_ 2365474302 RearHitchPosition 1873;
BA_ "SigType" SG_ 2365474302 RearHitchPosition 1;
BA_ "SPN" SG_ 2365474302 RearHitchPositionLimitStatus 5151;
BA_ "SPN" SG_ 2365474302 RearHitchInWorkIndication 1877;
BA_ "SigType" SG_ 2365474302 RearHitchInWorkIndication 4;
BA_ "SPN" SG_ 2365474302 RearNominalPowerLinkForce 1881;
BA_ "SigType" SG_ 2365474302 RearNominalPowerLinkForce 1;
BA_ "SPN" SG_ 2365474302 RearDraft 1879;
BA_ "SigType" SG_ 2365474302 RearDraft 1;
BA_ "SPN" SG_ 2365474558 FrontHitchPosition 1872;
BA_ "SigType" SG_ 2365474558 FrontHitchPosition 1;
BA_ "SPN" SG_ 2365474558 FrontHitchPositionLimitStatus 5150;
BA_ "SPN" SG_ 2365474558 FrontHitchInWorkIndication 1876;
BA_ "SigType" SG_ 2365474558 FrontHitchInWorkIndication 4;
BA_ "SPN" SG_ 2365474558 FrontNominalLowerLinkForce 1880;
BA_ "SigType" SG_ 2365474558 FrontNominalLowerLinkForce 1;
BA_ "SPN" SG_ 2365474558 FrontDraft 1878;
BA_ "SigType" SG_ 2365474558 FrontDraft 1;
BA_ "SPN" SG_ 2566801406 MaintainActuatorPower 1868;
BA_ "SigType" SG_ 2566801406 MaintainActuatorPower 4;
BA_ "SPN" SG_ 2566801406 MaintainECUPower 1867;
BA_ "SigType" SG_ 2566801406 MaintainECUPower 4;
BA_ "SPN" SG_ 2566801406 ImplementWorkState 1871;
BA_ "SigType" SG_ 2566801406 ImplementWorkState 4;
BA_ "SPN" SG_ 2566801406 ImplementParkState 1870;
BA_ "SigType" SG_ 2566801406 ImplementParkState 4;
BA_ "SPN" SG_ 2566801406 ImplementTransportState 1869;
BA_ "SigType" SG_ 2566801406 ImplementTransportState 4;
BA_ "SPN" SG_ 2365475070 WheelBasedMachineSpeed 1862;
BA_ "SigType" SG_ 2365475070 WheelBasedMachineSpeed 1;
BA_ "SPN" SG_ 2365475070 WheelBasedMachineDistance 1863;
BA_ "SigType" SG_ 2365475070 WheelBasedMachineDistance 1;
BA_ "SPN" SG_ 2365475070 MaxTimeOfTractorPower 1866;
BA_ "SigType" SG_ 2365475070 MaxTimeOfTractorPower 1;
BA_ "SPN" SG_ 2365475070 WheelBasedMachineDirection 1864;
BA_ "SigType" SG_ 2365475070 WheelBasedMachineDirection 4;
BA_ "SPN" SG_ 2365475070 KeySwitchState 1865;
BA_ "SigType" SG_ 2365475070 KeySwitchState 4;
BA_ "SPN" SG_ 2365475070 StartStopState 5203;
BA_ "SigType" SG_ 2365475070 StartStopState 4;
BA_ "SPN" SG_ 2365475070 OperatorDirectionReversed 5244;
BA_ "SigType" SG_ 2365475070 OperatorDirectionReversed 5;
BA_ "SPN" SG_ 2365475326 GroundBasedMachineSpeed 1859;
BA_ "SigType" SG_ 2365475326 GroundBasedMachineSpeed 1;
BA_ "SPN" SG_ 2365475326 GroundBasedMachineDistance 1860;
BA_ "SigType" SG_ 2365475326 GroundBasedMachineDistance 1;
BA_ "SPN" SG_ 2365475326 GroundBasedMachineDirection 1861;
BA_ "SigType" SG_ 2365475326 GroundBasedMachineDirection 4;
BA_ "SPN" SG_ 2566842110 Seconds 959;
BA_ "SigType" SG_ 2566842110 Seconds 1;
BA_ "SPN" SG_ 2566842110 Minutes 960;
BA_ "SigType" SG_ 2566842110 Minutes 1;
BA_ "SPN" SG_ 2566842110 Hours 961;
BA_ "SigType" SG_ 2566842110 Hours 1;
BA_ "SPN" SG_ 2566842110 Month 963;
BA_ "SigType" SG_ 2566842110 Month 1;
BA_ "SPN" SG_ 2566842110 Day 962;
BA_ "SigType" SG_ 2566842110 Day 1;
BA_ "SPN" SG_ 2566842110 Year 964;
BA_ "SigType" SG_ 2566842110 Year 1;
BA_ "SPN" SG_ 2566842110 LocalMinuteOffset 1601;
BA_ "SigType" SG_ 2566842110 LocalMinuteOffset 1;
BA_ "SPN" SG_ 2566842110 LocalHourOffset 1602;
BA_ "SigType" SG_ 2566842110 LocalHourOffset 1;
BA_ "SigType" SG_ 2566848766 ManufacturerSpecific1 1;
BA_ "SigType" SG_ 2566848766 ManufacturerSpecific2 1;
BA_ "SigType" SG_ 2566848766 ManufacturerSpecific3 1;
BA_ "SigType" SG_ 2566848766 ManufacturerSpecific4 1;
BA_ "SigType" SG_ 2566848766 ManufacturerSpecific5 1;
BA_ "SigType" SG_ 2566848766 ManufacturerSpecific6 1;
BA_ "SigType" SG_ 2566848766 ManufacturerSpecific7 1;
BA_ "SigType" SG_ 2566848766 ManufacturerSpecific8 1;
BA_ "SigType" SG_ 2566849022 ManufacturerSpecific1 1;
BA_ "SigType" SG_ 2566849022 ManufacturerSpecific2 1;
BA_ "SigType" SG_ 2566849022 ManufacturerSpecific3 1;
BA_ "SigType" SG_ 2566849022 ManufacturerSpecific4 1;
BA_ "SigType" SG_ 2566849022 ManufacturerSpecific5 1;
BA_ "SigType" SG_ 2566849022 ManufacturerSpecific6 1;
BA_ "SigType" SG_ 2566849022 ManufacturerSpecific7 1;
BA_ "SigType" SG_ 2566849022 ManufacturerSpecific8 1;
BA_ "SigType" SG_ 2566849278 ManufacturerSpecific1 1;
BA_ "SigType" SG_ 2566849278 ManufacturerSpecific2 1;
BA_ "SigType" SG_ 2566849278 ManufacturerSpecific3 1;
BA_ "SigType" SG_ 2566849278 ManufacturerSpecific4 1;
BA_ "SigType" SG_ 2566849278 ManufacturerSpecific5 1;
BA_ "SigType" SG_ 2566849278 ManufacturerSpecific6 1;
BA_ "SigType" SG_ 2566849278 ManufacturerSpecific7 1;
BA_ "SigType" SG_ 2566849278 ManufacturerSpecific8 1;
BA_ "SigType" SG_ 2566849534 ManufacturerSpecific1 1;
BA_ "SigType" SG_ 2566849534 ManufacturerSpecific2 1;
BA_ "SigType" SG_ 2566849534 ManufacturerSpecific3 1;
BA_ "SigType" SG_ 2566849534 ManufacturerSpecific4 1;
BA_ "SigType" SG_ 2566849534 ManufacturerSpecific5 1;
BA_ "SigType" SG_ 2566849534 ManufacturerSpecific6 1;
BA_ "SigType" SG_ 2566849534 ManufacturerSpecific7 1;
BA_ "SigType" SG_ 2566849534 ManufacturerSpecific8 1;
BA_ "SigType" SG_ 2583299838 SequenceID 1;
BA_ "SigType" SG_ 2583299838 RMSofPositionUncertainty 1;
BA_ "SigType" SG_ 2583299838 STDofMajorAxis 1;
BA_ "SigType" SG_ 2583299838 STDofMinorAxis 1;
BA_ "SigType" SG_ 2583299838 OrientationOfMinorAxis 1;
BA_ "SigType" SG_ 2583299838 STDofLatError 1;
BA_ "SigType" SG_ 2583299838 STDofLonError 1;
BA_ "SigType" SG_ 2583299838 STDofAltError 1;
BA_ "SigType" SG_ 2583168510 SequenceID 1;
BA_ "SigType" SG_ 2583168510 PositionDate 1;
BA_ "SigType" SG_ 2583168510 PositionTime 1;
BA_ "SigType" SG_ 2583168510 LatitudeLow 1;
BA_ "SigType" SG_ 2583168510 LongitudeLow 1;
BA_ "SigType" SG_ 2583168510 GNSSIntegrity 4;
BA_ "SigType" SG_ 2583168510 NumberOfSVs 1;
BA_ "SigType" SG_ 2583168510 HDOP 2;
BA_ "SigType" SG_ 2583168510 PDOP 2;
BA_ "SigType" SG_ 2583168510 GeoidalSeparation 2;
BA_ "SigType" SG_ 2583168510 NumberOfReferenceStations 1;
BA_ "SigType" SG_ 2583168510 ReferenceStationID1 1;
BA_ "SigType" SG_ 2583168510 AgeOfDGNSSCorrections1 1;
BA_ "SigType" SG_ 2563309310 ControlByte 1;
BA_ "GenSigStartValue" SG_ 2563309310 NumberOfBytesToTransfer 1786;
BA_ "SigType" SG_ 2563309310 NumberOfBytesToTransfer 1;
BA_ "GenSigStartValue" SG_ 2563309310 NumberOfPacketsToSend 1;
BA_ "SigType" SG_ 2563309310 NumberOfPacketsToSend 1;
BA_ "GenSigStartValue" SG_ 2563309310 NumberOfPacketsOffset 1;
BA_ "SigType" SG_ 2563309310 NumberOfPacketsOffset 1;
BA_ "GenSigStartValue" SG_ 2563309310 NumberOfBytesTransfered 1786;
BA_ "SigType" SG_ 2563309310 NumberOfBytesTransfered 1;
BA_ "GenSigStartValue" SG_ 2563309310 NextPacketNumberToSend 1;
BA_ "SigType" SG_ 2563309310 NextPacketNumberToSend 1;
BA_ "SigType" SG_ 2563309310 DataPacketOffset 1;
BA_ "SigType" SG_ 2563309310 PGNumber 6;
BA_ "GenSigStartValue" SG_ 2563243774 SequenceNumber 1;
BA_ "SigType" SG_ 2563243774 SequenceNumber 1;
BA_ "SigType" SG_ 2563243774 Byte1 1;
BA_ "SigType" SG_ 2563243774 Byte2 1;
BA_ "SigType" SG_ 2563243774 Byte3 1;
BA_ "SigType" SG_ 2563243774 Byte4 1;
BA_ "SigType" SG_ 2563243774 Byte5 1;
BA_ "SigType" SG_ 2563243774 Byte6 1;
BA_ "SigType" SG_ 2563243774 Byte7 1;
BA_ "SPN" SG_ 2364540158 ActlEngPrcntTorqueHighResolution 4154;
BA_ "SPN" SG_ 2364540158 EngTorqueMode 899;
BA_ "SigType" SG_ 2364540158 DriversDemandEngPercentTorque 1;
BA_ "SPN" SG_ 2364540158 DriversDemandEngPercentTorque 512;
BA_ "SigType" SG_ 2364540158 ActualEngPercentTorque 1;
BA_ "SPN" SG_ 2364540158 ActualEngPercentTorque 513;
BA_ "SigType" SG_ 2364540158 EngSpeed 1;
BA_ "SPN" SG_ 2364540158 EngSpeed 190;
BA_ "SPN" SG_ 2364540158 SrcAddrssOfCtrllngDvcForEngCtrl 1483;
BA_ "SPN" SG_ 2364540158 EngStarterMode 1675;
BA_ "SigType" SG_ 2364540158 EngDemandPercentTorque 1;
BA_ "SPN" SG_ 2364540158 EngDemandPercentTorque 2432;
BA_ "SigType" SG_ 2628517630 VS_VolumeName 9;
BA_ "SigType" SG_ 2628517630 GCD_PathName 9;
BA_ "SystemSignalLongSymbol" SG_ 2628452094 VS_RequestVolumeToPrepareForRemo "VS_RequestVolumeToPrepareForRemoval";
BA_ "SigType" SG_ 2628452094 VS_VolumeName 8;
BA_ "SigType" SG_ 2628452094 FDT_PathName 9;
BA_ "SigType" SG_ 2628452094 GA_PathName 9;
BA_ "SigType" SG_ 2628452094 CCD_PathName 9;
BA_ "SigType" SG_ 2628452094 SA_PathName 9;
BA_ "SigType" SG_ 2628452094 DF_PathName 9;
BA_ "SigType" SG_ 2628452094 OF_PathName 9;
BA_ "SigType" SG_ 2628452094 VI_VolumeName 9;
BA_ "SigType" SG_ 2563178238 ExtendedPortEstimatedFlow 1;
BA_ "SPN" SG_ 2563178238 ExtendedPortEstimatedFlow 2939;
BA_ "SigType" SG_ 2563178238 RetractPortEstimatedFlow 1;
BA_ "SPN" SG_ 2563178238 RetractPortEstimatedFlow 2940;
BA_ "SPN" SG_ 2563178238 ValveState 2932;
BA_ "SigType" SG_ 2563178238 FailSafeMode 4;
BA_ "SPN" SG_ 2563178238 FailSafeMode 2934;
BA_ "SPN" SG_ 2563178238 ValveLimitStatus 5193;
BA_ "SigType" SG_ 2563112702 ExtendedPortMeasuredFlow 1;
BA_ "SPN" SG_ 2563112702 ExtendedPortMeasuredFlow 2937;
BA_ "SigType" SG_ 2563112702 RetractPortMeasuredFlow 1;
BA_ "SPN" SG_ 2563112702 RetractPortMeasuredFlow 2938;
BA_ "SigType" SG_ 2563112702 ExtendedPortPressure 1;
BA_ "SPN" SG_ 2563112702 ExtendedPortPressure 2941;
BA_ "SigType" SG_ 2563112702 RetractPortPressure 1;
BA_ "SPN" SG_ 2563112702 RetractPortPressure 2942;
BA_ "SigType" SG_ 2563112702 ReturnPortPressure 1;
BA_ "SPN" SG_ 2563112702 ReturnPortPressure 2943;
BA_ "SPN" SG_ 2563112702 ValveLimitStatus 5192;
BA_ "SigType" SG_ 2563047166 PortFlowCmd 1;
BA_ "SPN" SG_ 2563047166 PortFlowCmd 2944;
BA_ "SPN" SG_ 2563047166 StateCmd 2933;
BA_ "SigType" SG_ 2563047166 FailSaveModeCmd 4;
BA_ "SPN" SG_ 2360213246 CurvatureCommand 5237;
BA_ "SigType" SG_ 2360213246 CurvatureCommand 1;
BA_ "SPN" SG_ 2360213246 CurvatureCommandStatus 5239;
BA_ "SigType" SG_ 2360213246 CurvatureCommandStatus 4;
BA_ "SPN" SG_ 2360147710 EstimatedCurvature 5238;
BA_ "SigType" SG_ 2360147710 EstimatedCurvature 1;
BA_ "SPN" SG_ 2360147710 MechanicalSystemLockout 5243;
BA_ "SigType" SG_ 2360147710 MechanicalSystemLockout 4;
BA_ "SPN" SG_ 2360147710 SteeringSystemReadiness 5242;
BA_ "SigType" SG_ 2360147710 SteeringSystemReadiness 4;
BA_ "SPN" SG_ 2360147710 SteeringInputPositionStatus 5241;
BA_ "SigType" SG_ 2360147710 SteeringInputPositionStatus 4;
BA_ "SPN" SG_ 2360147710 RequestResetCommandStatus 5240;
BA_ "SigType" SG_ 2360147710 RequestResetCommandStatus 4;
BA_ "SystemEnvVarLongSymbol" EV_ evCmdGetSupportedWideCharsLastCh "evCmdGetSupportedWideCharsLastChar";
BA_ "SystemEnvVarLongSymbol" EV_ evCmdGetSupportedWideCharsFirstC "evCmdGetSupportedWideCharsFirstChar";
BA_ "SystemEnvVarLongSymbol" EV_ evCmdGetSupportedWideCharsCodepl "evCmdGetSupportedWideCharsCodeplane";
BA_ "SystemEnvVarLongSymbol" EV_ evCmdGcCopyViewportToPictureValu "evCmdGcCopyViewportToPictureValue";
BA_ "SystemEnvVarLongSymbol" EV_ evCmdControlAudioDeviceOnTimeDur "evCmdControlAudioDeviceOnTimeDuration";
BA_ "SystemEnvVarLongSymbol" EV_ evCmdControlAudioDeviceOffTimeDu "evCmdControlAudioDeviceOffTimeDuration";
BA_ "SystemEnvVarLongSymbol" EV_ evCmdControlAudioDeviceNumOfActi "evCmdControlAudioDeviceNumOfActivation";
VAL_ 2365463294 Valve10ValveState 0 "Blocked" 1 "Extend" 2 "Retract" 3 "Floating" 14 "ErrorIndication" 15 "DoNotCare" ;
VAL_ 2365463294 Valve10FailSafeMode 0 "Block" 1 "Float" 2 "ErrorIndication" 3 "NotAvailable" ;
VAL_ 2365463294 Valve10LimitStatus 7 "Not available" 6 "Non-recoverable Fault" 5 "Reserver" 4 "Reserved" 3 "Limited Low" 2 "Limited High" 1 "Operator Limited" 0 "Not limited" ;
VAL_ 2365463550 Valve11ValveState 0 "Blocked" 1 "Extend" 2 "Retract" 3 "Floating" 14 "ErrorIndication" 15 "DoNotCare" ;
VAL_ 2365463550 Valve11FailSafeMode 0 "Block" 1 "Float" 2 "ErrorIndication" 3 "NotAvailable" ;
VAL_ 2365463550 Valve11LimitStatus 7 "Not available" 6 "Non-recoverable Fault" 5 "Reserver" 4 "Reserved" 3 "Limited Low" 2 "Limited High" 1 "Operator Limited" 0 "Not limited" ;
VAL_ 2365463806 Valve12ValveState 0 "Blocked" 1 "Extend" 2 "Retract" 3 "Floating" 14 "ErrorIndication" 15 "DoNotCare" ;
VAL_ 2365463806 Valve12FailSafeMode 0 "Block" 1 "Float" 2 "ErrorIndication" 3 "NotAvailable" ;
VAL_ 2365463806 Valve12LimitStatus 7 "Not available" 6 "Non-recoverable Fault" 5 "Reserver" 4 "Reserved" 3 "Limited Low" 2 "Limited High" 1 "Operator Limited" 0 "Not limited" ;
VAL_ 2365464062 Valve13ValveState 0 "Blocked" 1 "Extend" 2 "Retract" 3 "Floating" 14 "ErrorIndication" 15 "DoNotCare" ;
VAL_ 2365464062 Valve13FailSafeMode 0 "Block" 1 "Float" 2 "ErrorIndication" 3 "NotAvailable" ;
VAL_ 2365464062 Valve13LimitStatus 7 "Not available" 6 "Non-recoverable Fault" 5 "Reserver" 4 "Reserved" 3 "Limited Low" 2 "Limited High" 1 "Operator Limited" 0 "Not limited" ;
VAL_ 2365464318 Valve14ValveState 0 "Blocked" 1 "Extend" 2 "Retract" 3 "Floating" 14 "ErrorIndication" 15 "DoNotCare" ;
VAL_ 2365464318 Valve14FailSafeMode 0 "Block" 1 "Float" 2 "ErrorIndication" 3 "NotAvailable" ;
VAL_ 2365464318 Valve14LimitStatus 7 "Not available" 6 "Non-recoverable Fault" 5 "Reserver" 4 "Reserved" 3 "Limited Low" 2 "Limited High" 1 "Operator Limited" 0 "Not limited" ;
VAL_ 2365464574 Valve15ValveState 0 "Blocked" 1 "Extend" 2 "Retract" 3 "Floating" 14 "ErrorIndication" 15 "DoNotCare" ;
VAL_ 2365464574 Valve15FailSafeMode 0 "Block" 1 "Float" 2 "ErrorIndication" 3 "NotAvailable" ;
VAL_ 2365464574 Valve15LimitStatus 7 "Not available" 6 "Non-recoverable Fault" 5 "Reserver" 4 "Reserved" 3 "Limited Low" 2 "Limited High" 1 "Operator Limited" 0 "Not limited" ;
VAL_ 2365464830 Valve0LimitStatus 7 "Not available" 6 "Non-recoverable Fault" 5 "Reserver" 4 "Reserved" 3 "Limited Low" 2 "Limited High" 1 "Operator Limited" 0 "Not limited" ;
VAL_ 2365465086 Valve1LimitStatus 7 "Not available" 6 "Non-recoverable Fault" 5 "Reserver" 4 "Reserved" 3 "Limited Low" 2 "Limited High" 1 "Operator Limited" 0 "Not limited" ;
VAL_ 2365465342 Valve2LimitStatus 7 "Not available" 6 "Non-recoverable Fault" 5 "Reserver" 4 "Reserved" 3 "Limited Low" 2 "Limited High" 1 "Operator Limited" 0 "Not limited" ;
VAL_ 2365465598 Valve3LimitStatus 7 "Not available" 6 "Non-recoverable Fault" 5 "Reserver" 4 "Reserved" 3 "Limited Low" 2 "Limited High" 1 "Operator Limited" 0 "Not limited" ;
VAL_ 2365465854 Valve4LimitStatus 7 "Not available" 6 "Non-recoverable Fault" 5 "Reserver" 4 "Reserved" 3 "Limited Low" 2 "Limited High" 1 "Operator Limited" 0 "Not limited" ;
VAL_ 2365466110 Valve5LimitStatus 7 "Not available" 6 "Non-recoverable Fault" 5 "Reserver" 4 "Reserved" 3 "Limited Low" 2 "Limited High" 1 "Operator Limited" 0 "Not limited" ;
VAL_ 2365466366 Valve6LimitStatus 7 "Not available" 6 "Non-recoverable Fault" 5 "Reserver" 4 "Reserved" 3 "Limited Low" 2 "Limited High" 1 "Operator Limited" 0 "Not limited" ;
VAL_ 2365466622 Valve7LimitStatus 7 "Not available" 6 "Non-recoverable Fault" 5 "Reserver" 4 "Reserved" 3 "Limited Low" 2 "Limited High" 1 "Operator Limited" 0 "Not limited" ;
VAL_ 2365466878 Valve8LimitStatus 7 "Not available" 6 "Non-recoverable Fault" 5 "Reserver" 4 "Reserved" 3 "Limited Low" 2 "Limited High" 1 "Operator Limited" 0 "Not limited" ;
VAL_ 2365467134 Valve9LimitStatus 7 "Not available" 6 "Non-recoverable Fault" 5 "Reserver" 4 "Reserved" 3 "Limited Low" 2 "Limited High" 1 "Operator Limited" 0 "Not limited" ;
VAL_ 2365467390 Valve10LimitStatus 7 "Not available" 6 "Non-recoverable Fault" 5 "Reserver" 4 "Reserved" 3 "Limited Low" 2 "Limited High" 1 "Operator Limited" 0 "Not limited" ;
VAL_ 2365467646 Valve11LimitStatus 7 "Not available" 6 "Non-recoverable Fault" 5 "Reserver" 4 "Reserved" 3 "Limited Low" 2 "Limited High" 1 "Operator Limited" 0 "Not limited" ;
VAL_ 2365467902 Valve12LimitStatus 7 "Not available" 6 "Non-recoverable Fault" 5 "Reserver" 4 "Reserved" 3 "Limited Low" 2 "Limited High" 1 "Operator Limited" 0 "Not limited" ;
VAL_ 2365468158 Valve13LimitStatus 7 "Not available" 6 "Non-recoverable Fault" 5 "Reserver" 4 "Reserved" 3 "Limited Low" 2 "Limited High" 1 "Operator Limited" 0 "Not limited" ;
VAL_ 2365468414 Valve14LimitStatus 7 "Not available" 6 "Non-recoverable Fault" 5 "Reserver" 4 "Reserved" 3 "Limited Low" 2 "Limited High" 1 "Operator Limited" 0 "Not limited" ;
VAL_ 2365468670 Valve15LimitStatus 7 "Not available" 6 "Non-recoverable Fault" 5 "Reserver" 4 "Reserved" 3 "Limited Low" 2 "Limited High" 1 "Operator Limited" 0 "Not limited" ;
VAL_ 2365468926 Valve0StateCmd 0 "Block" 1 "Extend" 2 "Retract" 3 "Float" 15 "Reserved" ;
VAL_ 2365468926 Valve0FailSaveModeCmd 0 "Block" 1 "Float" 3 "DoNotCare" ;
VAL_ 2365469182 Valve1StateCmd 0 "Block" 1 "Extend" 2 "Retract" 3 "Float" 15 "Reserved" ;
VAL_ 2365469182 Valve1FailSaveModeCmd 0 "Block" 1 "Float" 3 "DoNotCare" ;
VAL_ 2365469438 Valve2StateCmd 0 "Block" 1 "Extend" 2 "Retract" 3 "Float" 15 "Reserved" ;
VAL_ 2365469438 Valve2FailSaveModeCmd 0 "Block" 1 "Float" 3 "DoNotCare" ;
VAL_ 2365469694 Valve3StateCmd 0 "Block" 1 "Extend" 2 "Retract" 3 "Float" 15 "Reserved" ;
VAL_ 2365469694 Valve3FailSaveModeCmd 0 "Block" 1 "Float" 3 "DoNotCare" ;
VAL_ 2365469950 Valve4StateCmd 0 "Block" 1 "Extend" 2 "Retract" 3 "Float" 15 "Reserved" ;
VAL_ 2365469950 Valve4FailSaveModeCmd 0 "Block" 1 "Float" 3 "DoNotCare" ;
VAL_ 2365470206 Valve5StateCmd 0 "Block" 1 "Extend" 2 "Retract" 3 "Float" 15 "Reserved" ;
VAL_ 2365470206 Valve5FailSaveModeCmd 0 "Block" 1 "Float" 3 "DoNotCare" ;
VAL_ 2365470462 Valve6StateCmd 0 "Block" 1 "Extend" 2 "Retract" 3 "Float" 15 "Reserved" ;
VAL_ 2365470462 Valve6FailSaveModeCmd 0 "Block" 1 "Float" 3 "DoNotCare" ;
VAL_ 2365470718 Valve7StateCmd 0 "Block" 1 "Extend" 2 "Retract" 3 "Float" 15 "Reserved" ;
VAL_ 2365470718 Valve7FailSaveModeCmd 0 "Block" 1 "Float" 3 "DoNotCare" ;
VAL_ 2365470974 Valve8StateCmd 0 "Block" 1 "Extend" 2 "Retract" 3 "Float" 15 "Reserved" ;
VAL_ 2365470974 Valve8FailSaveModeCmd 0 "Block" 1 "Float" 3 "DoNotCare" ;
VAL_ 2365471230 Valve9StateCmd 0 "Block" 1 "Extend" 2 "Retract" 3 "Float" 15 "Reserved" ;
VAL_ 2365471230 Valve9FailSaveModeCmd 0 "Block" 1 "Float" 3 "DoNotCare" ;
VAL_ 2365471486 Valve10StateCmd 0 "Block" 1 "Extend" 2 "Retract" 3 "Float" 15 "Reserved" ;
VAL_ 2365471486 Valve10FailSaveModeCmd 0 "Block" 1 "Float" 3 "DoNotCare" ;
VAL_ 2365471742 Valve11StateCmd 0 "Block" 1 "Extend" 2 "Retract" 3 "Float" 15 "Reserved" ;
VAL_ 2365471742 Valve11FailSaveModeCmd 0 "Block" 1 "Float" 3 "DoNotCare" ;
VAL_ 2365471998 Valve12StateCmd 0 "Block" 1 "Extend" 2 "Retract" 3 "Float" 15 "Reserved" ;
VAL_ 2365471998 Valve12FailSaveModeCmd 0 "Block" 1 "Float" 3 "DoNotCare" ;
VAL_ 2365472254 Valve13StateCmd 0 "Block" 1 "Extend" 2 "Retract" 3 "Float" 15 "Reserved" ;
VAL_ 2365472254 Valve13FailSaveModeCmd 0 "Block" 1 "Float" 3 "DoNotCare" ;
VAL_ 2365472510 Valve14StateCmd 0 "Block" 1 "Extend" 2 "Retract" 3 "Float" 15 "Reserved" ;
VAL_ 2365472510 Valve14FailSaveModeCmd 0 "Block" 1 "Float" 3 "DoNotCare" ;
VAL_ 2365472766 Valve15StateCmd 0 "Block" 1 "Extend" 2 "Retract" 3 "Float" 15 "Reserved" ;
VAL_ 2365472766 Valve15FailSaveModeCmd 0 "Block" 1 "Float" 3 "DoNotCare" ;
VAL_ 2566799614 DaytimeRunningLightData 0 "Deactivated" 1 "Activated" 2 "FaultDetected" 3 "NotAvailable" ;
VAL_ 2566799614 AlternateHeadLightData 0 "Deactivated" 1 "Activated" 2 "FaultDetected" 3 "NotAvailable" ;
VAL_ 2566799614 LowBeamHeadLightData 0 "Deactivated" 1 "Activated" 2 "Fault Detected" 3 "Not Available" ;
VAL_ 2566799614 HighBeamHeadLightData 0 "Deactivated" 1 "Activated" 2 "Fault Detected" 3 "Not Available" ;
VAL_ 2566799614 TractorFrontFogLightData 0 "Deactivated" 1 "Activated" 2 "FaultDetected" 3 "NotAvailable" ;
VAL_ 2566799614 RotationBeaconLightData 0 "Deactivated" 1 "Activated" 2 "FaultDetected" 3 "NotAvailable" ;
VAL_ 2566799614 RightTurnSignalLightData 0 "Deactivated" 1 "Activated" 2 "FaultDetected" 3 "NotAvailable" ;
VAL_ 2566799614 LeftTurnSignalLightData 0 "Deactivated" 1 "Activated" 2 "FaultDetected" 3 "NotAvailable" ;
VAL_ 2566799614 BackUpLightAndAlarmHornData 0 "Deactivated" 1 "Activated" 2 "FaultDetected" 3 "NotAvailable" ;
VAL_ 2566799614 CentreStopLightData 0 "Deactivated" 1 "Activated" 2 "FaultDetected" 3 "NotAvailable" ;
VAL_ 2566799614 RightStopLightData 0 "Deactivated" 1 "Activated" 2 "FaultDetected" 3 "NotAvailable" ;
VAL_ 2566799614 LefttStopLightData 0 "Deactivated" 1 "Activated" 2 "FaultDetected" 3 "NotAvailable" ;
VAL_ 2566799614 ImplementClearanceLightData 0 "Deactivated" 1 "Activated" 2 "FaultDetected" 3 "NotAvailable" ;
VAL_ 2566799614 TractorClearanceLightData 0 "Deactivated" 1 "Activated" 2 "FaultDetected" 3 "NotAvailable" ;
VAL_ 2566799614 ImplementMarkerLightData 0 "Deactivated" 1 "Activated" 2 "FaultDetected" 3 "NotAvailable" ;
VAL_ 2566799614 TractorMarkerLightData 0 "Deactivated" 1 "Activated" 2 "FaultDetected" 3 "NotAvailable" ;
VAL_ 2566799614 RearFogLightData 0 "Deactivated" 1 "Activated" 2 "FaultDetected" 3 "NotAvailable" ;
VAL_ 2566799614 TractorUndersideWorkLightData 0 "Deactivated" 1 "Activated" 2 "FaultDetected" 3 "NotAvailable" ;
VAL_ 2566799614 TractorRearLowWorkLightData 0 "Deactivated" 1 "Activated" 2 "FaultDetected" 3 "NotAvailable" ;
VAL_ 2566799614 TractorRearHighWorkLightData 0 "Deactivated" 1 "Activated" 2 "FaultDetected" 3 "NotAvailable" ;
VAL_ 2566799614 TractorSideLowWorkLightData 0 "Deactivated" 1 "Activated" 2 "FaultDetected" 3 "NotAvailable" ;
VAL_ 2566799614 TractorSideHighWorkLightData 0 "Deactivated" 1 "Activated" 2 "FaultDetected" 3 "NotAvailable" ;
VAL_ 2566799614 TractorFrontLowWorkLightData 0 "Deactivated" 1 "Activated" 2 "FaultDetected" 3 "NotAvailable" ;
VAL_ 2566799614 TractorFrontHighWorkLightData 0 "Deactivated" 1 "Activated" 2 "FaultDetected" 3 "NotAvailable" ;
VAL_ 2566799614 ImplementOEMOption2LightData 0 "Deactivated" 1 "Activated" 2 "FaultDetected" 3 "NotAvailable" ;
VAL_ 2566799614 ImplementOEMOption1LightData 0 "Deactivated" 1 "Activated" 2 "FaultDetected" 3 "NotAvailable" ;
VAL_ 2566799614 ImplementRightForwardLightData 0 "Deactivated" 1 "Activated" 2 "FaultDetected" 3 "NotAvailable" ;
VAL_ 2566799614 ImplementLeftForwardLightData 0 "Deactivated" 1 "Activated" 2 "FaultDetected" 3 "NotAvailable" ;
VAL_ 2566799614 ImplRightFacingWorkLightData 0 "Deactivated" 1 "Activated" 2 "FaultDetected" 3 "NotAvailable" ;
VAL_ 2566799614 ImplLeftFacingWorkLightData 0 "Deactivated" 1 "Activated" 2 "FaultDetected" 3 "NotAvailable" ;
VAL_ 2566799614 ImplementRearWorkLightData 0 "Deactivated" 1 "Activated" 2 "FaultDetected" 3 "NotAvailable" ;
VAL_ 2365473278 DaytimeRunningLightCmd 0 "Deactivate" 1 "Activate" 3 "DoNotCare" ;
VAL_ 2365473278 AlternateHeadLightCmd 0 "Deactivate" 1 "Activate" 3 "DoNotCare" ;
VAL_ 2365473278 LowBeamHeadLightCmd 2 "Reserved" 0 "Deactivate" 1 "Activate" 3 "Dont Care" ;
VAL_ 2365473278 HighBeamHeadLightCmd 2 "Reserved" 0 "Deactivate" 1 "Activate" 3 "Dont Care" ;
VAL_ 2365473278 TractorFrontFogLightCmd 0 "Deactivate" 1 "Activate" 3 "DoNotCare" ;
VAL_ 2365473278 RotatingBeaconLightCmd 3 "Dont Care" 2 "Reserved" 1 "Activate" 0 "Deactivate" ;
VAL_ 2365473278 RightTurnSignalLightCmd 0 "Deactivate" 1 "Activate" 3 "DoNotCare" ;
VAL_ 2365473278 LeftTurnSignalLightCmd 0 "Deactivate" 1 "Activate" 3 "DoNotCare" ;
VAL_ 2365473278 BackUpLightAndAlarmHornCmd 2 "Reserved" 0 "Deactivate" 1 "Activate" 3 "Dont Care" ;
VAL_ 2365473278 CentreStopLightCmd 0 "Deactivate" 1 "Acitvate" 3 "DoNotCare" ;
VAL_ 2365473278 RightStopLightCmd 3 "Dont Care" 2 "Reserved" 1 "Activate" 0 "Deactivate" ;
VAL_ 2365473278 LeftStopLightCmd 2 "Reserved" 0 "Deactivate" 1 "Activate" 3 "Dont Care" ;
VAL_ 2365473278 ImplementClearanceLightCmd 2 "Reserved" 0 "Deactivate" 1 "Activate" 3 "Dont Care" ;
VAL_ 2365473278 TractorClearanceLightCmd 2 "Reserved" 0 "Deactivate" 1 "Activate" 3 "Dont Care" ;
VAL_ 2365473278 ImplementMarkerLightCmd 2 "Reserved" 0 "Deactivate" 1 "Activate" 3 "Dont Care" ;
VAL_ 2365473278 TractorMarkerLightCmd 2 "Reserved" 0 "Deactivate" 1 "Activate" 3 "Dont Care" ;
VAL_ 2365473278 RearFogLightCmd 2 "Reserved" 0 "Deactivate" 1 "Activate" 3 "Dont Care" ;
VAL_ 2365473278 TractorUndersideWorkLightCmd 0 "Deactivate" 1 "Acitvate" 3 "DoNotCare" ;
VAL_ 2365473278 TractorRearLowWorkLightCmd 0 "Deactivate" 1 "Acitvate" 3 "DoNotCare" ;
VAL_ 2365473278 TractorRearHighWorkLightCmd 0 "Deactivate" 1 "Acitvate" 3 "DoNotCare" ;
VAL_ 2365473278 TractorSideLowWorkLightCmd 0 "Deactivate" 1 "Acitvate" 3 "DoNotCare" ;
VAL_ 2365473278 TractorSideHighWorkLightCmd 0 "Deactivate" 1 "Acitvate" 3 "DoNotCare" ;
VAL_ 2365473278 TractorFrontLowWorkLightCmd 0 "Deactivate" 1 "Acitvate" 3 "DoNotCare" ;
VAL_ 2365473278 TractorFrontHighWorkLightCmd 0 "Deactivate" 1 "Acitvate" 3 "DoNotCare" ;
VAL_ 2365473278 ImplementOEMOption2LightCmd 3 "Dont Care" 2 "Reserved" 1 "Activate" 0 "Deactivate" ;
VAL_ 2365473278 ImplementOEMOption1LightCmd 3 "Dont Care" 2 "Reserved" 1 "Activate" 0 "Deactivate" ;
VAL_ 2365473278 ImplementRightForwardLightCmd 0 "Deactivate" 1 "Acitvate" 3 "DoNotCare" ;
VAL_ 2365473278 ImplementLeftForwardLightCmd 0 "Deactivate" 1 "Acitvate" 3 "DoNotCare" ;
VAL_ 2365473278 LightingDataRequestCmd 0 "Deactivate" 1 "Acitvate" 3 "DoNotCare" ;
VAL_ 2365473278 ImplementRightFacingWorkLightCmd 3 "Dont Care" 2 "Reserved" 1 "Activate" 0 "Deactivate" ;
VAL_ 2365473278 ImplementLeftFacingWorkLightCmd 2 "Reserved" 0 "Deactivate" 1 "Activate" 3 "Dont Care" ;
VAL_ 2365473278 ImplementRearWorkLightCmd 3 "Dont Care" 2 "Reserved" 1 "Activate" 0 "Deactivate" ;
VAL_ 2365473534 RearPTOEngagementCmd 0 "DisengagePTO" 1 "EngangePTO" 3 "DoNotCare" ;
VAL_ 2365473534 FrontPTOEngagementCmd 0 "DisengagePTO" 1 "EngagePTO" 3 "DoNotCare" ;
VAL_ 2365473534 RearPTOEconomyModeCmd 0 "DisengagePTOEconomyMode" 1 "EngagePTOEconomyMode" 3 "DoNotCare" ;
VAL_ 2365473534 FrontPTOEconomyModeCmd 0 "DisengagePTOEconomyMode" 1 "EngagePTOEconomyMode" 3 "DoNotCare" ;
VAL_ 2365473534 RearPTOModeCmd 0 "Select540rpmMode" 1 "Select1000rpmMode" 3 "DoNotCare" ;
VAL_ 2365473534 FrontPTOModeCmd 0 "Select540rpmMode" 1 "Select1000rpmMode" 3 "DoNotCare" ;
VAL_ 2365473790 RearPTOEngagementRqStatus 3 "Not available" 2 "Error" 1 "Control Override" 0 "External Request accepted" ;
VAL_ 2365473790 RearPTOEconomyMode 0 "PTOEconomyModeIsDisengaged" 1 "PTOEconomyModeIsEngaged" 2 "ErrorIndication" 3 "NotAvailabel" ;
VAL_ 2365473790 RearPTOMode 0 "PTOModeIs540" 1 "PTOModeIs1000" 2 "ErrorIndication" 3 "NotAvailable" ;
VAL_ 2365473790 RearPTOEngagement 0 "PTODisengaged" 1 "PTOEngaged" 2 "ErrorIndication" 3 "NotAvailable" ;
VAL_ 2365473790 RearPTOShaftSpeedLimitStatus 7 "Not available" 6 "Non-recoverable Fault" 5 "Reserver" 4 "Reserved" 3 "Limited Low" 2 "Limited High" 1 "Operator Limited" 0 "Not limited" ;
VAL_ 2365473790 RearPTOEconomyModeRqStatus 3 "Not available" 2 "Error" 1 "Control Override" 0 "External Request accepted" ;
VAL_ 2365473790 RearPTOModeRqStatus 3 "Not available" 2 "Error" 1 "Control Override" 0 "External Request accepted" ;
VAL_ 2365474046 FrontPTOEngagementRqStatus 3 "Not available" 2 "Error" 1 "Control Override" 0 "External Request accepted" ;
VAL_ 2365474046 FrontPTOEconomyMode 0 "PTOEconomyModeIsDisengaged" 1 "PTOEconomyModeIsEngaged" 2 "ErrorIndication" 3 "NotAvailable" ;
VAL_ 2365474046 FrontPTOMode 0 "PTOModeIs540" 1 "PTOModeIs1000" 2 "ErrorIndication" 3 "NotAvailable" ;
VAL_ 2365474046 FrontPTOEngagement 0 "PTODisengaged" 1 "PTOEngaged" 2 "ErrorIndication" 3 "NotAvailable" ;
VAL_ 2365474046 FrontPTOShaftSpeedLimitStatus 7 "Not available" 6 "Non-recoverable Fault" 5 "Reserver" 4 "Reserved" 3 "Limited Low" 2 "Limited High" 1 "Operator Limited" 0 "Not limited" ;
VAL_ 2365474046 FrontPTOEconomyModeRqStatus 3 "Not available" 2 "Error" 1 "Control Override" 0 "External Request accepted" ;
VAL_ 2365474046 FrontPTOModeRqStatus 3 "Not available" 2 "Error" 1 "Control Override" 0 "External Request accepted" ;
VAL_ 2365474302 RearHitchPositionLimitStatus 7 "Not available" 6 "Non-recoverable Fault" 5 "Reserver" 4 "Reserved" 3 "Limited Low" 2 "Limited High" 1 "Operator Limited" 0 "Not limited" ;
VAL_ 2365474302 RearHitchInWorkIndication 0 "HitchPositionIsOutOfWork" 1 "HitchPositionIsInWork" 2 "ErrorIndication" 3 "NotAvailable" ;
VAL_ 2365474558 FrontHitchPositionLimitStatus 7 "Not available" 6 "Non-recoverable Fault" 5 "Reserver" 4 "Reserved" 3 "Limited Low" 2 "Limited High" 1 "Operator Limited" 0 "Not limited" ;
VAL_ 2365474558 FrontHitchInWorkIndication 0 "HitchPositionIsOutOfWork" 1 "HitchPositionIsInWorl" 2 "ErrorIndication" 3 "NotAvailable" ;
VAL_ 2566801406 MaintainActuatorPower 0 "NoFurtherRequirementForPWR" 1 "RequireForTwoMoreSecOfPWR" 3 "DoNotCare" ;
VAL_ 2566801406 MaintainECUPower 0 "NoFurtherRequireForECU_PWR" 1 "RequireForTwoMoreSecOfECU_PWR" 3 "DoNotCare" ;
VAL_ 2566801406 ImplementWorkState 0 "ImplementIsNotReadyForFieldWork" 1 "ImplementIsReadyForFieldWork" 2 "ErrorIndicator" 3 "NotAvailable" ;
VAL_ 2566801406 ImplementParkState 0 "ImplementMayNotBeDisconneted" 1 "ImplementMayBeDisconnected" 2 "ErrorIndicator" 3 "NotAvailable" ;
VAL_ 2566801406 ImplementTransportState 0 "ImplementMayNotBeTransported" 1 "ImplementMayBeTransported" 2 "ErrorIndication" 3 "NotAvailable" ;
VAL_ 2365475070 WheelBasedMachineDirection 0 "Reverse" 1 "Forward" 2 "ErrorIndicator" 3 "NotAvailable" ;
VAL_ 2365475070 KeySwitchState 0 "KeySwitchOff" 1 "KeySwitchNotOff" 2 "ErrorIndication" 3 "NotAvailable" ;
VAL_ 2365475070 StartStopState 0 "Stop or disable implement work" 1 "Start or enable implement work" 2 "Reserved" 3 "Don't Care" ;
VAL_ 2365475070 OperatorDirectionReversed 3 "Not available" 2 "Error" 1 "Reversed" 0 "Not reversed" ;
VAL_ 2365475326 GroundBasedMachineDirection 0 "Reverse" 1 "Forward" 2 "ErrorIndication" 3 "NotAvailable" ;
VAL_ 2566848766 ManufacturerSpecific1 255 "NotAvailable" ;
VAL_ 2566848766 ManufacturerSpecific2 255 "NotAvailable" ;
VAL_ 2566848766 ManufacturerSpecific3 255 "NotAvailable" ;
VAL_ 2566848766 ManufacturerSpecific4 255 "NotAvailable" ;
VAL_ 2566848766 ManufacturerSpecific5 255 "NotAvailable" ;
VAL_ 2566848766 ManufacturerSpecific6 255 "NotAvailable" ;
VAL_ 2566848766 ManufacturerSpecific7 255 "NotAvailable" ;
VAL_ 2566848766 ManufacturerSpecific8 255 "NotAvailable" ;
VAL_ 2566849022 ManufacturerSpecific1 255 "NotAvailable" ;
VAL_ 2566849022 ManufacturerSpecific2 255 "NotAvailable" ;
VAL_ 2566849022 ManufacturerSpecific3 255 "NotAvailable" ;
VAL_ 2566849022 ManufacturerSpecific4 255 "NotAvailable" ;
VAL_ 2566849022 ManufacturerSpecific5 255 "NotAvailable" ;
VAL_ 2566849022 ManufacturerSpecific6 255 "NotAvailable" ;
VAL_ 2566849022 ManufacturerSpecific7 255 "NotAvailable" ;
VAL_ 2566849022 ManufacturerSpecific8 255 "NotAvailable" ;
VAL_ 2566849278 ManufacturerSpecific1 255 "NotAvailable" ;
VAL_ 2566849278 ManufacturerSpecific2 255 "NotAvailable" ;
VAL_ 2566849278 ManufacturerSpecific3 255 "NotAvailable" ;
VAL_ 2566849278 ManufacturerSpecific4 255 "NotAvailable" ;
VAL_ 2566849278 ManufacturerSpecific5 255 "NotAvailable" ;
VAL_ 2566849278 ManufacturerSpecific6 255 "NotAvailable" ;
VAL_ 2566849278 ManufacturerSpecific7 255 "NotAvailable" ;
VAL_ 2566849278 ManufacturerSpecific8 255 "NotAvailable" ;
VAL_ 2566849534 ManufacturerSpecific1 255 "NotAvailable" ;
VAL_ 2566849534 ManufacturerSpecific2 255 "NotAvailable" ;
VAL_ 2566849534 ManufacturerSpecific3 255 "NotAvailable" ;
VAL_ 2566849534 ManufacturerSpecific4 255 "NotAvailable" ;
VAL_ 2566849534 ManufacturerSpecific5 255 "NotAvailable" ;
VAL_ 2566849534 ManufacturerSpecific6 255 "NotAvailable" ;
VAL_ 2566849534 ManufacturerSpecific7 255 "NotAvailable" ;
VAL_ 2566849534 ManufacturerSpecific8 255 "NotAvailable" ;
VAL_ 2583168510 TypeOfSystem 0 "GPS" 1 "GLONASS" 2 "GPS and GLONASS" 3 "GPS and SBAS(WAAS)" 4 "GPS and SBAS and GLONASS" ;
VAL_ 2583168510 GNSSMethod 0 "no GPS" 1 "GNSS fix" 2 "DGNSS fix" 3 "Precise GNSS" 4 "RTK fixed integer" 5 "RTK float" 6 "Estimated (DR) mode" 7 "Manual input" 8 "Simulate mode" 14 "Error" ;
VAL_ 2583168510 GNSSIntegrity 0 "No integrity checking" 1 "Safe" 2 "Caution" 3 "Unsafe" ;
VAL_ 2583168510 RefrenceStationType1 0 "GPS" 1 "GLONASS" 14 "Error" ;
VAL_ 2563309310 ConnectionAbortReason 7 "AnyOtherError" 6 "DuplicateSequenceNumber" 5 "BadSequenceNumber" 4 "UnexpectedDataTransferPacket" 3 "Timeout_CloseSession" 2 "NoFreeSystemResources" 1 "AlreadyInConnManagedSession" ;
VAL_ 2563309310 ControlByte 24 "EAbort" 23 "EEoMACK" 22 "EDPO" 21 "ECTS" 20 "ERTS" 255 "EAbort" ;
VAL_ 2563309310 PGNumber 255 "NotAvailable" ;
VAL_ 2364540158 ActlEngPrcntTorqueHighResolution 8 "1111  not available" 7 "0875" 1 "0125" 0 "0000" ;
VAL_ 2364540158 EngStarterMode 13 "error legacy implementation only use 1110" 11 "Reserved" 10 "starter inhibited due to active SCR inducement" 0 "start not requested" 1 "starter active gear not engaged" 2 "starter active gear engaged" 3 "start finished starter not active after having been actively engaged after 50ms mode goes to 0000" 4 "starter inhibited due to engine already running" 5 "starter inhibited due to engine not ready for start preheating" 6 "starter inhibited due to driveline engaged or other transmission inhibit" 7 "starter inhibited due to active immobilizer" 8 "starter inhibited due to starter overtemp" 9 "starter inhibited due to intake air shutoff valve being active" 12 "starter inhibited  reason unknown" 14 "error" 15 "not available" ;
VAL_ 2628517630 FSServerCommand 2 "VSVolumeStatusResponse" 1 "CMGetFileServerProperties" 64 "VHVolumeInitialization" 52 "FHGetFileDateTime" 17 "DHChangeCurrentDirectory" 51 "FHSetFileAttribute" 50 "FHGetFileAttributes" 49 "FHDeleteFile" 48 "FHMoveFile" 36 "FACloseFile" 35 "FAWriteFile" 34 "FAReadFile" 33 "FASeekFile" 32 "FAOpenFile" 16 "DHGetCurrentDirectory" 0 "CMFileServerStatus" ;
VAL_ 2628517630 VS_VolumeStatus 3 "Removed" 2 "PreparingForRemoval" 1 "InUse" 0 "Present" ;
VAL_ 2628517630 GSP_VersionNumber 255 "CompliantToVersion2AndPrior" 3 "FirstPublishedEditionAndAmd1OfIS" 2 "FirstPublishedEditionOfIS" 1 "FDIS" 0 "DIS" ;
VAL_ 2628517630 VI_ErrorCode 13 "Volume possibly not initialized" 11 "Failure during read operation" 10 "Media is not present" 43 "Out of memory" 44 "Any other error" 42 "Invalid request length" 9 "Failure during write operation" 8 "Volume out of free space" 6 "Invalid given source name" 4 "File, path or volume not found" 1 "Access Denied" 0 "Success" ;
VAL_ 2628517630 DF_ErrorCode 13 "Volume possibly not initialized" 11 "Failure during read operation" 9 "Failure during write operation" 43 "Out of memory" 44 "Any other error" 10 "Media is not present" 6 "Invalid given source name" 4 "File, path or volume not found" 1 "Access Denied" 0 "Success" ;
VAL_ 2628517630 CCD_ErrorCode 7 "Invalid destination name given" 4 "File, path or volume not found" 2 "Invalid Access" 1 "Access denied" 13 "Volume possibly not initialized" 43 "Out of memory" 44 "Any other error" 10 "Media is not present" 0 "Success" ;
VAL_ 2628517630 GCD_ErrorCode 13 "Volume possibly not initialized" 43 "Out of Memory" 44 "Any other error" 10 "Media is not present" 0 "Success" ;
VAL_ 2628517630 SA_ErrorCode 13 "Volume possibly not initialized" 11 "Failure during read operation" 43 "Out of memory" 44 "Any other error" 10 "Media is not present" 9 "Failure during write operation" 8 "Volume out of free space" 6 "Invalid given source name" 4 "File, path or volume not found" 3 "Too many files open" 1 "Access Denied" 0 "Success" ;
VAL_ 2628517630 GA_ErrorCode 13 "Volume possibly not initialized" 11 "Failure during read operation" 43 "Out of memory" 44 "Any other error" 10 "Media is not present" 6 "Invalid given source name" 4 "File, path or volume not found" 3 "Too many files open" 1 "Access Denied" 0 "Success" ;
VAL_ 2628517630 MF_ErrorCode 13 "Volume possibly not initialized" 4 "File, path or volume not found" 43 "Out of memory" 44 "Any other error" 10 "Media is not present" 9 "Verify failure during a write op" 8 "Volume out of free space" 7 "Invalid given destination name" 6 "Invalid given source name" 3 "Too many files open" 1 "Access Denied" 0 "Success" ;
VAL_ 2628517630 CF_ErrorCode 43 "Out ot memory" 44 "Any other error" 9 "Failure during a write operation" 8 "Volume out of free space" 5 "Invalid handle" 1 "Access Denied" 0 "Success" ;
VAL_ 2628517630 WF_ErrorCode 43 "Out of memory" 44 "Any other error" 42 "Invalid request length" 9 "Failure during a write operation" 8 "Volume out of free space" 5 "Invalid handle" 1 "Access Denied" 0 "Success" ;
VAL_ 2628517630 OF_ErrorCode 13 "Volume possibly not initialized" 43 "Out of memory" 44 "Any other error" 10 "Media is not present" 8 "Volume out of free space" 6 "Invalid given source name" 4 "File, path or volume not found" 3 "Too many files open" 2 "Invalid Access" 1 "Access Denied" 0 "Success" ;
VAL_ 2628517630 SF_ErrorCode 43 "Out of memory" 11 "Failure during read operation" 45 "File pointer at end of file" 44 "Any other error" 42 "Invalid request length" 5 "Invalid handle" 0 "Success" ;
VAL_ 2628517630 RF_ErrorCode 1 "Access denied" 43 "Out of memory" 11 "Failure during read operation" 0 "Success" 5 "Invalid handle" 42 "Invalid request length" 44 "Any other error" 45 "File pointer at end of file" ;
VAL_ 2628517630 FDT_ErrorCode 13 " Volume possibly not initialized" 11 "Failure during a read operation" 43 "Out ot memory" 44 "Any other error" 10 "Media is not present" 6 "Invalid given source name" 4 "File, path or volume not found" 3 "Too many files open" 1 "Access Denied" 0 "Success" ;
VAL_ 2628517630 GSP_SupportMultipleVolumes 0 "Beschreibung für den Wert '0'" ;
VAL_ 2628517630 GA_ATTR_ReadOnly 1 "'Read-only' attribute is set" 0 "'Read-only' attribute is not set" ;
VAL_ 2628517630 GA_ATTR_Hidden 1 "'Hidden' attribute is set" 0 "'Hidden' attribute is not set" ;
VAL_ 2628517630 GA_ATTR_VolSupportsHiddenAttr 1 "Volume supports hidden attribute" 0 "Volume not support hidden attr." ;
VAL_ 2628517630 GA_ATTR_IsVolume 1 "'System' attribute is set" 0 "'System' attribute is not set" ;
VAL_ 2628517630 VI_ATTR_Directory 1 "Handle specifies a directory" 0 "Handle does not specify a dir" ;
VAL_ 2628517630 GA_ATTR_SupportsLongFilenames 1 "Volume supports long filenames" 0 "Volume supports no long filename" ;
VAL_ 2628517630 GA_ATTR_VolumeRemovable 1 "Volume is not removable" 0 "Volume is removable" ;
VAL_ 2628452094 FSClientCommand 2 "VSVolumeStatusRequest" 1 "CMGetFileServerProperties" 64 "VHVolumeInitialization" 52 "FHGetFileDateTime" 17 "DHChangeCurrentDirectory" 51 "FHSetFileAttributes" 50 "FHGetFileAttributes" 49 "FHDeleteFile" 48 "FHMoveFile" 36 "FACloseFile" 35 "FAWriteFile" 34 "FAReadFile" 33 "FASeekFile" 32 "FAOpenFile" 16 "DHGetCurrentDirectory" 0 "CMConnectionMaintenance" ;
VAL_ 2628452094 CM_VersionNumber 255 "CompliantToVersion2AndPrior" 3 "FirstPublishedEditionAndAmd1OfIS" 2 "FirstPublishedEditionOfIS" 1 "FDIS" 0 "DIS" ;
VAL_ 2628452094 VS_ReportVolumeUsedByClient 1 "ReportVolumeInUseByClient" 0 "ReportVolumeNotInUseByClient" ;
VAL_ 2628452094 VS_RequestVolumeToPrepareForRemo 1 "RequestVolumeToPrepareForRemoval" ;
VAL_ 2628452094 DF_DeleteMode 1 "'copy' mode is set" 0 "'copy' mode is not set" ;
VAL_ 2628452094 MF_MoveModeCopy 1 "'copy' mode is set" 0 "'copy' mode is not set" ;
VAL_ 2628452094 OF_FlagReadWrite 3 "Open directory for reading" 2 "Open file for reading & writing" 1 "Open file for writing only" 0 "Open file for reading only" ;
VAL_ 2628452094 SET_ATTR_ReadOnly 3 "Leave 'read-only' attribute" 2 "Reserved" 1 "Set 'read-only' attribute" 0 "Clear 'read-only' attribute" ;
VAL_ 2628452094 DF_DeleteModeForce 1 "'force' mode is set" 0 "'force' mode is not set" ;
VAL_ 2628452094 MF_MoveModeForce 1 "'force' mode is set" 0 "'force' mode is not set" ;
VAL_ 2628452094 DF_DeleteModeRecursive 1 "'recursive' mode is set" 0 "'recursive' mode is not set" ;
VAL_ 2628452094 MF_MoveModeRecursive 1 "'recursive' mode is set" 0 "'recursive' mode is not set" ;
VAL_ 2628452094 OF_FlagCreateNew 1 "Create new file if not existing" 0 "Open an existing file" ;
VAL_ 2628452094 SET_ATTR_Hidden 3 "Leave 'hidden' attribute" 2 "Reserved" 1 "Set 'hidden' attribute" 0 "Clear 'hidden' attribute" ;
VAL_ 2628452094 OF_FlagAppend 1 "Open file for appending data" 0 "Open file for random access" ;
VAL_ 2628452094 OF_FlagExclusiveAccess 1 "Open file with exclusive access" 0 "Open file for shared read access" ;
VAL_ 2628452094 SF_PositionMode 2 "From the end of the file" 1 "From the current pointer pos" 0 "From the beginning of the file" ;
VAL_ 2628452094 RF_ReportHiddenFiles 255 "NotAvailable" 1 "ReportHiddenFiles" 0 "DoNotReportHiddenFiles" ;
VAL_ 2563178238 ValveState 0 "Blocked" 1 "Extend" 2 "Retract" 3 "Floating" 14 "ErrorIndication" 15 "DoNotCare" ;
VAL_ 2563178238 FailSafeMode 0 "Block" 1 "Float" 2 "ErrorIndication" 3 "NotAvailable" ;
VAL_ 2563178238 ValveLimitStatus 7 "Not available" 6 "Non-recoverable Fault" 5 "Reserver" 4 "Reserved" 3 "Limited Low" 2 "Limited High" 1 "Operator Limited" 0 "Not limited" ;
VAL_ 2563112702 ValveLimitStatus 7 "Not available" 6 "Non-recoverable Fault" 5 "Reserver" 4 "Reserved" 3 "Limited Low" 2 "Limited High" 1 "Operator Limited" 0 "Not limited" ;
VAL_ 2563047166 StateCmd 0 "Block" 1 "Extend" 2 "Retract" 3 "Float" 15 "Reserved" ;
VAL_ 2563047166 FailSaveModeCmd 0 "Block" 1 "Float" 3 "DoNotCare" ;
VAL_ 2360213246 CurvatureCommandStatus 0 "NotIntendedToSteer" 1 "IntendedToSteer" 2 "Error" 3 "NotAvailable" ;
VAL_ 2360147710 MechanicalSystemLockout 0 "NotActive" 1 "Active" 2 "Error" 3 "NotAvailable" ;
VAL_ 2360147710 SteeringSystemReadiness 0 "SystemIsNotReady" 1 "SystemIsReady" 2 "Error" 3 "NotAvailable" ;
VAL_ 2360147710 SteeringInputPositionStatus 0 "NotTheCorrectPosition" 1 "CorrectPosition" 2 "Error" 3 "NotAvailable" ;
VAL_ 2360147710 RequestResetCommandStatus 0 "ResetNotRequired" 1 "ResetRequired" 2 "Error" 3 "NotAvailable" ;
VAL_ evOPCVTVersion 5 "Compatible with VT Version 5" 4 "Compatible with VT Version 4" 3 "Compatible with VT Version 3" 2 "Compatible with VT Version 2" ;
VAL_ evCmdShow 1 "Show" 0 "Hide" ;
VAL_ evCmdSelectSelectionType 2 "Edit" 1 "Select" 0 "Remove selection" ;
VAL_ evCmdLockUnlockMaskType 1 "Lock" 0 "Unlock" ;
VAL_ evCmdEnable 1 "Enable" 0 "Disable" ;
VAL_ evCmdDeleteObjectPool 1 "Enable" 0 "Disable" ;
VAL_ evCmdChangeSoftMaskType 2 "Alarm Mask" 1 "Data Mask" ;
VAL_ evCmdChangeFillType 3 "Fill with pattern" 2 "Fill with fill colour" 1 "Fill with line colour" 0 "No fill" ;
VAL_ evCmdChangeEndPointDirection 1 "BottomLeft-TopRight" 0 "TopLeft-BottomRight" ;
